VERSION "created by canmatrix"

NS_ :

BS_:

BU_: RadarRearRight RadarRearLeft

BO_ 3221225472 VECTOR__INDEPENDENT_SIG_MSG: 0 Vector__XXX
 SG_ RRL_Status_SensorState : 0|2@0+ (1,0) [0|3] "" Vector__XXX
 SG_ RR_Object_Alivecounter : 0|4@1- (1,0) [0|15] "" Vector__XXX
 SG_ RSDS_RiTgt_02 : 0|1@1+ (1,0) [0|1] "" Vector__XXX
 SG_ RSDS_RiTgt_01 : 0|1@1+ (1,0) [0|1] "" Vector__XXX
 SG_ RSDS_MidTgt_02 : 0|1@1+ (1,0) [0|1] "" Vector__XXX
 SG_ RSDS_MidTgt_01 : 0|1@1+ (1,0) [0|1] "" Vector__XXX
 SG_ RSDS_RiTgt_02_dy : 0|7@1+ (0.1,-8) [-8|4.7] "m" Vector__XXX
 SG_ RSDS_RiTgt_02_dx : 0|10@1+ (0.1,-90) [-90|12.3] "m" Vector__XXX
 SG_ RSDS_RiTgt_01_dy : 0|7@1+ (0.1,-8) [-8|4.7] "m" Vector__XXX
 SG_ RSDS_RiTgt_01_dx : 0|10@1+ (0.1,-90) [-90|12.3] "m" Vector__XXX
 SG_ RSDS_MidTgt_02_dy : 0|7@1+ (0.1,-4) [-4|8.7] "m" Vector__XXX
 SG_ RSDS_MidTgt_02_dx : 0|10@1+ (0.1,-90) [-90|12.3] "m" Vector__XXX
 SG_ RSDS_MidTgt_01_dy : 0|7@1+ (0.1,-4) [-4|8.7] "m" Vector__XXX
 SG_ RSDS_MidTgt_01_dx : 0|10@1+ (0.1,-90) [-90|12.3] "m" Vector__XXX
 SG_ New_Signal_2741 : 0|8@1+ (1,0) [0|0] "" Vector__XXX
 SG_ New_Signal_2740 : 0|8@1+ (1,0) [0|0] "" Vector__XXX
 SG_ New_Signal_2739 : 0|8@1+ (1,0) [0|0] "" Vector__XXX
 SG_ New_Signal_2738 : 0|8@1+ (1,0) [0|0] "" Vector__XXX
 SG_ New_Signal_2737 : 0|8@1+ (1,0) [0|0] "" Vector__XXX
 SG_ New_Signal_2736 : 0|8@1+ (1,0) [0|0] "" Vector__XXX
 SG_ New_Signal_2735 : 0|8@1+ (1,0) [0|0] "" Vector__XXX
 SG_ New_Signal_2734 : 0|8@1+ (1,0) [0|0] "" Vector__XXX
 SG_ New_Signal_2733 : 0|8@1+ (1,0) [0|0] "" Vector__XXX

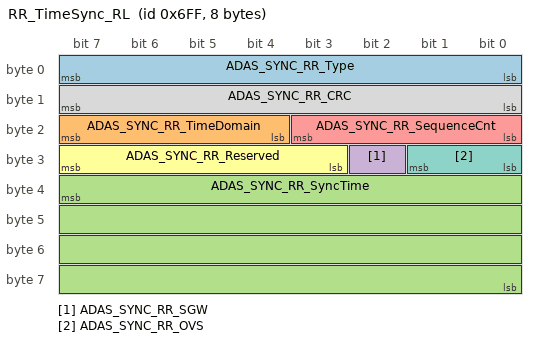
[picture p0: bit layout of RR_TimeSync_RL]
BO_ 1791 RR_TimeSync_RL: 8 RadarRearRight
 SG_ ADAS_SYNC_RR_Type : 7|8@0+ (1,0) [0|255] ""  RadarRearLeft
 SG_ ADAS_SYNC_RR_TimeDomain : 23|4@0+ (1,0) [0|15] ""  RadarRearLeft
 SG_ ADAS_SYNC_RR_SyncTime : 39|32@0+ (1,0) [0|4294967295] ""  RadarRearLeft
 SG_ ADAS_SYNC_RR_SGW : 26|1@0+ (1,0) [0|1] ""  RadarRearLeft
 SG_ ADAS_SYNC_RR_SequenceCnt : 19|4@0+ (1,0) [0|14] ""  RadarRearLeft
 SG_ ADAS_SYNC_RR_Reserved : 31|5@0+ (1,0) [0|31] ""  RadarRearLeft
 SG_ ADAS_SYNC_RR_OVS : 25|2@0+ (1,0) [0|3] ""  RadarRearLeft
 SG_ ADAS_SYNC_RR_CRC : 15|8@0+ (1,0) [0|255] ""  RadarRearLeft

BO_ 769 RRL_Object: 64 RadarRearLeft
 SG_ RSDS_RCW_MidTgt_01_Vy : 384|9@1+ (0.5,-127.5) [-127|128] "kph"  RadarRearRight
 SG_ RSDS_RCW_MidTgt_01_Vx : 368|9@1+ (0.5,-127.5) [-127|128] "kph"  RadarRearRight
 SG_ RSDS_RCW_MidTgt_01_Type : 125|3@1+ (1,0) [0|7] ""  RadarRearRight
 SG_ RSDS_RCTB_MidTgt_02_Vy : 352|9@1+ (0.5,-127.5) [-127|128] "kph"  RadarRearRight
 SG_ RSDS_RCTB_MidTgt_02_Vx : 336|9@1+ (0.5,-127.5) [-127|128] "kph"  RadarRearRight
 SG_ RSDS_RCTB_MidTgt_02_Type : 122|3@1+ (1,0) [0|7] ""  RadarRearRight
 SG_ RSDS_RCTA_LeTgt_02_Vy : 320|9@1+ (0.5,-127.5) [-127|128] "kph"  RadarRearRight
 SG_ RSDS_RCTA_LeTgt_02_Vx : 304|9@1+ (0.5,-127.5) [-127|128] "kph"  RadarRearRight
 SG_ RSDS_RCTA_LeTgt_02_Type : 109|3@1+ (1,0) [0|7] ""  RadarRearRight
 SG_ RSDS_LCA_LeTgt_01_Vy : 288|9@1+ (0.5,-127.5) [-127|128] "kph"  RadarRearRight
 SG_ RSDS_LCA_LeTgt_01_Vx : 272|9@1+ (0.5,-127.5) [-127|128] "kph"  RadarRearRight
 SG_ RSDS_LCA_LeTgt_01_Type : 37|3@1+ (1,0) [0|7] ""  RadarRearRight
 SG_ RSDS_MidTgt_01_dy_L : 235|7@1+ (0.1,-4) [-4|4] "m"  RadarRearRight
 SG_ RSDS_MidTgt_01_dx_L : 246|10@1+ (0.1,-90) [-90|5] "m"  RadarRearRight
 SG_ RSDS_MidTgt_01_L : 36|1@1+ (1,0) [0|1] "NoUnit"  RadarRearRight
 SG_ RCTA_B__L__TTC : 229|6@1+ (0.1,0) [0|6.3] "s"  RadarRearRight
 SG_ RCTB_L_State : 225|3@1+ (1,0) [0|7] "NoUnit"  RadarRearRight
 SG_ RCTA_L_State : 220|3@1+ (1,0) [0|7] "NoUnit"  RadarRearRight
 SG_ RCW_L_State : 203|3@1+ (1,0) [0|7] "NoUnit"  RadarRearRight
 SG_ DOW_L_State : 196|3@1+ (1,0) [0|7] "NoUnit"  RadarRearRight
 SG_ LCA_L_State : 188|3@1+ (1,0) [0|7] "NoUnit"  RadarRearRight
 SG_ BSD_L_State : 184|3@1+ (1,0) [0|7] "NoUnit"  RadarRearRight
 SG_ RSDS_ObjRelVelYStd_Le : 261|5@1+ (0.375,0) [0|11.625] ""  RadarRearRight
 SG_ RSDS_ObjRAccelYStd_Le : 75|5@1+ (0.375,0) [0|11.625] ""  RadarRearRight
 SG_ RSDS_ObjRAccelXStd_Le : 66|5@1+ (0.375,0) [0|11.625] ""  RadarRearRight
 SG_ RSDS_ObjRelAccelY_Le : 208|10@1+ (0.03125,-16) [-16|15.96875] ""  RadarRearRight
 SG_ RSDS_ObjRelAccelX_Le : 168|10@1+ (0.03125,-16) [-16|15.96875] ""  RadarRearRight
 SG_ RSDS_ObjRelVelXStd_Le : 152|5@1+ (0.375,0) [0|11.625] ""  RadarRearRight
 SG_ RSDS_ObjDistYStd_Le : 128|5@1+ (0.375,0) [0|11.625] ""  RadarRearRight
 SG_ RSDS_ObjDistXStd_Le : 104|5@1+ (0.375,0) [0|11.625] ""  RadarRearRight
 SG_ RSDS_LeTgt_02 : 35|1@1+ (1,0) [0|1] ""  RadarRearRight
 SG_ RSDS_LeTgt_01 : 34|1@1+ (1,0) [0|1] ""  RadarRearRight
 SG_ RSDS_LeTgt_02_dy : 80|7@1+ (0.1,0) [0|12.7] "m"  RadarRearRight
 SG_ RSDS_LeTgt_02_dx : 56|10@1+ (0.1,-90) [-90|12.3] "m"  RadarRearRight
 SG_ RSDS_LeTgt_01_dy : 40|7@1+ (0.1,0) [0|12.7] "m"  RadarRearRight
 SG_ RSDS_LeTgt_01_dx : 24|10@1+ (0.1,-90) [-90|12.3] "m"  RadarRearRight
 SG_ RRL_Status_Alivecounter : 16|8@1+ (1,0) [0|254] ""  RadarRearRight
 SG_ RRL_Status_CRC : 0|16@1+ (1,0) [0|65535] ""  RadarRearRight
 SG_ ZoneIndLe : 200|2@1+ (1,0) [0|3] ""  RadarRearRight
 SG_ ObjWidthLe : 242|3@1+ (0.5,0) [0|3.5] "m"  RadarRearRight
 SG_ ObjTTCLe : 161|7@1+ (0.1,0) [0|12.7] "s"  RadarRearRight
 SG_ ObjStsLe : 193|2@1+ (1,0) [0|3] ""  RadarRearRight
 SG_ ObjStatyLe : 207|1@1+ (1,0) [0|1] ""  RadarRearRight
 SG_ ObjLgtSpdCurvLe : 136|10@1+ (0.1,-10) [-10|92.3] "m/s"  RadarRearRight
 SG_ ObjLgtPosnCurvLe : 112|10@1+ (0.1,-92.3) [-92.3|10] "m"  RadarRearRight
 SG_ ObjLenLe : 178|4@1+ (1,0) [0|15] "m"  RadarRearRight
 SG_ ObjLatSpdCurvLe : 96|7@1+ (0.1,-6.4) [-6.4|6.3] "m/s"  RadarRearRight
 SG_ ObjLatPosnCurvLe : 88|8@1+ (0.1,-12.8) [-12.8|12.7] "m"  RadarRearRight
 SG_ ObjIDLe : 48|6@1+ (1,0) [0|63] ""  RadarRearRight
 SG_ LeTarSts : 73|2@1+ (1,0) [0|3] ""  RadarRearRight

BO_ 768 RRL_Hdr: 32 Vector__XXX
 SG_ RRL_Hdr_CRC : 0|16@1+ (1,0) [0|65535] "" Vector__XXX
 SG_ RRL_Hdr_YawAngleUpper : 105|15@1+ (0.00017,-2.78528) [-1.6|1.6] "rad" Vector__XXX
 SG_ RRL_Hdr_YawMountAngle : 120|16@1+ (0.00017,-5.57056) [-3.2|3.2] "rad" Vector__XXX
 SG_ RRL_Hdr_YawAngleLower : 136|15@1+ (0.00017,-2.78528) [-1.6|1.6] "rad" Vector__XXX
 SG_ RRL_Hdr_ElevOutOfSpec : 151|1@1+ (1,0) [0|1] "" Vector__XXX
 SG_ RRL_Hdr_PitchMountAngle : 152|12@1+ (0.00017,-0.34816) [-0.2|0.2] "rad" Vector__XXX
 SG_ RRL_Hdr_PitchAngleLower : 164|12@1+ (0.00017,-0.34816) [-0.2|0.2] "rad" Vector__XXX
 SG_ RRL_Hdr_AliveCtr : 16|8@1+ (1,0) [0|254] "" Vector__XXX
 SG_ RRL_Hdr_PitchAngleUpper : 176|12@1+ (0.00017,-0.34816) [-0.2|0.2] "rad" Vector__XXX
 SG_ RRL_Hdr_RollMountAngle : 188|12@1+ (0.00017,-0.34816) [-0.2|0.2] "rad" Vector__XXX
 SG_ RRL_Hdr_DetectionRange : 200|9@1+ (1,0) [0|511] "m" Vector__XXX
 SG_ RRL_Hdr_SensorState : 209|4@1+ (1,0) [0|15] "" Vector__XXX
 SG_ RRL_Hdr_FV : 231|8@0+ (1,0) [0|255] "" Vector__XXX
 SG_ RRL_Hdr_MAC : 239|24@0+ (1,0) [0|16777215] "" Vector__XXX
 SG_ RRL_Hdr_BlockCtr : 24|4@1+ (1,0) [0|15] "" Vector__XXX
 SG_ RRL_Hdr_ProtocolVersion : 32|16@1+ (1,0) [0|65535] "" Vector__XXX
 SG_ RRL_Hdr_ObjectCount : 48|6@1+ (1,0) [0|63] "" Vector__XXX
 SG_ RRL_Hdr_TimeSyncFailure : 54|1@1+ (1,0) [0|1] "" Vector__XXX
 SG_ RRL_Hdr_ObjectDownSel : 55|1@1+ (1,0) [0|1] "" Vector__XXX
 SG_ RRL_Hdr_MountingPosY : 56|8@1+ (0.01,-1.28) [-1.28|1.27] "m" Vector__XXX
 SG_ RRL_Hdr_AbsRefTime : 64|26@1+ (0.001,0) [0|65536] "s" Vector__XXX
 SG_ RRL_Hdr_MountingPosZ : 90|5@1+ (0.05,0) [0|1.55] "m" Vector__XXX
 SG_ RRL_Hdr_AziOutOfSpec : 95|1@1+ (1,0) [0|1] "" Vector__XXX
 SG_ RRL_Hdr_MountingPosX : 96|9@1+ (0.02,-5.12) [-5.12|5.1] "m" Vector__XXX

BO_ 784 RRL_Obj00A: 64 Vector__XXX
 SG_ RRL_Obj00A_CRC : 0|16@1+ (1,0) [0|65535] "" Vector__XXX
 SG_ RRL_Obj00A_Ay : 103|9@1+ (0.0625,-16) [-16|15.9375] "m/s^2" Vector__XXX
 SG_ RRL_Obj00A_HeadingYawAngle : 112|9@1+ (0.0175,-4.48) [-3.15|3.15] "rad" Vector__XXX
 SG_ RRL_Obj00A_Length : 121|7@1+ (0.125,0) [0|15.875] "m" Vector__XXX
 SG_ RRL_Obj00A_Width : 128|7@1+ (0.125,0) [0|15.875] "m" Vector__XXX
 SG_ RRL_Obj00A_Height : 135|7@1+ (0.125,0) [0|15.875] "m" Vector__XXX
 SG_ RRL_Obj00A_DxVnce : 142|12@1+ (0.01,0) [0|30] "m^2" Vector__XXX
 SG_ RRL_Obj00A_DyVnce : 154|12@1+ (0.01,0) [0|30] "m^2" Vector__XXX
 SG_ RRL_Obj00A_DzVnce : 166|10@1+ (0.01,0) [0|10] "m^2" Vector__XXX
 SG_ RRL_Obj00A_AliveCtr : 16|8@1+ (1,0) [0|254] "" Vector__XXX
 SG_ RRL_Obj00A_VxVnce : 176|12@1+ (0.01,0) [0|30] "m^2/s^2" Vector__XXX
 SG_ RRL_Obj00A_VyVnce : 188|12@1+ (0.01,0) [0|30] "m^2/s^2" Vector__XXX
 SG_ RRL_Obj00A_AxVnce : 200|12@1+ (0.01,0) [0|30] "m^2/s^4" Vector__XXX
 SG_ RRL_Obj00A_AyVnce : 212|12@1+ (0.01,0) [0|30] "m^2/s^4" Vector__XXX
 SG_ RRL_Obj00A_RefPosIndex : 224|4@1+ (1,0) [0|15] "" Vector__XXX
 SG_ RRL_Obj00A_DxDyCoVnce : 228|12@1+ (0.01,0) [0|30] "m^2" Vector__XXX
 SG_ RRL_Obj00A_DxVxCoVnce : 240|12@1+ (0.01,0) [0|30] "m^2/s" Vector__XXX
 SG_ RRL_Obj00A_BlockCtr : 24|4@1+ (1,0) [0|15] "" Vector__XXX
 SG_ RRL_Obj00A_DyVxCoVnce : 252|12@1+ (0.01,0) [0|30] "m^2/s" Vector__XXX
 SG_ RRL_Obj00A_DxVyCoVnce : 264|12@1+ (0.01,0) [0|30] "m^2/s" Vector__XXX
 SG_ RRL_Obj00A_DyVyCoVnce : 276|12@1+ (0.01,0) [0|30] "m^2/s" Vector__XXX
 SG_ RRL_Obj00A_VxVyCoVnce : 288|12@1+ (0.01,0) [0|30] "m^2/s^2" Vector__XXX
 SG_ RRL_Obj00A_DxAxCoVnce : 300|12@1+ (0.01,0) [0|30] "m^2/s^2" Vector__XXX
 SG_ RRL_Obj00A_DyAxCoVnce : 312|12@1+ (0.01,0) [0|30] "m^2/s^2" Vector__XXX
 SG_ RRL_Obj00A_VxAxCoVnce : 324|12@1+ (0.01,0) [0|30] "m^2/s^3" Vector__XXX
 SG_ RRL_Obj00A_ObjectID : 32|7@1+ (1,0) [0|127] "" Vector__XXX
 SG_ RRL_Obj00A_VyAxCoVnce : 336|12@1+ (0.01,0) [0|30] "m^2/s^3" Vector__XXX
 SG_ RRL_Obj00A_DxAyCoVnce : 348|12@1+ (0.01,0) [0|30] "m^2/s^2" Vector__XXX
 SG_ RRL_Obj00A_DyAyCoVnce : 360|12@1+ (0.01,0) [0|30] "m^2/s^2" Vector__XXX
 SG_ RRL_Obj00A_VxAyCoVnce : 372|12@1+ (0.01,0) [0|30] "m^2/s^3" Vector__XXX
 SG_ RRL_Obj00A_VyAyCoVnce : 384|12@1+ (0.01,0) [0|30] "m^2/s^3" Vector__XXX
 SG_ RRL_Obj00A_AxAyCoVnce : 396|12@1+ (0.01,0) [0|30] "m^2/s^4" Vector__XXX
 SG_ RRL_Obj00A_Measured : 39|1@1+ (1,0) [0|1] "" Vector__XXX
 SG_ RRL_Obj00A_HeadingYawVnce : 408|12@1+ (0.0003,0) [0|1] "rad^2" Vector__XXX
 SG_ RRL_Obj00A_Dx : 40|13@1+ (0.0625,-256) [-256|255.9375] "m" Vector__XXX
 SG_ RRL_Obj00A_LengthVnce : 420|12@1+ (0.01,0) [0|30] "m^2" Vector__XXX
 SG_ RRL_Obj00A_WidthVnce : 432|12@1+ (0.01,0) [0|30] "m^2" Vector__XXX
 SG_ RRL_Obj00A_HeightVnce : 444|12@1+ (0.01,0) [0|30] "m^2" Vector__XXX
 SG_ RRL_Obj00A_ExistProb : 456|6@1+ (2,0) [0|100] "%" Vector__XXX
 SG_ RRL_Obj00A_ProbObstacle : 462|6@1+ (2,0) [0|100] "%" Vector__XXX
 SG_ RRL_Obj00A_ProbNonObstacle : 468|6@1+ (2,0) [0|100] "%" Vector__XXX
 SG_ RRL_Obj00A_ProbMobileObst : 474|6@1+ (2,0) [0|100] "%" Vector__XXX
 SG_ RRL_Obj00A_FV : 487|8@0+ (1,0) [0|255] "" Vector__XXX
 SG_ RRL_Obj00A_MAC : 495|24@0+ (1,0) [0|16777215] "" Vector__XXX
 SG_ RRL_Obj00A_Dz : 53|6@1+ (0.25,-5) [-5|10.75] "m" Vector__XXX
 SG_ RRL_Obj00A_Dy : 59|11@1+ (0.125,-128) [-128|127.875] "m" Vector__XXX
 SG_ RRL_Obj00A_Valid : 70|1@1+ (1,0) [0|1] "" Vector__XXX
 SG_ RRL_Obj00A_Vx : 71|12@1+ (0.0625,-128) [-128|127.9375] "m/s" Vector__XXX
 SG_ RRL_Obj00A_Vy : 83|10@1+ (0.125,-64) [-64|63.875] "m/s" Vector__XXX
 SG_ RRL_Obj00A_Ax : 93|10@1+ (0.03125,-16) [-16|15.96875] "m/s^2" Vector__XXX

BO_ 785 RRL_Obj00B: 16 Vector__XXX
 SG_ RRL_Obj00B_CRC : 0|16@1+ (1,0) [0|65535] "" Vector__XXX
 SG_ RRL_Obj00B_MAC : 111|24@0+ (1,0) [0|16777215] "" Vector__XXX
 SG_ RRL_Obj00B_AliveCtr : 16|8@1+ (1,0) [0|254] "" Vector__XXX
 SG_ RRL_Obj00B_BlockCtr : 24|4@1+ (1,0) [0|15] "" Vector__XXX
 SG_ RRL_Obj00B_ProbMob4PlusWhl : 28|6@1+ (2,0) [0|100] "%" Vector__XXX
 SG_ RRL_Obj00B_ProbMob2Whl : 34|6@1+ (2,0) [0|100] "%" Vector__XXX
 SG_ RRL_Obj00B_ProbMobPed : 40|6@1+ (2,0) [0|100] "%" Vector__XXX
 SG_ RRL_Obj00B_Prob4PlusWhlCAR : 46|6@1+ (2,0) [0|100] "%" Vector__XXX
 SG_ RRL_Obj00B_Prob4PlusWhlbHGV : 52|6@1+ (2,0) [0|100] "%" Vector__XXX
 SG_ RRL_Obj00B_ProbGNDReflex : 58|6@1+ (2,0) [0|100] "%" Vector__XXX
 SG_ RRL_Obj00B_ProbStatBarrier : 64|6@1+ (2,0) [0|100] "%" Vector__XXX
 SG_ RRL_Obj00B_ProbStatObst : 70|6@1+ (2,0) [0|100] "%" Vector__XXX
 SG_ RRL_Obj00B_MovingProbability : 76|6@1+ (2,0) [0|100] "%" Vector__XXX
 SG_ RRL_Obj00B_MovingObserved : 82|6@1+ (2,0) [0|100] "%" Vector__XXX
 SG_ RRL_Obj00B_FV : 103|8@0+ (1,0) [0|255] "" Vector__XXX

BO_ 786 RRL_Obj01A: 64 Vector__XXX
 SG_ RRL_Obj01A_CRC : 0|16@1+ (1,0) [0|65535] "" Vector__XXX
 SG_ RRL_Obj01A_Ay : 103|9@1+ (0.0625,-16) [-16|15.9375] "m/s^2" Vector__XXX
 SG_ RRL_Obj01A_HeadingYawAngle : 112|9@1+ (0.0175,-4.48) [-3.15|3.15] "rad" Vector__XXX
 SG_ RRL_Obj01A_Length : 121|7@1+ (0.125,0) [0|15.875] "m" Vector__XXX
 SG_ RRL_Obj01A_Width : 128|7@1+ (0.125,0) [0|15.875] "m" Vector__XXX
 SG_ RRL_Obj01A_Height : 135|7@1+ (0.125,0) [0|15.875] "m" Vector__XXX
 SG_ RRL_Obj01A_DxVnce : 142|12@1+ (0.01,0) [0|30] "m^2" Vector__XXX
 SG_ RRL_Obj01A_DyVnce : 154|12@1+ (0.01,0) [0|30] "m^2" Vector__XXX
 SG_ RRL_Obj01A_DzVnce : 166|10@1+ (0.01,0) [0|10] "m^2" Vector__XXX
 SG_ RRL_Obj01A_AliveCtr : 16|8@1+ (1,0) [0|254] "" Vector__XXX
 SG_ RRL_Obj01A_VxVnce : 176|12@1+ (0.01,0) [0|30] "m^2/s^2" Vector__XXX
 SG_ RRL_Obj01A_VyVnce : 188|12@1+ (0.01,0) [0|30] "m^2/s^2" Vector__XXX
 SG_ RRL_Obj01A_AxVnce : 200|12@1+ (0.01,0) [0|30] "m^2/s^4" Vector__XXX
 SG_ RRL_Obj01A_AyVnce : 212|12@1+ (0.01,0) [0|30] "m^2/s^4" Vector__XXX
 SG_ RRL_Obj01A_RefPosIndex : 224|4@1+ (1,0) [0|15] "" Vector__XXX
 SG_ RRL_Obj01A_DxDyCoVnce : 228|12@1+ (0.01,0) [0|30] "m^2" Vector__XXX
 SG_ RRL_Obj01A_DxVxCoVnce : 240|12@1+ (0.01,0) [0|30] "m^2/s" Vector__XXX
 SG_ RRL_Obj01A_BlockCtr : 24|4@1+ (1,0) [0|15] "" Vector__XXX
 SG_ RRL_Obj01A_DyVxCoVnce : 252|12@1+ (0.01,0) [0|30] "m^2/s" Vector__XXX
 SG_ RRL_Obj01A_DxVyCoVnce : 264|12@1+ (0.01,0) [0|30] "m^2/s" Vector__XXX
 SG_ RRL_Obj01A_DyVyCoVnce : 276|12@1+ (0.01,0) [0|30] "m^2/s" Vector__XXX
 SG_ RRL_Obj01A_VxVyCoVnce : 288|12@1+ (0.01,0) [0|30] "m^2/s^2" Vector__XXX
 SG_ RRL_Obj01A_DxAxCoVnce : 300|12@1+ (0.01,0) [0|30] "m^2/s^2" Vector__XXX
 SG_ RRL_Obj01A_DyAxCoVnce : 312|12@1+ (0.01,0) [0|30] "m^2/s^2" Vector__XXX
 SG_ RRL_Obj01A_VxAxCoVnce : 324|12@1+ (0.01,0) [0|30] "m^2/s^3" Vector__XXX
 SG_ RRL_Obj01A_ObjectID : 32|7@1+ (1,0) [0|127] "" Vector__XXX
 SG_ RRL_Obj01A_VyAxCoVnce : 336|12@1+ (0.01,0) [0|30] "m^2/s^3" Vector__XXX
 SG_ RRL_Obj01A_DxAyCoVnce : 348|12@1+ (0.01,0) [0|30] "m^2/s^2" Vector__XXX
 SG_ RRL_Obj01A_DyAyCoVnce : 360|12@1+ (0.01,0) [0|30] "m^2/s^2" Vector__XXX
 SG_ RRL_Obj01A_VxAyCoVnce : 372|12@1+ (0.01,0) [0|30] "m^2/s^3" Vector__XXX
 SG_ RRL_Obj01A_VyAyCoVnce : 384|12@1+ (0.01,0) [0|30] "m^2/s^3" Vector__XXX
 SG_ RRL_Obj01A_AxAyCoVnce : 396|12@1+ (0.01,0) [0|30] "m^2/s^4" Vector__XXX
 SG_ RRL_Obj01A_Measured : 39|1@1+ (1,0) [0|1] "" Vector__XXX
 SG_ RRL_Obj01A_HeadingYawVnce : 408|12@1+ (0.0003,0) [0|1] "rad^2" Vector__XXX
 SG_ RRL_Obj01A_Dx : 40|13@1+ (0.0625,-256) [-256|255.9375] "m" Vector__XXX
 SG_ RRL_Obj01A_LengthVnce : 420|12@1+ (0.01,0) [0|30] "m^2" Vector__XXX
 SG_ RRL_Obj01A_WidthVnce : 432|12@1+ (0.01,0) [0|30] "m^2" Vector__XXX
 SG_ RRL_Obj01A_HeightVnce : 444|12@1+ (0.01,0) [0|30] "m^2" Vector__XXX
 SG_ RRL_Obj01A_ExistProb : 456|6@1+ (2,0) [0|100] "%" Vector__XXX
 SG_ RRL_Obj01A_ProbObstacle : 462|6@1+ (2,0) [0|100] "%" Vector__XXX
 SG_ RRL_Obj01A_ProbNonObstacle : 468|6@1+ (2,0) [0|100] "%" Vector__XXX
 SG_ RRL_Obj01A_ProbMobileObst : 474|6@1+ (2,0) [0|100] "%" Vector__XXX
 SG_ RRL_Obj01A_FV : 487|8@0+ (1,0) [0|255] "" Vector__XXX
 SG_ RRL_Obj01A_MAC : 495|24@0+ (1,0) [0|16777215] "" Vector__XXX
 SG_ RRL_Obj01A_Dz : 53|6@1+ (0.25,-5) [-5|10.75] "m" Vector__XXX
 SG_ RRL_Obj01A_Dy : 59|11@1+ (0.125,-128) [-128|127.875] "m" Vector__XXX
 SG_ RRL_Obj01A_Valid : 70|1@1+ (1,0) [0|1] "" Vector__XXX
 SG_ RRL_Obj01A_Vx : 71|12@1+ (0.0625,-128) [-128|127.9375] "m/s" Vector__XXX
 SG_ RRL_Obj01A_Vy : 83|10@1+ (0.125,-64) [-64|63.875] "m/s" Vector__XXX
 SG_ RRL_Obj01A_Ax : 93|10@1+ (0.03125,-16) [-16|15.96875] "m/s^2" Vector__XXX

BO_ 787 RRL_Obj01B: 16 Vector__XXX
 SG_ RRL_Obj01B_CRC : 0|16@1+ (1,0) [0|65535] "" Vector__XXX
 SG_ RRL_Obj01B_MAC : 111|24@0+ (1,0) [0|16777215] "" Vector__XXX
 SG_ RRL_Obj01B_AliveCtr : 16|8@1+ (1,0) [0|254] "" Vector__XXX
 SG_ RRL_Obj01B_BlockCtr : 24|4@1+ (1,0) [0|15] "" Vector__XXX
 SG_ RRL_Obj01B_ProbMob4PlusWhl : 28|6@1+ (2,0) [0|100] "%" Vector__XXX
 SG_ RRL_Obj01B_ProbMob2Whl : 34|6@1+ (2,0) [0|100] "%" Vector__XXX
 SG_ RRL_Obj01B_ProbMobPed : 40|6@1+ (2,0) [0|100] "%" Vector__XXX
 SG_ RRL_Obj01B_Prob4PlusWhlCAR : 46|6@1+ (2,0) [0|100] "%" Vector__XXX
 SG_ RRL_Obj01B_Prob4PlusWhlbHGV : 52|6@1+ (2,0) [0|100] "%" Vector__XXX
 SG_ RRL_Obj01B_ProbGNDReflex : 58|6@1+ (2,0) [0|100] "%" Vector__XXX
 SG_ RRL_Obj01B_ProbStatBarrier : 64|6@1+ (2,0) [0|100] "%" Vector__XXX
 SG_ RRL_Obj01B_ProbStatObst : 70|6@1+ (2,0) [0|100] "%" Vector__XXX
 SG_ RRL_Obj01B_MovingProbability : 76|6@1+ (2,0) [0|100] "%" Vector__XXX
 SG_ RRL_Obj01B_MovingObserved : 82|6@1+ (2,0) [0|100] "%" Vector__XXX
 SG_ RRL_Obj01B_FV : 103|8@0+ (1,0) [0|255] "" Vector__XXX

BO_ 788 RRL_Obj02A: 64 Vector__XXX
 SG_ RRL_Obj02A_CRC : 0|16@1+ (1,0) [0|65535] "" Vector__XXX
 SG_ RRL_Obj02A_Ay : 103|9@1+ (0.0625,-16) [-16|15.9375] "m/s^2" Vector__XXX
 SG_ RRL_Obj02A_HeadingYawAngle : 112|9@1+ (0.0175,-4.48) [-3.15|3.15] "rad" Vector__XXX
 SG_ RRL_Obj02A_Length : 121|7@1+ (0.125,0) [0|15.875] "m" Vector__XXX
 SG_ RRL_Obj02A_Width : 128|7@1+ (0.125,0) [0|15.875] "m" Vector__XXX
 SG_ RRL_Obj02A_Height : 135|7@1+ (0.125,0) [0|15.875] "m" Vector__XXX
 SG_ RRL_Obj02A_DxVnce : 142|12@1+ (0.01,0) [0|30] "m^2" Vector__XXX
 SG_ RRL_Obj02A_DyVnce : 154|12@1+ (0.01,0) [0|30] "m^2" Vector__XXX
 SG_ RRL_Obj02A_DzVnce : 166|10@1+ (0.01,0) [0|10] "m^2" Vector__XXX
 SG_ RRL_Obj02A_AliveCtr : 16|8@1+ (1,0) [0|254] "" Vector__XXX
 SG_ RRL_Obj02A_VxVnce : 176|12@1+ (0.01,0) [0|30] "m^2/s^2" Vector__XXX
 SG_ RRL_Obj02A_VyVnce : 188|12@1+ (0.01,0) [0|30] "m^2/s^2" Vector__XXX
 SG_ RRL_Obj02A_AxVnce : 200|12@1+ (0.01,0) [0|30] "m^2/s^4" Vector__XXX
 SG_ RRL_Obj02A_AyVnce : 212|12@1+ (0.01,0) [0|30] "m^2/s^4" Vector__XXX
 SG_ RRL_Obj02A_RefPosIndex : 224|4@1+ (1,0) [0|15] "" Vector__XXX
 SG_ RRL_Obj02A_DxDyCoVnce : 228|12@1+ (0.01,0) [0|30] "m^2" Vector__XXX
 SG_ RRL_Obj02A_DxVxCoVnce : 240|12@1+ (0.01,0) [0|30] "m^2/s" Vector__XXX
 SG_ RRL_Obj02A_BlockCtr : 24|4@1+ (1,0) [0|15] "" Vector__XXX
 SG_ RRL_Obj02A_DyVxCoVnce : 252|12@1+ (0.01,0) [0|30] "m^2/s" Vector__XXX
 SG_ RRL_Obj02A_DxVyCoVnce : 264|12@1+ (0.01,0) [0|30] "m^2/s" Vector__XXX
 SG_ RRL_Obj02A_DyVyCoVnce : 276|12@1+ (0.01,0) [0|30] "m^2/s" Vector__XXX
 SG_ RRL_Obj02A_VxVyCoVnce : 288|12@1+ (0.01,0) [0|30] "m^2/s^2" Vector__XXX
 SG_ RRL_Obj02A_DxAxCoVnce : 300|12@1+ (0.01,0) [0|30] "m^2/s^2" Vector__XXX
 SG_ RRL_Obj02A_DyAxCoVnce : 312|12@1+ (0.01,0) [0|30] "m^2/s^2" Vector__XXX
 SG_ RRL_Obj02A_VxAxCoVnce : 324|12@1+ (0.01,0) [0|30] "m^2/s^3" Vector__XXX
 SG_ RRL_Obj02A_ObjectID : 32|7@1+ (1,0) [0|127] "" Vector__XXX
 SG_ RRL_Obj02A_VyAxCoVnce : 336|12@1+ (0.01,0) [0|30] "m^2/s^3" Vector__XXX
 SG_ RRL_Obj02A_DxAyCoVnce : 348|12@1+ (0.01,0) [0|30] "m^2/s^2" Vector__XXX
 SG_ RRL_Obj02A_DyAyCoVnce : 360|12@1+ (0.01,0) [0|30] "m^2/s^2" Vector__XXX
 SG_ RRL_Obj02A_VxAyCoVnce : 372|12@1+ (0.01,0) [0|30] "m^2/s^3" Vector__XXX
 SG_ RRL_Obj02A_VyAyCoVnce : 384|12@1+ (0.01,0) [0|30] "m^2/s^3" Vector__XXX
 SG_ RRL_Obj02A_AxAyCoVnce : 396|12@1+ (0.01,0) [0|30] "m^2/s^4" Vector__XXX
 SG_ RRL_Obj02A_Measured : 39|1@1+ (1,0) [0|1] "" Vector__XXX
 SG_ RRL_Obj02A_HeadingYawVnce : 408|12@1+ (0.0003,0) [0|1] "rad^2" Vector__XXX
 SG_ RRL_Obj02A_Dx : 40|13@1+ (0.0625,-256) [-256|255.9375] "m" Vector__XXX
 SG_ RRL_Obj02A_LengthVnce : 420|12@1+ (0.01,0) [0|30] "m^2" Vector__XXX
 SG_ RRL_Obj02A_WidthVnce : 432|12@1+ (0.01,0) [0|30] "m^2" Vector__XXX
 SG_ RRL_Obj02A_HeightVnce : 444|12@1+ (0.01,0) [0|30] "m^2" Vector__XXX
 SG_ RRL_Obj02A_ExistProb : 456|6@1+ (2,0) [0|100] "%" Vector__XXX
 SG_ RRL_Obj02A_ProbObstacle : 462|6@1+ (2,0) [0|100] "%" Vector__XXX
 SG_ RRL_Obj02A_ProbNonObstacle : 468|6@1+ (2,0) [0|100] "%" Vector__XXX
 SG_ RRL_Obj02A_ProbMobileObst : 474|6@1+ (2,0) [0|100] "%" Vector__XXX
 SG_ RRL_Obj02A_FV : 487|8@0+ (1,0) [0|255] "" Vector__XXX
 SG_ RRL_Obj02A_MAC : 495|24@0+ (1,0) [0|16777215] "" Vector__XXX
 SG_ RRL_Obj02A_Dz : 53|6@1+ (0.25,-5) [-5|10.75] "m" Vector__XXX
 SG_ RRL_Obj02A_Dy : 59|11@1+ (0.125,-128) [-128|127.875] "m" Vector__XXX
 SG_ RRL_Obj02A_Valid : 70|1@1+ (1,0) [0|1] "" Vector__XXX
 SG_ RRL_Obj02A_Vx : 71|12@1+ (0.0625,-128) [-128|127.9375] "m/s" Vector__XXX
 SG_ RRL_Obj02A_Vy : 83|10@1+ (0.125,-64) [-64|63.875] "m/s" Vector__XXX
 SG_ RRL_Obj02A_Ax : 93|10@1+ (0.03125,-16) [-16|15.96875] "m/s^2" Vector__XXX

BO_ 789 RRL_Obj02B: 16 Vector__XXX
 SG_ RRL_Obj02B_CRC : 0|16@1+ (1,0) [0|65535] "" Vector__XXX
 SG_ RRL_Obj02B_MAC : 111|24@0+ (1,0) [0|16777215] "" Vector__XXX
 SG_ RRL_Obj02B_AliveCtr : 16|8@1+ (1,0) [0|254] "" Vector__XXX
 SG_ RRL_Obj02B_BlockCtr : 24|4@1+ (1,0) [0|15] "" Vector__XXX
 SG_ RRL_Obj02B_ProbMob4PlusWhl : 28|6@1+ (2,0) [0|100] "%" Vector__XXX
 SG_ RRL_Obj02B_ProbMob2Whl : 34|6@1+ (2,0) [0|100] "%" Vector__XXX
 SG_ RRL_Obj02B_ProbMobPed : 40|6@1+ (2,0) [0|100] "%" Vector__XXX
 SG_ RRL_Obj02B_Prob4PlusWhlCAR : 46|6@1+ (2,0) [0|100] "%" Vector__XXX
 SG_ RRL_Obj02B_Prob4PlusWhlbHGV : 52|6@1+ (2,0) [0|100] "%" Vector__XXX
 SG_ RRL_Obj02B_ProbGNDReflex : 58|6@1+ (2,0) [0|100] "%" Vector__XXX
 SG_ RRL_Obj02B_ProbStatBarrier : 64|6@1+ (2,0) [0|100] "%" Vector__XXX
 SG_ RRL_Obj02B_ProbStatObst : 70|6@1+ (2,0) [0|100] "%" Vector__XXX
 SG_ RRL_Obj02B_MovingProbability : 76|6@1+ (2,0) [0|100] "%" Vector__XXX
 SG_ RRL_Obj02B_MovingObserved : 82|6@1+ (2,0) [0|100] "%" Vector__XXX
 SG_ RRL_Obj02B_FV : 103|8@0+ (1,0) [0|255] "" Vector__XXX

BO_ 790 RRL_Obj03A: 64 Vector__XXX
 SG_ RRL_Obj03A_CRC : 0|16@1+ (1,0) [0|65535] "" Vector__XXX
 SG_ RRL_Obj03A_Ay : 103|9@1+ (0.0625,-16) [-16|15.9375] "m/s^2" Vector__XXX
 SG_ RRL_Obj03A_HeadingYawAngle : 112|9@1+ (0.0175,-4.48) [-3.15|3.15] "rad" Vector__XXX
 SG_ RRL_Obj03A_Length : 121|7@1+ (0.125,0) [0|15.875] "m" Vector__XXX
 SG_ RRL_Obj03A_Width : 128|7@1+ (0.125,0) [0|15.875] "m" Vector__XXX
 SG_ RRL_Obj03A_Height : 135|7@1+ (0.125,0) [0|15.875] "m" Vector__XXX
 SG_ RRL_Obj03A_DxVnce : 142|12@1+ (0.01,0) [0|30] "m^2" Vector__XXX
 SG_ RRL_Obj03A_DyVnce : 154|12@1+ (0.01,0) [0|30] "m^2" Vector__XXX
 SG_ RRL_Obj03A_DzVnce : 166|10@1+ (0.01,0) [0|10] "m^2" Vector__XXX
 SG_ RRL_Obj03A_AliveCtr : 16|8@1+ (1,0) [0|254] "" Vector__XXX
 SG_ RRL_Obj03A_VxVnce : 176|12@1+ (0.01,0) [0|30] "m^2/s^2" Vector__XXX
 SG_ RRL_Obj03A_VyVnce : 188|12@1+ (0.01,0) [0|30] "m^2/s^2" Vector__XXX
 SG_ RRL_Obj03A_AxVnce : 200|12@1+ (0.01,0) [0|30] "m^2/s^4" Vector__XXX
 SG_ RRL_Obj03A_AyVnce : 212|12@1+ (0.01,0) [0|30] "m^2/s^4" Vector__XXX
 SG_ RRL_Obj03A_RefPosIndex : 224|4@1+ (1,0) [0|15] "" Vector__XXX
 SG_ RRL_Obj03A_DxDyCoVnce : 228|12@1+ (0.01,0) [0|30] "m^2" Vector__XXX
 SG_ RRL_Obj03A_DxVxCoVnce : 240|12@1+ (0.01,0) [0|30] "m^2/s" Vector__XXX
 SG_ RRL_Obj03A_BlockCtr : 24|4@1+ (1,0) [0|15] "" Vector__XXX
 SG_ RRL_Obj03A_DyVxCoVnce : 252|12@1+ (0.01,0) [0|30] "m^2/s" Vector__XXX
 SG_ RRL_Obj03A_DxVyCoVnce : 264|12@1+ (0.01,0) [0|30] "m^2/s" Vector__XXX
 SG_ RRL_Obj03A_DyVyCoVnce : 276|12@1+ (0.01,0) [0|30] "m^2/s" Vector__XXX
 SG_ RRL_Obj03A_VxVyCoVnce : 288|12@1+ (0.01,0) [0|30] "m^2/s^2" Vector__XXX
 SG_ RRL_Obj03A_DxAxCoVnce : 300|12@1+ (0.01,0) [0|30] "m^2/s^2" Vector__XXX
 SG_ RRL_Obj03A_DyAxCoVnce : 312|12@1+ (0.01,0) [0|30] "m^2/s^2" Vector__XXX
 SG_ RRL_Obj03A_VxAxCoVnce : 324|12@1+ (0.01,0) [0|30] "m^2/s^3" Vector__XXX
 SG_ RRL_Obj03A_ObjectID : 32|7@1+ (1,0) [0|127] "" Vector__XXX
 SG_ RRL_Obj03A_VyAxCoVnce : 336|12@1+ (0.01,0) [0|30] "m^2/s^3" Vector__XXX
 SG_ RRL_Obj03A_DxAyCoVnce : 348|12@1+ (0.01,0) [0|30] "m^2/s^2" Vector__XXX
 SG_ RRL_Obj03A_DyAyCoVnce : 360|12@1+ (0.01,0) [0|30] "m^2/s^2" Vector__XXX
 SG_ RRL_Obj03A_VxAyCoVnce : 372|12@1+ (0.01,0) [0|30] "m^2/s^3" Vector__XXX
 SG_ RRL_Obj03A_VyAyCoVnce : 384|12@1+ (0.01,0) [0|30] "m^2/s^3" Vector__XXX
 SG_ RRL_Obj03A_AxAyCoVnce : 396|12@1+ (0.01,0) [0|30] "m^2/s^4" Vector__XXX
 SG_ RRL_Obj03A_Measured : 39|1@1+ (1,0) [0|1] "" Vector__XXX
 SG_ RRL_Obj03A_HeadingYawVnce : 408|12@1+ (0.0003,0) [0|1] "rad^2" Vector__XXX
 SG_ RRL_Obj03A_Dx : 40|13@1+ (0.0625,-256) [-256|255.9375] "m" Vector__XXX
 SG_ RRL_Obj03A_LengthVnce : 420|12@1+ (0.01,0) [0|30] "m^2" Vector__XXX
 SG_ RRL_Obj03A_WidthVnce : 432|12@1+ (0.01,0) [0|30] "m^2" Vector__XXX
 SG_ RRL_Obj03A_HeightVnce : 444|12@1+ (0.01,0) [0|30] "m^2" Vector__XXX
 SG_ RRL_Obj03A_ExistProb : 456|6@1+ (2,0) [0|100] "%" Vector__XXX
 SG_ RRL_Obj03A_ProbObstacle : 462|6@1+ (2,0) [0|100] "%" Vector__XXX
 SG_ RRL_Obj03A_ProbNonObstacle : 468|6@1+ (2,0) [0|100] "%" Vector__XXX
 SG_ RRL_Obj03A_ProbMobileObst : 474|6@1+ (2,0) [0|100] "%" Vector__XXX
 SG_ RRL_Obj03A_FV : 487|8@0+ (1,0) [0|255] "" Vector__XXX
 SG_ RRL_Obj03A_MAC : 495|24@0+ (1,0) [0|16777215] "" Vector__XXX
 SG_ RRL_Obj03A_Dz : 53|6@1+ (0.25,-5) [-5|10.75] "m" Vector__XXX
 SG_ RRL_Obj03A_Dy : 59|11@1+ (0.125,-128) [-128|127.875] "m" Vector__XXX
 SG_ RRL_Obj03A_Valid : 70|1@1+ (1,0) [0|1] "" Vector__XXX
 SG_ RRL_Obj03A_Vx : 71|12@1+ (0.0625,-128) [-128|127.9375] "m/s" Vector__XXX
 SG_ RRL_Obj03A_Vy : 83|10@1+ (0.125,-64) [-64|63.875] "m/s" Vector__XXX
 SG_ RRL_Obj03A_Ax : 93|10@1+ (0.03125,-16) [-16|15.96875] "m/s^2" Vector__XXX

BO_ 791 RRL_Obj03B: 16 Vector__XXX
 SG_ RRL_Obj03B_CRC : 0|16@1+ (1,0) [0|65535] "" Vector__XXX
 SG_ RRL_Obj03B_MAC : 111|24@0+ (1,0) [0|16777215] "" Vector__XXX
 SG_ RRL_Obj03B_AliveCtr : 16|8@1+ (1,0) [0|254] "" Vector__XXX
 SG_ RRL_Obj03B_BlockCtr : 24|4@1+ (1,0) [0|15] "" Vector__XXX
 SG_ RRL_Obj03B_ProbMob4PlusWhl : 28|6@1+ (2,0) [0|100] "%" Vector__XXX
 SG_ RRL_Obj03B_ProbMob2Whl : 34|6@1+ (2,0) [0|100] "%" Vector__XXX
 SG_ RRL_Obj03B_ProbMobPed : 40|6@1+ (2,0) [0|100] "%" Vector__XXX
 SG_ RRL_Obj03B_Prob4PlusWhlCAR : 46|6@1+ (2,0) [0|100] "%" Vector__XXX
 SG_ RRL_Obj03B_Prob4PlusWhlbHGV : 52|6@1+ (2,0) [0|100] "%" Vector__XXX
 SG_ RRL_Obj03B_ProbGNDReflex : 58|6@1+ (2,0) [0|100] "%" Vector__XXX
 SG_ RRL_Obj03B_ProbStatBarrier : 64|6@1+ (2,0) [0|100] "%" Vector__XXX
 SG_ RRL_Obj03B_ProbStatObst : 70|6@1+ (2,0) [0|100] "%" Vector__XXX
 SG_ RRL_Obj03B_MovingProbability : 76|6@1+ (2,0) [0|100] "%" Vector__XXX
 SG_ RRL_Obj03B_MovingObserved : 82|6@1+ (2,0) [0|100] "%" Vector__XXX
 SG_ RRL_Obj03B_FV : 103|8@0+ (1,0) [0|255] "" Vector__XXX

BO_ 792 RRL_Obj04A: 64 Vector__XXX
 SG_ RRL_Obj04A_CRC : 0|16@1+ (1,0) [0|65535] "" Vector__XXX
 SG_ RRL_Obj04A_Ay : 103|9@1+ (0.0625,-16) [-16|15.9375] "m/s^2" Vector__XXX
 SG_ RRL_Obj04A_HeadingYawAngle : 112|9@1+ (0.0175,-4.48) [-3.15|3.15] "rad" Vector__XXX
 SG_ RRL_Obj04A_Length : 121|7@1+ (0.125,0) [0|15.875] "m" Vector__XXX
 SG_ RRL_Obj04A_Width : 128|7@1+ (0.125,0) [0|15.875] "m" Vector__XXX
 SG_ RRL_Obj04A_Height : 135|7@1+ (0.125,0) [0|15.875] "m" Vector__XXX
 SG_ RRL_Obj04A_DxVnce : 142|12@1+ (0.01,0) [0|30] "m^2" Vector__XXX
 SG_ RRL_Obj04A_DyVnce : 154|12@1+ (0.01,0) [0|30] "m^2" Vector__XXX
 SG_ RRL_Obj04A_DzVnce : 166|10@1+ (0.01,0) [0|10] "m^2" Vector__XXX
 SG_ RRL_Obj04A_AliveCtr : 16|8@1+ (1,0) [0|254] "" Vector__XXX
 SG_ RRL_Obj04A_VxVnce : 176|12@1+ (0.01,0) [0|30] "m^2/s^2" Vector__XXX
 SG_ RRL_Obj04A_VyVnce : 188|12@1+ (0.01,0) [0|30] "m^2/s^2" Vector__XXX
 SG_ RRL_Obj04A_AxVnce : 200|12@1+ (0.01,0) [0|30] "m^2/s^4" Vector__XXX
 SG_ RRL_Obj04A_AyVnce : 212|12@1+ (0.01,0) [0|30] "m^2/s^4" Vector__XXX
 SG_ RRL_Obj04A_RefPosIndex : 224|4@1+ (1,0) [0|15] "" Vector__XXX
 SG_ RRL_Obj04A_DxDyCoVnce : 228|12@1+ (0.01,0) [0|30] "m^2" Vector__XXX
 SG_ RRL_Obj04A_DxVxCoVnce : 240|12@1+ (0.01,0) [0|30] "m^2/s" Vector__XXX
 SG_ RRL_Obj04A_BlockCtr : 24|4@1+ (1,0) [0|15] "" Vector__XXX
 SG_ RRL_Obj04A_DyVxCoVnce : 252|12@1+ (0.01,0) [0|30] "m^2/s" Vector__XXX
 SG_ RRL_Obj04A_DxVyCoVnce : 264|12@1+ (0.01,0) [0|30] "m^2/s" Vector__XXX
 SG_ RRL_Obj04A_DyVyCoVnce : 276|12@1+ (0.01,0) [0|30] "m^2/s" Vector__XXX
 SG_ RRL_Obj04A_VxVyCoVnce : 288|12@1+ (0.01,0) [0|30] "m^2/s^2" Vector__XXX
 SG_ RRL_Obj04A_DxAxCoVnce : 300|12@1+ (0.01,0) [0|30] "m^2/s^2" Vector__XXX
 SG_ RRL_Obj04A_DyAxCoVnce : 312|12@1+ (0.01,0) [0|30] "m^2/s^2" Vector__XXX
 SG_ RRL_Obj04A_VxAxCoVnce : 324|12@1+ (0.01,0) [0|30] "m^2/s^3" Vector__XXX
 SG_ RRL_Obj04A_ObjectID : 32|7@1+ (1,0) [0|127] "" Vector__XXX
 SG_ RRL_Obj04A_VyAxCoVnce : 336|12@1+ (0.01,0) [0|30] "m^2/s^3" Vector__XXX
 SG_ RRL_Obj04A_DxAyCoVnce : 348|12@1+ (0.01,0) [0|30] "m^2/s^2" Vector__XXX
 SG_ RRL_Obj04A_DyAyCoVnce : 360|12@1+ (0.01,0) [0|30] "m^2/s^2" Vector__XXX
 SG_ RRL_Obj04A_VxAyCoVnce : 372|12@1+ (0.01,0) [0|30] "m^2/s^3" Vector__XXX
 SG_ RRL_Obj04A_VyAyCoVnce : 384|12@1+ (0.01,0) [0|30] "m^2/s^3" Vector__XXX
 SG_ RRL_Obj04A_AxAyCoVnce : 396|12@1+ (0.01,0) [0|30] "m^2/s^4" Vector__XXX
 SG_ RRL_Obj04A_Measured : 39|1@1+ (1,0) [0|1] "" Vector__XXX
 SG_ RRL_Obj04A_HeadingYawVnce : 408|12@1+ (0.0003,0) [0|1] "rad^2" Vector__XXX
 SG_ RRL_Obj04A_Dx : 40|13@1+ (0.0625,-256) [-256|255.9375] "m" Vector__XXX
 SG_ RRL_Obj04A_LengthVnce : 420|12@1+ (0.01,0) [0|30] "m^2" Vector__XXX
 SG_ RRL_Obj04A_WidthVnce : 432|12@1+ (0.01,0) [0|30] "m^2" Vector__XXX
 SG_ RRL_Obj04A_HeightVnce : 444|12@1+ (0.01,0) [0|30] "m^2" Vector__XXX
 SG_ RRL_Obj04A_ExistProb : 456|6@1+ (2,0) [0|100] "%" Vector__XXX
 SG_ RRL_Obj04A_ProbObstacle : 462|6@1+ (2,0) [0|100] "%" Vector__XXX
 SG_ RRL_Obj04A_ProbNonObstacle : 468|6@1+ (2,0) [0|100] "%" Vector__XXX
 SG_ RRL_Obj04A_ProbMobileObst : 474|6@1+ (2,0) [0|100] "%" Vector__XXX
 SG_ RRL_Obj04A_FV : 487|8@0+ (1,0) [0|255] "" Vector__XXX
 SG_ RRL_Obj04A_MAC : 495|24@0+ (1,0) [0|16777215] "" Vector__XXX
 SG_ RRL_Obj04A_Dz : 53|6@1+ (0.25,-5) [-5|10.75] "m" Vector__XXX
 SG_ RRL_Obj04A_Dy : 59|11@1+ (0.125,-128) [-128|127.875] "m" Vector__XXX
 SG_ RRL_Obj04A_Valid : 70|1@1+ (1,0) [0|1] "" Vector__XXX
 SG_ RRL_Obj04A_Vx : 71|12@1+ (0.0625,-128) [-128|127.9375] "m/s" Vector__XXX
 SG_ RRL_Obj04A_Vy : 83|10@1+ (0.125,-64) [-64|63.875] "m/s" Vector__XXX
 SG_ RRL_Obj04A_Ax : 93|10@1+ (0.03125,-16) [-16|15.96875] "m/s^2" Vector__XXX

BO_ 793 RRL_Obj04B: 16 Vector__XXX
 SG_ RRL_Obj04B_CRC : 0|16@1+ (1,0) [0|65535] "" Vector__XXX
 SG_ RRL_Obj04B_MAC : 111|24@0+ (1,0) [0|16777215] "" Vector__XXX
 SG_ RRL_Obj04B_AliveCtr : 16|8@1+ (1,0) [0|254] "" Vector__XXX
 SG_ RRL_Obj04B_BlockCtr : 24|4@1+ (1,0) [0|15] "" Vector__XXX
 SG_ RRL_Obj04B_ProbMob4PlusWhl : 28|6@1+ (2,0) [0|100] "%" Vector__XXX
 SG_ RRL_Obj04B_ProbMob2Whl : 34|6@1+ (2,0) [0|100] "%" Vector__XXX
 SG_ RRL_Obj04B_ProbMobPed : 40|6@1+ (2,0) [0|100] "%" Vector__XXX
 SG_ RRL_Obj04B_Prob4PlusWhlCAR : 46|6@1+ (2,0) [0|100] "%" Vector__XXX
 SG_ RRL_Obj04B_Prob4PlusWhlbHGV : 52|6@1+ (2,0) [0|100] "%" Vector__XXX
 SG_ RRL_Obj04B_ProbGNDReflex : 58|6@1+ (2,0) [0|100] "%" Vector__XXX
 SG_ RRL_Obj04B_ProbStatBarrier : 64|6@1+ (2,0) [0|100] "%" Vector__XXX
 SG_ RRL_Obj04B_ProbStatObst : 70|6@1+ (2,0) [0|100] "%" Vector__XXX
 SG_ RRL_Obj04B_MovingProbability : 76|6@1+ (2,0) [0|100] "%" Vector__XXX
 SG_ RRL_Obj04B_MovingObserved : 82|6@1+ (2,0) [0|100] "%" Vector__XXX
 SG_ RRL_Obj04B_FV : 103|8@0+ (1,0) [0|255] "" Vector__XXX

BO_ 794 RRL_Obj05A: 64 Vector__XXX
 SG_ RRL_Obj05A_CRC : 0|16@1+ (1,0) [0|65535] "" Vector__XXX
 SG_ RRL_Obj05A_Ay : 103|9@1+ (0.0625,-16) [-16|15.9375] "m/s^2" Vector__XXX
 SG_ RRL_Obj05A_HeadingYawAngle : 112|9@1+ (0.0175,-4.48) [-3.15|3.15] "rad" Vector__XXX
 SG_ RRL_Obj05A_Length : 121|7@1+ (0.125,0) [0|15.875] "m" Vector__XXX
 SG_ RRL_Obj05A_Width : 128|7@1+ (0.125,0) [0|15.875] "m" Vector__XXX
 SG_ RRL_Obj05A_Height : 135|7@1+ (0.125,0) [0|15.875] "m" Vector__XXX
 SG_ RRL_Obj05A_DxVnce : 142|12@1+ (0.01,0) [0|30] "m^2" Vector__XXX
 SG_ RRL_Obj05A_DyVnce : 154|12@1+ (0.01,0) [0|30] "m^2" Vector__XXX
 SG_ RRL_Obj05A_DzVnce : 166|10@1+ (0.01,0) [0|10] "m^2" Vector__XXX
 SG_ RRL_Obj05A_AliveCtr : 16|8@1+ (1,0) [0|254] "" Vector__XXX
 SG_ RRL_Obj05A_VxVnce : 176|12@1+ (0.01,0) [0|30] "m^2/s^2" Vector__XXX
 SG_ RRL_Obj05A_VyVnce : 188|12@1+ (0.01,0) [0|30] "m^2/s^2" Vector__XXX
 SG_ RRL_Obj05A_AxVnce : 200|12@1+ (0.01,0) [0|30] "m^2/s^4" Vector__XXX
 SG_ RRL_Obj05A_AyVnce : 212|12@1+ (0.01,0) [0|30] "m^2/s^4" Vector__XXX
 SG_ RRL_Obj05A_RefPosIndex : 224|4@1+ (1,0) [0|15] "" Vector__XXX
 SG_ RRL_Obj05A_DxDyCoVnce : 228|12@1+ (0.01,0) [0|30] "m^2" Vector__XXX
 SG_ RRL_Obj05A_DxVxCoVnce : 240|12@1+ (0.01,0) [0|30] "m^2/s" Vector__XXX
 SG_ RRL_Obj05A_BlockCtr : 24|4@1+ (1,0) [0|15] "" Vector__XXX
 SG_ RRL_Obj05A_DyVxCoVnce : 252|12@1+ (0.01,0) [0|30] "m^2/s" Vector__XXX
 SG_ RRL_Obj05A_DxVyCoVnce : 264|12@1+ (0.01,0) [0|30] "m^2/s" Vector__XXX
 SG_ RRL_Obj05A_DyVyCoVnce : 276|12@1+ (0.01,0) [0|30] "m^2/s" Vector__XXX
 SG_ RRL_Obj05A_VxVyCoVnce : 288|12@1+ (0.01,0) [0|30] "m^2/s^2" Vector__XXX
 SG_ RRL_Obj05A_DxAxCoVnce : 300|12@1+ (0.01,0) [0|30] "m^2/s^2" Vector__XXX
 SG_ RRL_Obj05A_DyAxCoVnce : 312|12@1+ (0.01,0) [0|30] "m^2/s^2" Vector__XXX
 SG_ RRL_Obj05A_VxAxCoVnce : 324|12@1+ (0.01,0) [0|30] "m^2/s^3" Vector__XXX
 SG_ RRL_Obj05A_ObjectID : 32|7@1+ (1,0) [0|127] "" Vector__XXX
 SG_ RRL_Obj05A_VyAxCoVnce : 336|12@1+ (0.01,0) [0|30] "m^2/s^3" Vector__XXX
 SG_ RRL_Obj05A_DxAyCoVnce : 348|12@1+ (0.01,0) [0|30] "m^2/s^2" Vector__XXX
 SG_ RRL_Obj05A_DyAyCoVnce : 360|12@1+ (0.01,0) [0|30] "m^2/s^2" Vector__XXX
 SG_ RRL_Obj05A_VxAyCoVnce : 372|12@1+ (0.01,0) [0|30] "m^2/s^3" Vector__XXX
 SG_ RRL_Obj05A_VyAyCoVnce : 384|12@1+ (0.01,0) [0|30] "m^2/s^3" Vector__XXX
 SG_ RRL_Obj05A_AxAyCoVnce : 396|12@1+ (0.01,0) [0|30] "m^2/s^4" Vector__XXX
 SG_ RRL_Obj05A_Measured : 39|1@1+ (1,0) [0|1] "" Vector__XXX
 SG_ RRL_Obj05A_HeadingYawVnce : 408|12@1+ (0.0003,0) [0|1] "rad^2" Vector__XXX
 SG_ RRL_Obj05A_Dx : 40|13@1+ (0.0625,-256) [-256|255.9375] "m" Vector__XXX
 SG_ RRL_Obj05A_LengthVnce : 420|12@1+ (0.01,0) [0|30] "m^2" Vector__XXX
 SG_ RRL_Obj05A_WidthVnce : 432|12@1+ (0.01,0) [0|30] "m^2" Vector__XXX
 SG_ RRL_Obj05A_HeightVnce : 444|12@1+ (0.01,0) [0|30] "m^2" Vector__XXX
 SG_ RRL_Obj05A_ExistProb : 456|6@1+ (2,0) [0|100] "%" Vector__XXX
 SG_ RRL_Obj05A_ProbObstacle : 462|6@1+ (2,0) [0|100] "%" Vector__XXX
 SG_ RRL_Obj05A_ProbNonObstacle : 468|6@1+ (2,0) [0|100] "%" Vector__XXX
 SG_ RRL_Obj05A_ProbMobileObst : 474|6@1+ (2,0) [0|100] "%" Vector__XXX
 SG_ RRL_Obj05A_FV : 487|8@0+ (1,0) [0|255] "" Vector__XXX
 SG_ RRL_Obj05A_MAC : 495|24@0+ (1,0) [0|16777215] "" Vector__XXX
 SG_ RRL_Obj05A_Dz : 53|6@1+ (0.25,-5) [-5|10.75] "m" Vector__XXX
 SG_ RRL_Obj05A_Dy : 59|11@1+ (0.125,-128) [-128|127.875] "m" Vector__XXX
 SG_ RRL_Obj05A_Valid : 70|1@1+ (1,0) [0|1] "" Vector__XXX
 SG_ RRL_Obj05A_Vx : 71|12@1+ (0.0625,-128) [-128|127.9375] "m/s" Vector__XXX
 SG_ RRL_Obj05A_Vy : 83|10@1+ (0.125,-64) [-64|63.875] "m/s" Vector__XXX
 SG_ RRL_Obj05A_Ax : 93|10@1+ (0.03125,-16) [-16|15.96875] "m/s^2" Vector__XXX

BO_ 795 RRL_Obj05B: 16 Vector__XXX
 SG_ RRL_Obj05B_CRC : 0|16@1+ (1,0) [0|65535] "" Vector__XXX
 SG_ RRL_Obj05B_MAC : 111|24@0+ (1,0) [0|16777215] "" Vector__XXX
 SG_ RRL_Obj05B_AliveCtr : 16|8@1+ (1,0) [0|254] "" Vector__XXX
 SG_ RRL_Obj05B_BlockCtr : 24|4@1+ (1,0) [0|15] "" Vector__XXX
 SG_ RRL_Obj05B_ProbMob4PlusWhl : 28|6@1+ (2,0) [0|100] "%" Vector__XXX
 SG_ RRL_Obj05B_ProbMob2Whl : 34|6@1+ (2,0) [0|100] "%" Vector__XXX
 SG_ RRL_Obj05B_ProbMobPed : 40|6@1+ (2,0) [0|100] "%" Vector__XXX
 SG_ RRL_Obj05B_Prob4PlusWhlCAR : 46|6@1+ (2,0) [0|100] "%" Vector__XXX
 SG_ RRL_Obj05B_Prob4PlusWhlbHGV : 52|6@1+ (2,0) [0|100] "%" Vector__XXX
 SG_ RRL_Obj05B_ProbGNDReflex : 58|6@1+ (2,0) [0|100] "%" Vector__XXX
 SG_ RRL_Obj05B_ProbStatBarrier : 64|6@1+ (2,0) [0|100] "%" Vector__XXX
 SG_ RRL_Obj05B_ProbStatObst : 70|6@1+ (2,0) [0|100] "%" Vector__XXX
 SG_ RRL_Obj05B_MovingProbability : 76|6@1+ (2,0) [0|100] "%" Vector__XXX
 SG_ RRL_Obj05B_MovingObserved : 82|6@1+ (2,0) [0|100] "%" Vector__XXX
 SG_ RRL_Obj05B_FV : 103|8@0+ (1,0) [0|255] "" Vector__XXX

BO_ 796 RRL_Obj06A: 64 Vector__XXX
 SG_ RRL_Obj06A_CRC : 0|16@1+ (1,0) [0|65535] "" Vector__XXX
 SG_ RRL_Obj06A_Ay : 103|9@1+ (0.0625,-16) [-16|15.9375] "m/s^2" Vector__XXX
 SG_ RRL_Obj06A_HeadingYawAngle : 112|9@1+ (0.0175,-4.48) [-3.15|3.15] "rad" Vector__XXX
 SG_ RRL_Obj06A_Length : 121|7@1+ (0.125,0) [0|15.875] "m" Vector__XXX
 SG_ RRL_Obj06A_Width : 128|7@1+ (0.125,0) [0|15.875] "m" Vector__XXX
 SG_ RRL_Obj06A_Height : 135|7@1+ (0.125,0) [0|15.875] "m" Vector__XXX
 SG_ RRL_Obj06A_DxVnce : 142|12@1+ (0.01,0) [0|30] "m^2" Vector__XXX
 SG_ RRL_Obj06A_DyVnce : 154|12@1+ (0.01,0) [0|30] "m^2" Vector__XXX
 SG_ RRL_Obj06A_DzVnce : 166|10@1+ (0.01,0) [0|10] "m^2" Vector__XXX
 SG_ RRL_Obj06A_AliveCtr : 16|8@1+ (1,0) [0|254] "" Vector__XXX
 SG_ RRL_Obj06A_VxVnce : 176|12@1+ (0.01,0) [0|30] "m^2/s^2" Vector__XXX
 SG_ RRL_Obj06A_VyVnce : 188|12@1+ (0.01,0) [0|30] "m^2/s^2" Vector__XXX
 SG_ RRL_Obj06A_AxVnce : 200|12@1+ (0.01,0) [0|30] "m^2/s^4" Vector__XXX
 SG_ RRL_Obj06A_AyVnce : 212|12@1+ (0.01,0) [0|30] "m^2/s^4" Vector__XXX
 SG_ RRL_Obj06A_RefPosIndex : 224|4@1+ (1,0) [0|15] "" Vector__XXX
 SG_ RRL_Obj06A_DxDyCoVnce : 228|12@1+ (0.01,0) [0|30] "m^2" Vector__XXX
 SG_ RRL_Obj06A_DxVxCoVnce : 240|12@1+ (0.01,0) [0|30] "m^2/s" Vector__XXX
 SG_ RRL_Obj06A_BlockCtr : 24|4@1+ (1,0) [0|15] "" Vector__XXX
 SG_ RRL_Obj06A_DyVxCoVnce : 252|12@1+ (0.01,0) [0|30] "m^2/s" Vector__XXX
 SG_ RRL_Obj06A_DxVyCoVnce : 264|12@1+ (0.01,0) [0|30] "m^2/s" Vector__XXX
 SG_ RRL_Obj06A_DyVyCoVnce : 276|12@1+ (0.01,0) [0|30] "m^2/s" Vector__XXX
 SG_ RRL_Obj06A_VxVyCoVnce : 288|12@1+ (0.01,0) [0|30] "m^2/s^2" Vector__XXX
 SG_ RRL_Obj06A_DxAxCoVnce : 300|12@1+ (0.01,0) [0|30] "m^2/s^2" Vector__XXX
 SG_ RRL_Obj06A_DyAxCoVnce : 312|12@1+ (0.01,0) [0|30] "m^2/s^2" Vector__XXX
 SG_ RRL_Obj06A_VxAxCoVnce : 324|12@1+ (0.01,0) [0|30] "m^2/s^3" Vector__XXX
 SG_ RRL_Obj06A_ObjectID : 32|7@1+ (1,0) [0|127] "" Vector__XXX
 SG_ RRL_Obj06A_VyAxCoVnce : 336|12@1+ (0.01,0) [0|30] "m^2/s^3" Vector__XXX
 SG_ RRL_Obj06A_DxAyCoVnce : 348|12@1+ (0.01,0) [0|30] "m^2/s^2" Vector__XXX
 SG_ RRL_Obj06A_DyAyCoVnce : 360|12@1+ (0.01,0) [0|30] "m^2/s^2" Vector__XXX
 SG_ RRL_Obj06A_VxAyCoVnce : 372|12@1+ (0.01,0) [0|30] "m^2/s^3" Vector__XXX
 SG_ RRL_Obj06A_VyAyCoVnce : 384|12@1+ (0.01,0) [0|30] "m^2/s^3" Vector__XXX
 SG_ RRL_Obj06A_AxAyCoVnce : 396|12@1+ (0.01,0) [0|30] "m^2/s^4" Vector__XXX
 SG_ RRL_Obj06A_Measured : 39|1@1+ (1,0) [0|1] "" Vector__XXX
 SG_ RRL_Obj06A_HeadingYawVnce : 408|12@1+ (0.0003,0) [0|1] "rad^2" Vector__XXX
 SG_ RRL_Obj06A_Dx : 40|13@1+ (0.0625,-256) [-256|255.9375] "m" Vector__XXX
 SG_ RRL_Obj06A_LengthVnce : 420|12@1+ (0.01,0) [0|30] "m^2" Vector__XXX
 SG_ RRL_Obj06A_WidthVnce : 432|12@1+ (0.01,0) [0|30] "m^2" Vector__XXX
 SG_ RRL_Obj06A_HeightVnce : 444|12@1+ (0.01,0) [0|30] "m^2" Vector__XXX
 SG_ RRL_Obj06A_ExistProb : 456|6@1+ (2,0) [0|100] "%" Vector__XXX
 SG_ RRL_Obj06A_ProbObstacle : 462|6@1+ (2,0) [0|100] "%" Vector__XXX
 SG_ RRL_Obj06A_ProbNonObstacle : 468|6@1+ (2,0) [0|100] "%" Vector__XXX
 SG_ RRL_Obj06A_ProbMobileObst : 474|6@1+ (2,0) [0|100] "%" Vector__XXX
 SG_ RRL_Obj06A_FV : 487|8@0+ (1,0) [0|255] "" Vector__XXX
 SG_ RRL_Obj06A_MAC : 495|24@0+ (1,0) [0|16777215] "" Vector__XXX
 SG_ RRL_Obj06A_Dz : 53|6@1+ (0.25,-5) [-5|10.75] "m" Vector__XXX
 SG_ RRL_Obj06A_Dy : 59|11@1+ (0.125,-128) [-128|127.875] "m" Vector__XXX
 SG_ RRL_Obj06A_Valid : 70|1@1+ (1,0) [0|1] "" Vector__XXX
 SG_ RRL_Obj06A_Vx : 71|12@1+ (0.0625,-128) [-128|127.9375] "m/s" Vector__XXX
 SG_ RRL_Obj06A_Vy : 83|10@1+ (0.125,-64) [-64|63.875] "m/s" Vector__XXX
 SG_ RRL_Obj06A_Ax : 93|10@1+ (0.03125,-16) [-16|15.96875] "m/s^2" Vector__XXX

BO_ 797 RRL_Obj06B: 16 Vector__XXX
 SG_ RRL_Obj06B_CRC : 0|16@1+ (1,0) [0|65535] "" Vector__XXX
 SG_ RRL_Obj06B_MAC : 111|24@0+ (1,0) [0|16777215] "" Vector__XXX
 SG_ RRL_Obj06B_AliveCtr : 16|8@1+ (1,0) [0|254] "" Vector__XXX
 SG_ RRL_Obj06B_BlockCtr : 24|4@1+ (1,0) [0|15] "" Vector__XXX
 SG_ RRL_Obj06B_ProbMob4PlusWhl : 28|6@1+ (2,0) [0|100] "%" Vector__XXX
 SG_ RRL_Obj06B_ProbMob2Whl : 34|6@1+ (2,0) [0|100] "%" Vector__XXX
 SG_ RRL_Obj06B_ProbMobPed : 40|6@1+ (2,0) [0|100] "%" Vector__XXX
 SG_ RRL_Obj06B_Prob4PlusWhlCAR : 46|6@1+ (2,0) [0|100] "%" Vector__XXX
 SG_ RRL_Obj06B_Prob4PlusWhlbHGV : 52|6@1+ (2,0) [0|100] "%" Vector__XXX
 SG_ RRL_Obj06B_ProbGNDReflex : 58|6@1+ (2,0) [0|100] "%" Vector__XXX
 SG_ RRL_Obj06B_ProbStatBarrier : 64|6@1+ (2,0) [0|100] "%" Vector__XXX
 SG_ RRL_Obj06B_ProbStatObst : 70|6@1+ (2,0) [0|100] "%" Vector__XXX
 SG_ RRL_Obj06B_MovingProbability : 76|6@1+ (2,0) [0|100] "%" Vector__XXX
 SG_ RRL_Obj06B_MovingObserved : 82|6@1+ (2,0) [0|100] "%" Vector__XXX
 SG_ RRL_Obj06B_FV : 103|8@0+ (1,0) [0|255] "" Vector__XXX

BO_ 798 RRL_Obj07A: 64 Vector__XXX
 SG_ RRL_Obj07A_CRC : 0|16@1+ (1,0) [0|65535] "" Vector__XXX
 SG_ RRL_Obj07A_Ay : 103|9@1+ (0.0625,-16) [-16|15.9375] "m/s^2" Vector__XXX
 SG_ RRL_Obj07A_HeadingYawAngle : 112|9@1+ (0.0175,-4.48) [-3.15|3.15] "rad" Vector__XXX
 SG_ RRL_Obj07A_Length : 121|7@1+ (0.125,0) [0|15.875] "m" Vector__XXX
 SG_ RRL_Obj07A_Width : 128|7@1+ (0.125,0) [0|15.875] "m" Vector__XXX
 SG_ RRL_Obj07A_Height : 135|7@1+ (0.125,0) [0|15.875] "m" Vector__XXX
 SG_ RRL_Obj07A_DxVnce : 142|12@1+ (0.01,0) [0|30] "m^2" Vector__XXX
 SG_ RRL_Obj07A_DyVnce : 154|12@1+ (0.01,0) [0|30] "m^2" Vector__XXX
 SG_ RRL_Obj07A_DzVnce : 166|10@1+ (0.01,0) [0|10] "m^2" Vector__XXX
 SG_ RRL_Obj07A_AliveCtr : 16|8@1+ (1,0) [0|254] "" Vector__XXX
 SG_ RRL_Obj07A_VxVnce : 176|12@1+ (0.01,0) [0|30] "m^2/s^2" Vector__XXX
 SG_ RRL_Obj07A_VyVnce : 188|12@1+ (0.01,0) [0|30] "m^2/s^2" Vector__XXX
 SG_ RRL_Obj07A_AxVnce : 200|12@1+ (0.01,0) [0|30] "m^2/s^4" Vector__XXX
 SG_ RRL_Obj07A_AyVnce : 212|12@1+ (0.01,0) [0|30] "m^2/s^4" Vector__XXX
 SG_ RRL_Obj07A_RefPosIndex : 224|4@1+ (1,0) [0|15] "" Vector__XXX
 SG_ RRL_Obj07A_DxDyCoVnce : 228|12@1+ (0.01,0) [0|30] "m^2" Vector__XXX
 SG_ RRL_Obj07A_DxVxCoVnce : 240|12@1+ (0.01,0) [0|30] "m^2/s" Vector__XXX
 SG_ RRL_Obj07A_BlockCtr : 24|4@1+ (1,0) [0|15] "" Vector__XXX
 SG_ RRL_Obj07A_DyVxCoVnce : 252|12@1+ (0.01,0) [0|30] "m^2/s" Vector__XXX
 SG_ RRL_Obj07A_DxVyCoVnce : 264|12@1+ (0.01,0) [0|30] "m^2/s" Vector__XXX
 SG_ RRL_Obj07A_DyVyCoVnce : 276|12@1+ (0.01,0) [0|30] "m^2/s" Vector__XXX
 SG_ RRL_Obj07A_VxVyCoVnce : 288|12@1+ (0.01,0) [0|30] "m^2/s^2" Vector__XXX
 SG_ RRL_Obj07A_DxAxCoVnce : 300|12@1+ (0.01,0) [0|30] "m^2/s^2" Vector__XXX
 SG_ RRL_Obj07A_DyAxCoVnce : 312|12@1+ (0.01,0) [0|30] "m^2/s^2" Vector__XXX
 SG_ RRL_Obj07A_VxAxCoVnce : 324|12@1+ (0.01,0) [0|30] "m^2/s^3" Vector__XXX
 SG_ RRL_Obj07A_ObjectID : 32|7@1+ (1,0) [0|127] "" Vector__XXX
 SG_ RRL_Obj07A_VyAxCoVnce : 336|12@1+ (0.01,0) [0|30] "m^2/s^3" Vector__XXX
 SG_ RRL_Obj07A_DxAyCoVnce : 348|12@1+ (0.01,0) [0|30] "m^2/s^2" Vector__XXX
 SG_ RRL_Obj07A_DyAyCoVnce : 360|12@1+ (0.01,0) [0|30] "m^2/s^2" Vector__XXX
 SG_ RRL_Obj07A_VxAyCoVnce : 372|12@1+ (0.01,0) [0|30] "m^2/s^3" Vector__XXX
 SG_ RRL_Obj07A_VyAyCoVnce : 384|12@1+ (0.01,0) [0|30] "m^2/s^3" Vector__XXX
 SG_ RRL_Obj07A_AxAyCoVnce : 396|12@1+ (0.01,0) [0|30] "m^2/s^4" Vector__XXX
 SG_ RRL_Obj07A_Measured : 39|1@1+ (1,0) [0|1] "" Vector__XXX
 SG_ RRL_Obj07A_HeadingYawVnce : 408|12@1+ (0.0003,0) [0|1] "rad^2" Vector__XXX
 SG_ RRL_Obj07A_Dx : 40|13@1+ (0.0625,-256) [-256|255.9375] "m" Vector__XXX
 SG_ RRL_Obj07A_LengthVnce : 420|12@1+ (0.01,0) [0|30] "m^2" Vector__XXX
 SG_ RRL_Obj07A_WidthVnce : 432|12@1+ (0.01,0) [0|30] "m^2" Vector__XXX
 SG_ RRL_Obj07A_HeightVnce : 444|12@1+ (0.01,0) [0|30] "m^2" Vector__XXX
 SG_ RRL_Obj07A_ExistProb : 456|6@1+ (2,0) [0|100] "%" Vector__XXX
 SG_ RRL_Obj07A_ProbObstacle : 462|6@1+ (2,0) [0|100] "%" Vector__XXX
 SG_ RRL_Obj07A_ProbNonObstacle : 468|6@1+ (2,0) [0|100] "%" Vector__XXX
 SG_ RRL_Obj07A_ProbMobileObst : 474|6@1+ (2,0) [0|100] "%" Vector__XXX
 SG_ RRL_Obj07A_FV : 487|8@0+ (1,0) [0|255] "" Vector__XXX
 SG_ RRL_Obj07A_MAC : 495|24@0+ (1,0) [0|16777215] "" Vector__XXX
 SG_ RRL_Obj07A_Dz : 53|6@1+ (0.25,-5) [-5|10.75] "m" Vector__XXX
 SG_ RRL_Obj07A_Dy : 59|11@1+ (0.125,-128) [-128|127.875] "m" Vector__XXX
 SG_ RRL_Obj07A_Valid : 70|1@1+ (1,0) [0|1] "" Vector__XXX
 SG_ RRL_Obj07A_Vx : 71|12@1+ (0.0625,-128) [-128|127.9375] "m/s" Vector__XXX
 SG_ RRL_Obj07A_Vy : 83|10@1+ (0.125,-64) [-64|63.875] "m/s" Vector__XXX
 SG_ RRL_Obj07A_Ax : 93|10@1+ (0.03125,-16) [-16|15.96875] "m/s^2" Vector__XXX

BO_ 799 RRL_Obj07B: 16 Vector__XXX
 SG_ RRL_Obj07B_CRC : 0|16@1+ (1,0) [0|65535] "" Vector__XXX
 SG_ RRL_Obj07B_MAC : 111|24@0+ (1,0) [0|16777215] "" Vector__XXX
 SG_ RRL_Obj07B_AliveCtr : 16|8@1+ (1,0) [0|254] "" Vector__XXX
 SG_ RRL_Obj07B_BlockCtr : 24|4@1+ (1,0) [0|15] "" Vector__XXX
 SG_ RRL_Obj07B_ProbMob4PlusWhl : 28|6@1+ (2,0) [0|100] "%" Vector__XXX
 SG_ RRL_Obj07B_ProbMob2Whl : 34|6@1+ (2,0) [0|100] "%" Vector__XXX
 SG_ RRL_Obj07B_ProbMobPed : 40|6@1+ (2,0) [0|100] "%" Vector__XXX
 SG_ RRL_Obj07B_Prob4PlusWhlCAR : 46|6@1+ (2,0) [0|100] "%" Vector__XXX
 SG_ RRL_Obj07B_Prob4PlusWhlbHGV : 52|6@1+ (2,0) [0|100] "%" Vector__XXX
 SG_ RRL_Obj07B_ProbGNDReflex : 58|6@1+ (2,0) [0|100] "%" Vector__XXX
 SG_ RRL_Obj07B_ProbStatBarrier : 64|6@1+ (2,0) [0|100] "%" Vector__XXX
 SG_ RRL_Obj07B_ProbStatObst : 70|6@1+ (2,0) [0|100] "%" Vector__XXX
 SG_ RRL_Obj07B_MovingProbability : 76|6@1+ (2,0) [0|100] "%" Vector__XXX
 SG_ RRL_Obj07B_MovingObserved : 82|6@1+ (2,0) [0|100] "%" Vector__XXX
 SG_ RRL_Obj07B_FV : 103|8@0+ (1,0) [0|255] "" Vector__XXX

BO_ 800 RRL_Obj08A: 64 Vector__XXX
 SG_ RRL_Obj08A_CRC : 0|16@1+ (1,0) [0|65535] "" Vector__XXX
 SG_ RRL_Obj08A_Ay : 103|9@1+ (0.0625,-16) [-16|15.9375] "m/s^2" Vector__XXX
 SG_ RRL_Obj08A_HeadingYawAngle : 112|9@1+ (0.0175,-4.48) [-3.15|3.15] "rad" Vector__XXX
 SG_ RRL_Obj08A_Length : 121|7@1+ (0.125,0) [0|15.875] "m" Vector__XXX
 SG_ RRL_Obj08A_Width : 128|7@1+ (0.125,0) [0|15.875] "m" Vector__XXX
 SG_ RRL_Obj08A_Height : 135|7@1+ (0.125,0) [0|15.875] "m" Vector__XXX
 SG_ RRL_Obj08A_DxVnce : 142|12@1+ (0.01,0) [0|30] "m^2" Vector__XXX
 SG_ RRL_Obj08A_DyVnce : 154|12@1+ (0.01,0) [0|30] "m^2" Vector__XXX
 SG_ RRL_Obj08A_DzVnce : 166|10@1+ (0.01,0) [0|10] "m^2" Vector__XXX
 SG_ RRL_Obj08A_AliveCtr : 16|8@1+ (1,0) [0|254] "" Vector__XXX
 SG_ RRL_Obj08A_VxVnce : 176|12@1+ (0.01,0) [0|30] "m^2/s^2" Vector__XXX
 SG_ RRL_Obj08A_VyVnce : 188|12@1+ (0.01,0) [0|30] "m^2/s^2" Vector__XXX
 SG_ RRL_Obj08A_AxVnce : 200|12@1+ (0.01,0) [0|30] "m^2/s^4" Vector__XXX
 SG_ RRL_Obj08A_AyVnce : 212|12@1+ (0.01,0) [0|30] "m^2/s^4" Vector__XXX
 SG_ RRL_Obj08A_RefPosIndex : 224|4@1+ (1,0) [0|15] "" Vector__XXX
 SG_ RRL_Obj08A_DxDyCoVnce : 228|12@1+ (0.01,0) [0|30] "m^2" Vector__XXX
 SG_ RRL_Obj08A_DxVxCoVnce : 240|12@1+ (0.01,0) [0|30] "m^2/s" Vector__XXX
 SG_ RRL_Obj08A_BlockCtr : 24|4@1+ (1,0) [0|15] "" Vector__XXX
 SG_ RRL_Obj08A_DyVxCoVnce : 252|12@1+ (0.01,0) [0|30] "m^2/s" Vector__XXX
 SG_ RRL_Obj08A_DxVyCoVnce : 264|12@1+ (0.01,0) [0|30] "m^2/s" Vector__XXX
 SG_ RRL_Obj08A_DyVyCoVnce : 276|12@1+ (0.01,0) [0|30] "m^2/s" Vector__XXX
 SG_ RRL_Obj08A_VxVyCoVnce : 288|12@1+ (0.01,0) [0|30] "m^2/s^2" Vector__XXX
 SG_ RRL_Obj08A_DxAxCoVnce : 300|12@1+ (0.01,0) [0|30] "m^2/s^2" Vector__XXX
 SG_ RRL_Obj08A_DyAxCoVnce : 312|12@1+ (0.01,0) [0|30] "m^2/s^2" Vector__XXX
 SG_ RRL_Obj08A_VxAxCoVnce : 324|12@1+ (0.01,0) [0|30] "m^2/s^3" Vector__XXX
 SG_ RRL_Obj08A_ObjectID : 32|7@1+ (1,0) [0|127] "" Vector__XXX
 SG_ RRL_Obj08A_VyAxCoVnce : 336|12@1+ (0.01,0) [0|30] "m^2/s^3" Vector__XXX
 SG_ RRL_Obj08A_DxAyCoVnce : 348|12@1+ (0.01,0) [0|30] "m^2/s^2" Vector__XXX
 SG_ RRL_Obj08A_DyAyCoVnce : 360|12@1+ (0.01,0) [0|30] "m^2/s^2" Vector__XXX
 SG_ RRL_Obj08A_VxAyCoVnce : 372|12@1+ (0.01,0) [0|30] "m^2/s^3" Vector__XXX
 SG_ RRL_Obj08A_VyAyCoVnce : 384|12@1+ (0.01,0) [0|30] "m^2/s^3" Vector__XXX
 SG_ RRL_Obj08A_AxAyCoVnce : 396|12@1+ (0.01,0) [0|30] "m^2/s^4" Vector__XXX
 SG_ RRL_Obj08A_Measured : 39|1@1+ (1,0) [0|1] "" Vector__XXX
 SG_ RRL_Obj08A_HeadingYawVnce : 408|12@1+ (0.0003,0) [0|1] "rad^2" Vector__XXX
 SG_ RRL_Obj08A_Dx : 40|13@1+ (0.0625,-256) [-256|255.9375] "m" Vector__XXX
 SG_ RRL_Obj08A_LengthVnce : 420|12@1+ (0.01,0) [0|30] "m^2" Vector__XXX
 SG_ RRL_Obj08A_WidthVnce : 432|12@1+ (0.01,0) [0|30] "m^2" Vector__XXX
 SG_ RRL_Obj08A_HeightVnce : 444|12@1+ (0.01,0) [0|30] "m^2" Vector__XXX
 SG_ RRL_Obj08A_ExistProb : 456|6@1+ (2,0) [0|100] "%" Vector__XXX
 SG_ RRL_Obj08A_ProbObstacle : 462|6@1+ (2,0) [0|100] "%" Vector__XXX
 SG_ RRL_Obj08A_ProbNonObstacle : 468|6@1+ (2,0) [0|100] "%" Vector__XXX
 SG_ RRL_Obj08A_ProbMobileObst : 474|6@1+ (2,0) [0|100] "%" Vector__XXX
 SG_ RRL_Obj08A_FV : 487|8@0+ (1,0) [0|255] "" Vector__XXX
 SG_ RRL_Obj08A_MAC : 495|24@0+ (1,0) [0|16777215] "" Vector__XXX
 SG_ RRL_Obj08A_Dz : 53|6@1+ (0.25,-5) [-5|10.75] "m" Vector__XXX
 SG_ RRL_Obj08A_Dy : 59|11@1+ (0.125,-128) [-128|127.875] "m" Vector__XXX
 SG_ RRL_Obj08A_Valid : 70|1@1+ (1,0) [0|1] "" Vector__XXX
 SG_ RRL_Obj08A_Vx : 71|12@1+ (0.0625,-128) [-128|127.9375] "m/s" Vector__XXX
 SG_ RRL_Obj08A_Vy : 83|10@1+ (0.125,-64) [-64|63.875] "m/s" Vector__XXX
 SG_ RRL_Obj08A_Ax : 93|10@1+ (0.03125,-16) [-16|15.96875] "m/s^2" Vector__XXX

BO_ 801 RRL_Obj08B: 16 Vector__XXX
 SG_ RRL_Obj08B_CRC : 0|16@1+ (1,0) [0|65535] "" Vector__XXX
 SG_ RRL_Obj08B_MAC : 111|24@0+ (1,0) [0|16777215] "" Vector__XXX
 SG_ RRL_Obj08B_AliveCtr : 16|8@1+ (1,0) [0|254] "" Vector__XXX
 SG_ RRL_Obj08B_BlockCtr : 24|4@1+ (1,0) [0|15] "" Vector__XXX
 SG_ RRL_Obj08B_ProbMob4PlusWhl : 28|6@1+ (2,0) [0|100] "%" Vector__XXX
 SG_ RRL_Obj08B_ProbMob2Whl : 34|6@1+ (2,0) [0|100] "%" Vector__XXX
 SG_ RRL_Obj08B_ProbMobPed : 40|6@1+ (2,0) [0|100] "%" Vector__XXX
 SG_ RRL_Obj08B_Prob4PlusWhlCAR : 46|6@1+ (2,0) [0|100] "%" Vector__XXX
 SG_ RRL_Obj08B_Prob4PlusWhlbHGV : 52|6@1+ (2,0) [0|100] "%" Vector__XXX
 SG_ RRL_Obj08B_ProbGNDReflex : 58|6@1+ (2,0) [0|100] "%" Vector__XXX
 SG_ RRL_Obj08B_ProbStatBarrier : 64|6@1+ (2,0) [0|100] "%" Vector__XXX
 SG_ RRL_Obj08B_ProbStatObst : 70|6@1+ (2,0) [0|100] "%" Vector__XXX
 SG_ RRL_Obj08B_MovingProbability : 76|6@1+ (2,0) [0|100] "%" Vector__XXX
 SG_ RRL_Obj08B_MovingObserved : 82|6@1+ (2,0) [0|100] "%" Vector__XXX
 SG_ RRL_Obj08B_FV : 103|8@0+ (1,0) [0|255] "" Vector__XXX

BO_ 802 RRL_Obj09A: 64 Vector__XXX
 SG_ RRL_Obj09A_CRC : 0|16@1+ (1,0) [0|65535] "" Vector__XXX
 SG_ RRL_Obj09A_Ay : 103|9@1+ (0.0625,-16) [-16|15.9375] "m/s^2" Vector__XXX
 SG_ RRL_Obj09A_HeadingYawAngle : 112|9@1+ (0.0175,-4.48) [-3.15|3.15] "rad" Vector__XXX
 SG_ RRL_Obj09A_Length : 121|7@1+ (0.125,0) [0|15.875] "m" Vector__XXX
 SG_ RRL_Obj09A_Width : 128|7@1+ (0.125,0) [0|15.875] "m" Vector__XXX
 SG_ RRL_Obj09A_Height : 135|7@1+ (0.125,0) [0|15.875] "m" Vector__XXX
 SG_ RRL_Obj09A_DxVnce : 142|12@1+ (0.01,0) [0|30] "m^2" Vector__XXX
 SG_ RRL_Obj09A_DyVnce : 154|12@1+ (0.01,0) [0|30] "m^2" Vector__XXX
 SG_ RRL_Obj09A_DzVnce : 166|10@1+ (0.01,0) [0|10] "m^2" Vector__XXX
 SG_ RRL_Obj09A_AliveCtr : 16|8@1+ (1,0) [0|254] "" Vector__XXX
 SG_ RRL_Obj09A_VxVnce : 176|12@1+ (0.01,0) [0|30] "m^2/s^2" Vector__XXX
 SG_ RRL_Obj09A_VyVnce : 188|12@1+ (0.01,0) [0|30] "m^2/s^2" Vector__XXX
 SG_ RRL_Obj09A_AxVnce : 200|12@1+ (0.01,0) [0|30] "m^2/s^4" Vector__XXX
 SG_ RRL_Obj09A_AyVnce : 212|12@1+ (0.01,0) [0|30] "m^2/s^4" Vector__XXX
 SG_ RRL_Obj09A_RefPosIndex : 224|4@1+ (1,0) [0|15] "" Vector__XXX
 SG_ RRL_Obj09A_DxDyCoVnce : 228|12@1+ (0.01,0) [0|30] "m^2" Vector__XXX
 SG_ RRL_Obj09A_DxVxCoVnce : 240|12@1+ (0.01,0) [0|30] "m^2/s" Vector__XXX
 SG_ RRL_Obj09A_BlockCtr : 24|4@1+ (1,0) [0|15] "" Vector__XXX
 SG_ RRL_Obj09A_DyVxCoVnce : 252|12@1+ (0.01,0) [0|30] "m^2/s" Vector__XXX
 SG_ RRL_Obj09A_DxVyCoVnce : 264|12@1+ (0.01,0) [0|30] "m^2/s" Vector__XXX
 SG_ RRL_Obj09A_DyVyCoVnce : 276|12@1+ (0.01,0) [0|30] "m^2/s" Vector__XXX
 SG_ RRL_Obj09A_VxVyCoVnce : 288|12@1+ (0.01,0) [0|30] "m^2/s^2" Vector__XXX
 SG_ RRL_Obj09A_DxAxCoVnce : 300|12@1+ (0.01,0) [0|30] "m^2/s^2" Vector__XXX
 SG_ RRL_Obj09A_DyAxCoVnce : 312|12@1+ (0.01,0) [0|30] "m^2/s^2" Vector__XXX
 SG_ RRL_Obj09A_VxAxCoVnce : 324|12@1+ (0.01,0) [0|30] "m^2/s^3" Vector__XXX
 SG_ RRL_Obj09A_ObjectID : 32|7@1+ (1,0) [0|127] "" Vector__XXX
 SG_ RRL_Obj09A_VyAxCoVnce : 336|12@1+ (0.01,0) [0|30] "m^2/s^3" Vector__XXX
 SG_ RRL_Obj09A_DxAyCoVnce : 348|12@1+ (0.01,0) [0|30] "m^2/s^2" Vector__XXX
 SG_ RRL_Obj09A_DyAyCoVnce : 360|12@1+ (0.01,0) [0|30] "m^2/s^2" Vector__XXX
 SG_ RRL_Obj09A_VxAyCoVnce : 372|12@1+ (0.01,0) [0|30] "m^2/s^3" Vector__XXX
 SG_ RRL_Obj09A_VyAyCoVnce : 384|12@1+ (0.01,0) [0|30] "m^2/s^3" Vector__XXX
 SG_ RRL_Obj09A_AxAyCoVnce : 396|12@1+ (0.01,0) [0|30] "m^2/s^4" Vector__XXX
 SG_ RRL_Obj09A_Measured : 39|1@1+ (1,0) [0|1] "" Vector__XXX
 SG_ RRL_Obj09A_HeadingYawVnce : 408|12@1+ (0.0003,0) [0|1] "rad^2" Vector__XXX
 SG_ RRL_Obj09A_Dx : 40|13@1+ (0.0625,-256) [-256|255.9375] "m" Vector__XXX
 SG_ RRL_Obj09A_LengthVnce : 420|12@1+ (0.01,0) [0|30] "m^2" Vector__XXX
 SG_ RRL_Obj09A_WidthVnce : 432|12@1+ (0.01,0) [0|30] "m^2" Vector__XXX
 SG_ RRL_Obj09A_HeightVnce : 444|12@1+ (0.01,0) [0|30] "m^2" Vector__XXX
 SG_ RRL_Obj09A_ExistProb : 456|6@1+ (2,0) [0|100] "%" Vector__XXX
 SG_ RRL_Obj09A_ProbObstacle : 462|6@1+ (2,0) [0|100] "%" Vector__XXX
 SG_ RRL_Obj09A_ProbNonObstacle : 468|6@1+ (2,0) [0|100] "%" Vector__XXX
 SG_ RRL_Obj09A_ProbMobileObst : 474|6@1+ (2,0) [0|100] "%" Vector__XXX
 SG_ RRL_Obj09A_FV : 487|8@0+ (1,0) [0|255] "" Vector__XXX
 SG_ RRL_Obj09A_MAC : 495|24@0+ (1,0) [0|16777215] "" Vector__XXX
 SG_ RRL_Obj09A_Dz : 53|6@1+ (0.25,-5) [-5|10.75] "m" Vector__XXX
 SG_ RRL_Obj09A_Dy : 59|11@1+ (0.125,-128) [-128|127.875] "m" Vector__XXX
 SG_ RRL_Obj09A_Valid : 70|1@1+ (1,0) [0|1] "" Vector__XXX
 SG_ RRL_Obj09A_Vx : 71|12@1+ (0.0625,-128) [-128|127.9375] "m/s" Vector__XXX
 SG_ RRL_Obj09A_Vy : 83|10@1+ (0.125,-64) [-64|63.875] "m/s" Vector__XXX
 SG_ RRL_Obj09A_Ax : 93|10@1+ (0.03125,-16) [-16|15.96875] "m/s^2" Vector__XXX

BO_ 803 RRL_Obj09B: 16 Vector__XXX
 SG_ RRL_Obj09B_CRC : 0|16@1+ (1,0) [0|65535] "" Vector__XXX
 SG_ RRL_Obj09B_MAC : 111|24@0+ (1,0) [0|16777215] "" Vector__XXX
 SG_ RRL_Obj09B_AliveCtr : 16|8@1+ (1,0) [0|254] "" Vector__XXX
 SG_ RRL_Obj09B_BlockCtr : 24|4@1+ (1,0) [0|15] "" Vector__XXX
 SG_ RRL_Obj09B_ProbMob4PlusWhl : 28|6@1+ (2,0) [0|100] "%" Vector__XXX
 SG_ RRL_Obj09B_ProbMob2Whl : 34|6@1+ (2,0) [0|100] "%" Vector__XXX
 SG_ RRL_Obj09B_ProbMobPed : 40|6@1+ (2,0) [0|100] "%" Vector__XXX
 SG_ RRL_Obj09B_Prob4PlusWhlCAR : 46|6@1+ (2,0) [0|100] "%" Vector__XXX
 SG_ RRL_Obj09B_Prob4PlusWhlbHGV : 52|6@1+ (2,0) [0|100] "%" Vector__XXX
 SG_ RRL_Obj09B_ProbGNDReflex : 58|6@1+ (2,0) [0|100] "%" Vector__XXX
 SG_ RRL_Obj09B_ProbStatBarrier : 64|6@1+ (2,0) [0|100] "%" Vector__XXX
 SG_ RRL_Obj09B_ProbStatObst : 70|6@1+ (2,0) [0|100] "%" Vector__XXX
 SG_ RRL_Obj09B_MovingProbability : 76|6@1+ (2,0) [0|100] "%" Vector__XXX
 SG_ RRL_Obj09B_MovingObserved : 82|6@1+ (2,0) [0|100] "%" Vector__XXX
 SG_ RRL_Obj09B_FV : 103|8@0+ (1,0) [0|255] "" Vector__XXX

BO_ 804 RRL_Obj10A: 64 Vector__XXX
 SG_ RRL_Obj10A_CRC : 0|16@1+ (1,0) [0|65535] "" Vector__XXX
 SG_ RRL_Obj10A_Ay : 103|9@1+ (0.0625,-16) [-16|15.9375] "m/s^2" Vector__XXX
 SG_ RRL_Obj10A_HeadingYawAngle : 112|9@1+ (0.0175,-4.48) [-3.15|3.15] "rad" Vector__XXX
 SG_ RRL_Obj10A_Length : 121|7@1+ (0.125,0) [0|15.875] "m" Vector__XXX
 SG_ RRL_Obj10A_Width : 128|7@1+ (0.125,0) [0|15.875] "m" Vector__XXX
 SG_ RRL_Obj10A_Height : 135|7@1+ (0.125,0) [0|15.875] "m" Vector__XXX
 SG_ RRL_Obj10A_DxVnce : 142|12@1+ (0.01,0) [0|30] "m^2" Vector__XXX
 SG_ RRL_Obj10A_DyVnce : 154|12@1+ (0.01,0) [0|30] "m^2" Vector__XXX
 SG_ RRL_Obj10A_DzVnce : 166|10@1+ (0.01,0) [0|10] "m^2" Vector__XXX
 SG_ RRL_Obj10A_AliveCtr : 16|8@1+ (1,0) [0|254] "" Vector__XXX
 SG_ RRL_Obj10A_VxVnce : 176|12@1+ (0.01,0) [0|30] "m^2/s^2" Vector__XXX
 SG_ RRL_Obj10A_VyVnce : 188|12@1+ (0.01,0) [0|30] "m^2/s^2" Vector__XXX
 SG_ RRL_Obj10A_AxVnce : 200|12@1+ (0.01,0) [0|30] "m^2/s^4" Vector__XXX
 SG_ RRL_Obj10A_AyVnce : 212|12@1+ (0.01,0) [0|30] "m^2/s^4" Vector__XXX
 SG_ RRL_Obj10A_RefPosIndex : 224|4@1+ (1,0) [0|15] "" Vector__XXX
 SG_ RRL_Obj10A_DxDyCoVnce : 228|12@1+ (0.01,0) [0|30] "m^2" Vector__XXX
 SG_ RRL_Obj10A_DxVxCoVnce : 240|12@1+ (0.01,0) [0|30] "m^2/s" Vector__XXX
 SG_ RRL_Obj10A_BlockCtr : 24|4@1+ (1,0) [0|15] "" Vector__XXX
 SG_ RRL_Obj10A_DyVxCoVnce : 252|12@1+ (0.01,0) [0|30] "m^2/s" Vector__XXX
 SG_ RRL_Obj10A_DxVyCoVnce : 264|12@1+ (0.01,0) [0|30] "m^2/s" Vector__XXX
 SG_ RRL_Obj10A_DyVyCoVnce : 276|12@1+ (0.01,0) [0|30] "m^2/s" Vector__XXX
 SG_ RRL_Obj10A_VxVyCoVnce : 288|12@1+ (0.01,0) [0|30] "m^2/s^2" Vector__XXX
 SG_ RRL_Obj10A_DxAxCoVnce : 300|12@1+ (0.01,0) [0|30] "m^2/s^2" Vector__XXX
 SG_ RRL_Obj10A_DyAxCoVnce : 312|12@1+ (0.01,0) [0|30] "m^2/s^2" Vector__XXX
 SG_ RRL_Obj10A_VxAxCoVnce : 324|12@1+ (0.01,0) [0|30] "m^2/s^3" Vector__XXX
 SG_ RRL_Obj10A_ObjectID : 32|7@1+ (1,0) [0|127] "" Vector__XXX
 SG_ RRL_Obj10A_VyAxCoVnce : 336|12@1+ (0.01,0) [0|30] "m^2/s^3" Vector__XXX
 SG_ RRL_Obj10A_DxAyCoVnce : 348|12@1+ (0.01,0) [0|30] "m^2/s^2" Vector__XXX
 SG_ RRL_Obj10A_DyAyCoVnce : 360|12@1+ (0.01,0) [0|30] "m^2/s^2" Vector__XXX
 SG_ RRL_Obj10A_VxAyCoVnce : 372|12@1+ (0.01,0) [0|30] "m^2/s^3" Vector__XXX
 SG_ RRL_Obj10A_VyAyCoVnce : 384|12@1+ (0.01,0) [0|30] "m^2/s^3" Vector__XXX
 SG_ RRL_Obj10A_AxAyCoVnce : 396|12@1+ (0.01,0) [0|30] "m^2/s^4" Vector__XXX
 SG_ RRL_Obj10A_Measured : 39|1@1+ (1,0) [0|1] "" Vector__XXX
 SG_ RRL_Obj10A_HeadingYawVnce : 408|12@1+ (0.0003,0) [0|1] "rad^2" Vector__XXX
 SG_ RRL_Obj10A_Dx : 40|13@1+ (0.0625,-256) [-256|255.9375] "m" Vector__XXX
 SG_ RRL_Obj10A_LengthVnce : 420|12@1+ (0.01,0) [0|30] "m^2" Vector__XXX
 SG_ RRL_Obj10A_WidthVnce : 432|12@1+ (0.01,0) [0|30] "m^2" Vector__XXX
 SG_ RRL_Obj10A_HeightVnce : 444|12@1+ (0.01,0) [0|30] "m^2" Vector__XXX
 SG_ RRL_Obj10A_ExistProb : 456|6@1+ (2,0) [0|100] "%" Vector__XXX
 SG_ RRL_Obj10A_ProbObstacle : 462|6@1+ (2,0) [0|100] "%" Vector__XXX
 SG_ RRL_Obj10A_ProbNonObstacle : 468|6@1+ (2,0) [0|100] "%" Vector__XXX
 SG_ RRL_Obj10A_ProbMobileObst : 474|6@1+ (2,0) [0|100] "%" Vector__XXX
 SG_ RRL_Obj10A_FV : 487|8@0+ (1,0) [0|255] "" Vector__XXX
 SG_ RRL_Obj10A_MAC : 495|24@0+ (1,0) [0|16777215] "" Vector__XXX
 SG_ RRL_Obj10A_Dz : 53|6@1+ (0.25,-5) [-5|10.75] "m" Vector__XXX
 SG_ RRL_Obj10A_Dy : 59|11@1+ (0.125,-128) [-128|127.875] "m" Vector__XXX
 SG_ RRL_Obj10A_Valid : 70|1@1+ (1,0) [0|1] "" Vector__XXX
 SG_ RRL_Obj10A_Vx : 71|12@1+ (0.0625,-128) [-128|127.9375] "m/s" Vector__XXX
 SG_ RRL_Obj10A_Vy : 83|10@1+ (0.125,-64) [-64|63.875] "m/s" Vector__XXX
 SG_ RRL_Obj10A_Ax : 93|10@1+ (0.03125,-16) [-16|15.96875] "m/s^2" Vector__XXX

BO_ 805 RRL_Obj10B: 16 Vector__XXX
 SG_ RRL_Obj10B_CRC : 0|16@1+ (1,0) [0|65535] "" Vector__XXX
 SG_ RRL_Obj10B_MAC : 111|24@0+ (1,0) [0|16777215] "" Vector__XXX
 SG_ RRL_Obj10B_AliveCtr : 16|8@1+ (1,0) [0|254] "" Vector__XXX
 SG_ RRL_Obj10B_BlockCtr : 24|4@1+ (1,0) [0|15] "" Vector__XXX
 SG_ RRL_Obj10B_ProbMob4PlusWhl : 28|6@1+ (2,0) [0|100] "%" Vector__XXX
 SG_ RRL_Obj10B_ProbMob2Whl : 34|6@1+ (2,0) [0|100] "%" Vector__XXX
 SG_ RRL_Obj10B_ProbMobPed : 40|6@1+ (2,0) [0|100] "%" Vector__XXX
 SG_ RRL_Obj10B_Prob4PlusWhlCAR : 46|6@1+ (2,0) [0|100] "%" Vector__XXX
 SG_ RRL_Obj10B_Prob4PlusWhlbHGV : 52|6@1+ (2,0) [0|100] "%" Vector__XXX
 SG_ RRL_Obj10B_ProbGNDReflex : 58|6@1+ (2,0) [0|100] "%" Vector__XXX
 SG_ RRL_Obj10B_ProbStatBarrier : 64|6@1+ (2,0) [0|100] "%" Vector__XXX
 SG_ RRL_Obj10B_ProbStatObst : 70|6@1+ (2,0) [0|100] "%" Vector__XXX
 SG_ RRL_Obj10B_MovingProbability : 76|6@1+ (2,0) [0|100] "%" Vector__XXX
 SG_ RRL_Obj10B_MovingObserved : 82|6@1+ (2,0) [0|100] "%" Vector__XXX
 SG_ RRL_Obj10B_FV : 103|8@0+ (1,0) [0|255] "" Vector__XXX

BO_ 806 RRL_Obj11A: 64 Vector__XXX
 SG_ RRL_Obj11A_CRC : 0|16@1+ (1,0) [0|65535] "" Vector__XXX
 SG_ RRL_Obj11A_Ay : 103|9@1+ (0.0625,-16) [-16|15.9375] "m/s^2" Vector__XXX
 SG_ RRL_Obj11A_HeadingYawAngle : 112|9@1+ (0.0175,-4.48) [-3.15|3.15] "rad" Vector__XXX
 SG_ RRL_Obj11A_Length : 121|7@1+ (0.125,0) [0|15.875] "m" Vector__XXX
 SG_ RRL_Obj11A_Width : 128|7@1+ (0.125,0) [0|15.875] "m" Vector__XXX
 SG_ RRL_Obj11A_Height : 135|7@1+ (0.125,0) [0|15.875] "m" Vector__XXX
 SG_ RRL_Obj11A_DxVnce : 142|12@1+ (0.01,0) [0|30] "m^2" Vector__XXX
 SG_ RRL_Obj11A_DyVnce : 154|12@1+ (0.01,0) [0|30] "m^2" Vector__XXX
 SG_ RRL_Obj11A_DzVnce : 166|10@1+ (0.01,0) [0|10] "m^2" Vector__XXX
 SG_ RRL_Obj11A_AliveCtr : 16|8@1+ (1,0) [0|254] "" Vector__XXX
 SG_ RRL_Obj11A_VxVnce : 176|12@1+ (0.01,0) [0|30] "m^2/s^2" Vector__XXX
 SG_ RRL_Obj11A_VyVnce : 188|12@1+ (0.01,0) [0|30] "m^2/s^2" Vector__XXX
 SG_ RRL_Obj11A_AxVnce : 200|12@1+ (0.01,0) [0|30] "m^2/s^4" Vector__XXX
 SG_ RRL_Obj11A_AyVnce : 212|12@1+ (0.01,0) [0|30] "m^2/s^4" Vector__XXX
 SG_ RRL_Obj11A_RefPosIndex : 224|4@1+ (1,0) [0|15] "" Vector__XXX
 SG_ RRL_Obj11A_DxDyCoVnce : 228|12@1+ (0.01,0) [0|30] "m^2" Vector__XXX
 SG_ RRL_Obj11A_DxVxCoVnce : 240|12@1+ (0.01,0) [0|30] "m^2/s" Vector__XXX
 SG_ RRL_Obj11A_BlockCtr : 24|4@1+ (1,0) [0|15] "" Vector__XXX
 SG_ RRL_Obj11A_DyVxCoVnce : 252|12@1+ (0.01,0) [0|30] "m^2/s" Vector__XXX
 SG_ RRL_Obj11A_DxVyCoVnce : 264|12@1+ (0.01,0) [0|30] "m^2/s" Vector__XXX
 SG_ RRL_Obj11A_DyVyCoVnce : 276|12@1+ (0.01,0) [0|30] "m^2/s" Vector__XXX
 SG_ RRL_Obj11A_VxVyCoVnce : 288|12@1+ (0.01,0) [0|30] "m^2/s^2" Vector__XXX
 SG_ RRL_Obj11A_DxAxCoVnce : 300|12@1+ (0.01,0) [0|30] "m^2/s^2" Vector__XXX
 SG_ RRL_Obj11A_DyAxCoVnce : 312|12@1+ (0.01,0) [0|30] "m^2/s^2" Vector__XXX
 SG_ RRL_Obj11A_VxAxCoVnce : 324|12@1+ (0.01,0) [0|30] "m^2/s^3" Vector__XXX
 SG_ RRL_Obj11A_ObjectID : 32|7@1+ (1,0) [0|127] "" Vector__XXX
 SG_ RRL_Obj11A_VyAxCoVnce : 336|12@1+ (0.01,0) [0|30] "m^2/s^3" Vector__XXX
 SG_ RRL_Obj11A_DxAyCoVnce : 348|12@1+ (0.01,0) [0|30] "m^2/s^2" Vector__XXX
 SG_ RRL_Obj11A_DyAyCoVnce : 360|12@1+ (0.01,0) [0|30] "m^2/s^2" Vector__XXX
 SG_ RRL_Obj11A_VxAyCoVnce : 372|12@1+ (0.01,0) [0|30] "m^2/s^3" Vector__XXX
 SG_ RRL_Obj11A_VyAyCoVnce : 384|12@1+ (0.01,0) [0|30] "m^2/s^3" Vector__XXX
 SG_ RRL_Obj11A_AxAyCoVnce : 396|12@1+ (0.01,0) [0|30] "m^2/s^4" Vector__XXX
 SG_ RRL_Obj11A_Measured : 39|1@1+ (1,0) [0|1] "" Vector__XXX
 SG_ RRL_Obj11A_HeadingYawVnce : 408|12@1+ (0.0003,0) [0|1] "rad^2" Vector__XXX
 SG_ RRL_Obj11A_Dx : 40|13@1+ (0.0625,-256) [-256|255.9375] "m" Vector__XXX
 SG_ RRL_Obj11A_LengthVnce : 420|12@1+ (0.01,0) [0|30] "m^2" Vector__XXX
 SG_ RRL_Obj11A_WidthVnce : 432|12@1+ (0.01,0) [0|30] "m^2" Vector__XXX
 SG_ RRL_Obj11A_HeightVnce : 444|12@1+ (0.01,0) [0|30] "m^2" Vector__XXX
 SG_ RRL_Obj11A_ExistProb : 456|6@1+ (2,0) [0|100] "%" Vector__XXX
 SG_ RRL_Obj11A_ProbObstacle : 462|6@1+ (2,0) [0|100] "%" Vector__XXX
 SG_ RRL_Obj11A_ProbNonObstacle : 468|6@1+ (2,0) [0|100] "%" Vector__XXX
 SG_ RRL_Obj11A_ProbMobileObst : 474|6@1+ (2,0) [0|100] "%" Vector__XXX
 SG_ RRL_Obj11A_FV : 487|8@0+ (1,0) [0|255] "" Vector__XXX
 SG_ RRL_Obj11A_MAC : 495|24@0+ (1,0) [0|16777215] "" Vector__XXX
 SG_ RRL_Obj11A_Dz : 53|6@1+ (0.25,-5) [-5|10.75] "m" Vector__XXX
 SG_ RRL_Obj11A_Dy : 59|11@1+ (0.125,-128) [-128|127.875] "m" Vector__XXX
 SG_ RRL_Obj11A_Valid : 70|1@1+ (1,0) [0|1] "" Vector__XXX
 SG_ RRL_Obj11A_Vx : 71|12@1+ (0.0625,-128) [-128|127.9375] "m/s" Vector__XXX
 SG_ RRL_Obj11A_Vy : 83|10@1+ (0.125,-64) [-64|63.875] "m/s" Vector__XXX
 SG_ RRL_Obj11A_Ax : 93|10@1+ (0.03125,-16) [-16|15.96875] "m/s^2" Vector__XXX

BO_ 807 RRL_Obj11B: 16 Vector__XXX
 SG_ RRL_Obj11B_CRC : 0|16@1+ (1,0) [0|65535] "" Vector__XXX
 SG_ RRL_Obj11B_MAC : 111|24@0+ (1,0) [0|16777215] "" Vector__XXX
 SG_ RRL_Obj11B_AliveCtr : 16|8@1+ (1,0) [0|254] "" Vector__XXX
 SG_ RRL_Obj11B_BlockCtr : 24|4@1+ (1,0) [0|15] "" Vector__XXX
 SG_ RRL_Obj11B_ProbMob4PlusWhl : 28|6@1+ (2,0) [0|100] "%" Vector__XXX
 SG_ RRL_Obj11B_ProbMob2Whl : 34|6@1+ (2,0) [0|100] "%" Vector__XXX
 SG_ RRL_Obj11B_ProbMobPed : 40|6@1+ (2,0) [0|100] "%" Vector__XXX
 SG_ RRL_Obj11B_Prob4PlusWhlCAR : 46|6@1+ (2,0) [0|100] "%" Vector__XXX
 SG_ RRL_Obj11B_Prob4PlusWhlbHGV : 52|6@1+ (2,0) [0|100] "%" Vector__XXX
 SG_ RRL_Obj11B_ProbGNDReflex : 58|6@1+ (2,0) [0|100] "%" Vector__XXX
 SG_ RRL_Obj11B_ProbStatBarrier : 64|6@1+ (2,0) [0|100] "%" Vector__XXX
 SG_ RRL_Obj11B_ProbStatObst : 70|6@1+ (2,0) [0|100] "%" Vector__XXX
 SG_ RRL_Obj11B_MovingProbability : 76|6@1+ (2,0) [0|100] "%" Vector__XXX
 SG_ RRL_Obj11B_MovingObserved : 82|6@1+ (2,0) [0|100] "%" Vector__XXX
 SG_ RRL_Obj11B_FV : 103|8@0+ (1,0) [0|255] "" Vector__XXX

BO_ 808 RRL_Obj12A: 64 Vector__XXX
 SG_ RRL_Obj12A_CRC : 0|16@1+ (1,0) [0|65535] "" Vector__XXX
 SG_ RRL_Obj12A_Ay : 103|9@1+ (0.0625,-16) [-16|15.9375] "m/s^2" Vector__XXX
 SG_ RRL_Obj12A_HeadingYawAngle : 112|9@1+ (0.0175,-4.48) [-3.15|3.15] "rad" Vector__XXX
 SG_ RRL_Obj12A_Length : 121|7@1+ (0.125,0) [0|15.875] "m" Vector__XXX
 SG_ RRL_Obj12A_Width : 128|7@1+ (0.125,0) [0|15.875] "m" Vector__XXX
 SG_ RRL_Obj12A_Height : 135|7@1+ (0.125,0) [0|15.875] "m" Vector__XXX
 SG_ RRL_Obj12A_DxVnce : 142|12@1+ (0.01,0) [0|30] "m^2" Vector__XXX
 SG_ RRL_Obj12A_DyVnce : 154|12@1+ (0.01,0) [0|30] "m^2" Vector__XXX
 SG_ RRL_Obj12A_DzVnce : 166|10@1+ (0.01,0) [0|10] "m^2" Vector__XXX
 SG_ RRL_Obj12A_AliveCtr : 16|8@1+ (1,0) [0|254] "" Vector__XXX
 SG_ RRL_Obj12A_VxVnce : 176|12@1+ (0.01,0) [0|30] "m^2/s^2" Vector__XXX
 SG_ RRL_Obj12A_VyVnce : 188|12@1+ (0.01,0) [0|30] "m^2/s^2" Vector__XXX
 SG_ RRL_Obj12A_AxVnce : 200|12@1+ (0.01,0) [0|30] "m^2/s^4" Vector__XXX
 SG_ RRL_Obj12A_AyVnce : 212|12@1+ (0.01,0) [0|30] "m^2/s^4" Vector__XXX
 SG_ RRL_Obj12A_RefPosIndex : 224|4@1+ (1,0) [0|15] "" Vector__XXX
 SG_ RRL_Obj12A_DxDyCoVnce : 228|12@1+ (0.01,0) [0|30] "m^2" Vector__XXX
 SG_ RRL_Obj12A_DxVxCoVnce : 240|12@1+ (0.01,0) [0|30] "m^2/s" Vector__XXX
 SG_ RRL_Obj12A_BlockCtr : 24|4@1+ (1,0) [0|15] "" Vector__XXX
 SG_ RRL_Obj12A_DyVxCoVnce : 252|12@1+ (0.01,0) [0|30] "m^2/s" Vector__XXX
 SG_ RRL_Obj12A_DxVyCoVnce : 264|12@1+ (0.01,0) [0|30] "m^2/s" Vector__XXX
 SG_ RRL_Obj12A_DyVyCoVnce : 276|12@1+ (0.01,0) [0|30] "m^2/s" Vector__XXX
 SG_ RRL_Obj12A_VxVyCoVnce : 288|12@1+ (0.01,0) [0|30] "m^2/s^2" Vector__XXX
 SG_ RRL_Obj12A_DxAxCoVnce : 300|12@1+ (0.01,0) [0|30] "m^2/s^2" Vector__XXX
 SG_ RRL_Obj12A_DyAxCoVnce : 312|12@1+ (0.01,0) [0|30] "m^2/s^2" Vector__XXX
 SG_ RRL_Obj12A_VxAxCoVnce : 324|12@1+ (0.01,0) [0|30] "m^2/s^3" Vector__XXX
 SG_ RRL_Obj12A_ObjectID : 32|7@1+ (1,0) [0|127] "" Vector__XXX
 SG_ RRL_Obj12A_VyAxCoVnce : 336|12@1+ (0.01,0) [0|30] "m^2/s^3" Vector__XXX
 SG_ RRL_Obj12A_DxAyCoVnce : 348|12@1+ (0.01,0) [0|30] "m^2/s^2" Vector__XXX
 SG_ RRL_Obj12A_DyAyCoVnce : 360|12@1+ (0.01,0) [0|30] "m^2/s^2" Vector__XXX
 SG_ RRL_Obj12A_VxAyCoVnce : 372|12@1+ (0.01,0) [0|30] "m^2/s^3" Vector__XXX
 SG_ RRL_Obj12A_VyAyCoVnce : 384|12@1+ (0.01,0) [0|30] "m^2/s^3" Vector__XXX
 SG_ RRL_Obj12A_AxAyCoVnce : 396|12@1+ (0.01,0) [0|30] "m^2/s^4" Vector__XXX
 SG_ RRL_Obj12A_Measured : 39|1@1+ (1,0) [0|1] "" Vector__XXX
 SG_ RRL_Obj12A_HeadingYawVnce : 408|12@1+ (0.0003,0) [0|1] "rad^2" Vector__XXX
 SG_ RRL_Obj12A_Dx : 40|13@1+ (0.0625,-256) [-256|255.9375] "m" Vector__XXX
 SG_ RRL_Obj12A_LengthVnce : 420|12@1+ (0.01,0) [0|30] "m^2" Vector__XXX
 SG_ RRL_Obj12A_WidthVnce : 432|12@1+ (0.01,0) [0|30] "m^2" Vector__XXX
 SG_ RRL_Obj12A_HeightVnce : 444|12@1+ (0.01,0) [0|30] "m^2" Vector__XXX
 SG_ RRL_Obj12A_ExistProb : 456|6@1+ (2,0) [0|100] "%" Vector__XXX
 SG_ RRL_Obj12A_ProbObstacle : 462|6@1+ (2,0) [0|100] "%" Vector__XXX
 SG_ RRL_Obj12A_ProbNonObstacle : 468|6@1+ (2,0) [0|100] "%" Vector__XXX
 SG_ RRL_Obj12A_ProbMobileObst : 474|6@1+ (2,0) [0|100] "%" Vector__XXX
 SG_ RRL_Obj12A_FV : 487|8@0+ (1,0) [0|255] "" Vector__XXX
 SG_ RRL_Obj12A_MAC : 495|24@0+ (1,0) [0|16777215] "" Vector__XXX
 SG_ RRL_Obj12A_Dz : 53|6@1+ (0.25,-5) [-5|10.75] "m" Vector__XXX
 SG_ RRL_Obj12A_Dy : 59|11@1+ (0.125,-128) [-128|127.875] "m" Vector__XXX
 SG_ RRL_Obj12A_Valid : 70|1@1+ (1,0) [0|1] "" Vector__XXX
 SG_ RRL_Obj12A_Vx : 71|12@1+ (0.0625,-128) [-128|127.9375] "m/s" Vector__XXX
 SG_ RRL_Obj12A_Vy : 83|10@1+ (0.125,-64) [-64|63.875] "m/s" Vector__XXX
 SG_ RRL_Obj12A_Ax : 93|10@1+ (0.03125,-16) [-16|15.96875] "m/s^2" Vector__XXX

BO_ 809 RRL_Obj12B: 16 Vector__XXX
 SG_ RRL_Obj12B_CRC : 0|16@1+ (1,0) [0|65535] "" Vector__XXX
 SG_ RRL_Obj12B_MAC : 111|24@0+ (1,0) [0|16777215] "" Vector__XXX
 SG_ RRL_Obj12B_AliveCtr : 16|8@1+ (1,0) [0|254] "" Vector__XXX
 SG_ RRL_Obj12B_BlockCtr : 24|4@1+ (1,0) [0|15] "" Vector__XXX
 SG_ RRL_Obj12B_ProbMob4PlusWhl : 28|6@1+ (2,0) [0|100] "%" Vector__XXX
 SG_ RRL_Obj12B_ProbMob2Whl : 34|6@1+ (2,0) [0|100] "%" Vector__XXX
 SG_ RRL_Obj12B_ProbMobPed : 40|6@1+ (2,0) [0|100] "%" Vector__XXX
 SG_ RRL_Obj12B_Prob4PlusWhlCAR : 46|6@1+ (2,0) [0|100] "%" Vector__XXX
 SG_ RRL_Obj12B_Prob4PlusWhlbHGV : 52|6@1+ (2,0) [0|100] "%" Vector__XXX
 SG_ RRL_Obj12B_ProbGNDReflex : 58|6@1+ (2,0) [0|100] "%" Vector__XXX
 SG_ RRL_Obj12B_ProbStatBarrier : 64|6@1+ (2,0) [0|100] "%" Vector__XXX
 SG_ RRL_Obj12B_ProbStatObst : 70|6@1+ (2,0) [0|100] "%" Vector__XXX
 SG_ RRL_Obj12B_MovingProbability : 76|6@1+ (2,0) [0|100] "%" Vector__XXX
 SG_ RRL_Obj12B_MovingObserved : 82|6@1+ (2,0) [0|100] "%" Vector__XXX
 SG_ RRL_Obj12B_FV : 103|8@0+ (1,0) [0|255] "" Vector__XXX

CM_ BO_ 3221225472 "This is a message for not used signals, created by Vector CANdb++ DBC OLE DB Provider.";
CM_ SG_ 3221225472 RSDS_RiTgt_02_dy "0x00-0x50:Valid Value
0x51-0x7F:Reserved";
CM_ SG_ 3221225472 RSDS_RiTgt_02_dx "0x00-0x3B6:Valid Value
0x3B7-0x3FF:Reserved";
CM_ SG_ 3221225472 RSDS_RiTgt_01_dy "0x00-0x50:Valid Value
0x51-0x7F:Reserved";
CM_ SG_ 3221225472 RSDS_RiTgt_01_dx "0x00-0x3B6:Valid Value
0x3B7-0x3FF:Reserved";
CM_ SG_ 3221225472 RSDS_MidTgt_02_dy "0x00-0x50:Valid Value
0x51-0x7F:Reserved";
CM_ SG_ 3221225472 RSDS_MidTgt_02_dx "0x00-0x3B6:Valid Value
0x3B7-0x3FF:Reserved";
CM_ SG_ 3221225472 RSDS_MidTgt_01_dy "0x00-0x50:Valid Value
0x51-0x7F:Reserved";
CM_ SG_ 3221225472 RSDS_MidTgt_01_dx "0x00-0x3B6:Valid Value
0x3B7-0x3FF:Reserved";
CM_ SG_ 1791 ADAS_SYNC_RR_Type "Type=0x20 : TSync    Type=0x28 : TSync FUP";
CM_ SG_ 769 RCTA_B__L__TTC "TTC of RCTB_RCTA function in left corner radar";
CM_ SG_ 769 RSDS_LeTgt_02_dy "0x00-0x50:Valid Value
0x51-0x7F:Reserved";
CM_ SG_ 769 RSDS_LeTgt_02_dx "0x00-0x3B6:Valid Value
0x3B7-0x3FF:Reserved";
CM_ SG_ 769 RSDS_LeTgt_01_dy "0x00-0x50:Valid Value
0x51-0x7F:Reserved";
CM_ SG_ 769 RSDS_LeTgt_01_dx "0x00-0x3B6:Valid Value
0x3B7-0x3FF:Reserved";
CM_ SG_ 769 ObjLgtSpdCurvLe "Left Objection Longitude Speed";
CM_ SG_ 769 ObjLgtPosnCurvLe "Left Objection Longitude Position";
CM_ SG_ 769 ObjIDLe "Left Objection ID";
CM_ SG_ 769 LeTarSts "Indicate left target valid of not";
CM_ SG_ 768 RRL_Hdr_CRC "CRC - Autosar E2E Profile 5";
CM_ SG_ 768 RRL_Hdr_YawAngleUpper "Upper angle of the field of view Alimuth";
CM_ SG_ 768 RRL_Hdr_YawMountAngle "angle between sensor mounting direction and vehicle longitudinal axis, Azimuth";
CM_ SG_ 768 RRL_Hdr_YawAngleLower "Lower angle of the fied of view Azimuth";
CM_ SG_ 768 RRL_Hdr_ElevOutOfSpec "The sensor was detected to be out-of-spec due to misalignment in elevation";
CM_ SG_ 768 RRL_Hdr_PitchMountAngle "angle between sensor mounting direction and vehicle longitudinal axis, Elevation";
CM_ SG_ 768 RRL_Hdr_PitchAngleLower "Lower angle of the fied of view Elevation";
CM_ SG_ 768 RRL_Hdr_AliveCtr "Alive counter - Autosar E2E Profile 5";
CM_ SG_ 768 RRL_Hdr_PitchAngleUpper "Upper angle of the field of view Elevation";
CM_ SG_ 768 RRL_Hdr_RollMountAngle "Tilt of the mounting sensor";
CM_ SG_ 768 RRL_Hdr_DetectionRange "Estimated detection range of the sensor";
CM_ SG_ 768 RRL_Hdr_SensorState "The sensor shall provide its operation state.
In case of multiple errors the most severe state shall be sent.";
CM_ SG_ 768 RRL_Hdr_FV "SecOC Freshness Value (Profile 1)";
CM_ SG_ 768 RRL_Hdr_MAC "SecOC MAC (Profile 1)";
CM_ SG_ 768 RRL_Hdr_BlockCtr "Block-Counter";
CM_ SG_ 768 RRL_Hdr_ProtocolVersion "Protocol version to be send: 0x0102 = V1.2 (Checked-In Version)";
CM_ SG_ 768 RRL_Hdr_ObjectCount "number of detected VALID Objects that have been sent to the bus";
CM_ SG_ 768 RRL_Hdr_TimeSyncFailure "In case of time sync mechanism failure, the Front Radar Ecu time stamp shall be send and the time sync fail flag shall be set to 1.";
CM_ SG_ 768 RRL_Hdr_ObjectDownSel "the detected number of objects exceeded the number of max. objects that can be transmitted";
CM_ SG_ 768 RRL_Hdr_MountingPosY "mount offset of sensor in lateral direction relative to mid axis of vehicle";
CM_ SG_ 768 RRL_Hdr_AbsRefTime "time stamp";
CM_ SG_ 768 RRL_Hdr_MountingPosZ "mount offset of sensor in elevation direction relative to GROUND";
CM_ SG_ 768 RRL_Hdr_AziOutOfSpec "The sensor was detected to be out-of-spec due to misalignment in azimuth";
CM_ SG_ 768 RRL_Hdr_MountingPosX "mount offset of sensor in longitudinal direction relative to rear axis of vehicle";
CM_ SG_ 784 RRL_Obj00A_CRC "CRC - Autosar E2E Profile 5";
CM_ SG_ 784 RRL_Obj00A_Ay "Object acceleration in Y direction";
CM_ SG_ 784 RRL_Obj00A_HeadingYawAngle "Object heading yaw angle";
CM_ SG_ 784 RRL_Obj00A_Length "Object Length";
CM_ SG_ 784 RRL_Obj00A_Width "Object Width";
CM_ SG_ 784 RRL_Obj00A_Height "Object Height";
CM_ SG_ 784 RRL_Obj00A_DxVnce "Variance of object position in X direction";
CM_ SG_ 784 RRL_Obj00A_DyVnce "Variance of object position in Y direction";
CM_ SG_ 784 RRL_Obj00A_DzVnce "Variance of object position in Z direction";
CM_ SG_ 784 RRL_Obj00A_AliveCtr "Alive counter - Autosar E2E Profile 5";
CM_ SG_ 784 RRL_Obj00A_VxVnce "Variance of object velocity in X direction";
CM_ SG_ 784 RRL_Obj00A_VyVnce "Variance of object velocity in Y direction";
CM_ SG_ 784 RRL_Obj00A_AxVnce "Variance of object acceleration in X direction";
CM_ SG_ 784 RRL_Obj00A_AyVnce "Variance of object acceleration in Y direction";
CM_ SG_ 784 RRL_Obj00A_RefPosIndex "Reference Position of the detected objects";
CM_ SG_ 784 RRL_Obj00A_DxDyCoVnce "Correlation coefficient of Dx and Dy";
CM_ SG_ 784 RRL_Obj00A_DxVxCoVnce "Correlation coefficient of Dx and Vx";
CM_ SG_ 784 RRL_Obj00A_BlockCtr "Block-Counter";
CM_ SG_ 784 RRL_Obj00A_DyVxCoVnce "Correlation coefficient of Dy and Ax";
CM_ SG_ 784 RRL_Obj00A_DxVyCoVnce "Correlation coefficient of Dx and Vy";
CM_ SG_ 784 RRL_Obj00A_DyVyCoVnce "Correlation coefficient of Dy and Vy";
CM_ SG_ 784 RRL_Obj00A_VxVyCoVnce "Correlation coefficient of Vx and Vy";
CM_ SG_ 784 RRL_Obj00A_DxAxCoVnce "Correlation coefficient of Dx and Ax";
CM_ SG_ 784 RRL_Obj00A_DyAxCoVnce "Correlation coefficient of Dy and Ax";
CM_ SG_ 784 RRL_Obj00A_VxAxCoVnce "Correlation coefficient of Vx and Ax";
CM_ SG_ 784 RRL_Obj00A_ObjectID "Unique Object ID";
CM_ SG_ 784 RRL_Obj00A_VyAxCoVnce "Correlation coefficient of Vy and Ax";
CM_ SG_ 784 RRL_Obj00A_DxAyCoVnce "Correlation coefficient of Dx and Ay";
CM_ SG_ 784 RRL_Obj00A_DyAyCoVnce "Correlation coefficient of Dy and Ay";
CM_ SG_ 784 RRL_Obj00A_VxAyCoVnce "Correlation coefficient of Vx and Ay";
CM_ SG_ 784 RRL_Obj00A_VyAyCoVnce "Correlation coefficient of Vy and Ay";
CM_ SG_ 784 RRL_Obj00A_AxAyCoVnce "Correlation coefficient of Ax and Ay";
CM_ SG_ 784 RRL_Obj00A_Measured "Object is measured or not";
CM_ SG_ 784 RRL_Obj00A_HeadingYawVnce "Variance of Object heading yaw angle";
CM_ SG_ 784 RRL_Obj00A_Dx "Object position in X direction";
CM_ SG_ 784 RRL_Obj00A_LengthVnce "Variance of Object Length";
CM_ SG_ 784 RRL_Obj00A_WidthVnce "Variance of Object Width";
CM_ SG_ 784 RRL_Obj00A_HeightVnce "Variance of Object Height";
CM_ SG_ 784 RRL_Obj00A_ExistProb "Existence probability of object";
CM_ SG_ 784 RRL_Obj00A_ProbObstacle "Probability of the object being an Obstacle";
CM_ SG_ 784 RRL_Obj00A_ProbNonObstacle "Probability of the object being a Non-Obstacle";
CM_ SG_ 784 RRL_Obj00A_ProbMobileObst "Probability of the object being a mobile obstacle";
CM_ SG_ 784 RRL_Obj00A_FV "SecOC Freshness Value (Profile 1)";
CM_ SG_ 784 RRL_Obj00A_MAC "SecOC MAC (Profile 1)";
CM_ SG_ 784 RRL_Obj00A_Dz "Object position in Z direction";
CM_ SG_ 784 RRL_Obj00A_Dy "Object position in Y direction";
CM_ SG_ 784 RRL_Obj00A_Valid "Object is valid or not";
CM_ SG_ 784 RRL_Obj00A_Vx "Object velocity in X direction";
CM_ SG_ 784 RRL_Obj00A_Vy "Object velocity in Y direction";
CM_ SG_ 784 RRL_Obj00A_Ax "Object acceleration in X direction";
CM_ SG_ 785 RRL_Obj00B_CRC "CRC - Autosar E2E Profile 5";
CM_ SG_ 785 RRL_Obj00B_MAC "SecOC MAC (Profile 1)";
CM_ SG_ 785 RRL_Obj00B_AliveCtr "Alive counter - Autosar E2E Profile 5";
CM_ SG_ 785 RRL_Obj00B_BlockCtr "Block-Counter";
CM_ SG_ 785 RRL_Obj00B_ProbMob4PlusWhl "Probability of a mobile object which has 4 or more wheels";
CM_ SG_ 785 RRL_Obj00B_ProbMob2Whl "Probability of a mobile object being 2-wheels vehicle";
CM_ SG_ 785 RRL_Obj00B_ProbMobPed "Probability of a mobile object being a pedestrian";
CM_ SG_ 785 RRL_Obj00B_Prob4PlusWhlCAR "Probability of a mobile object which has 4 or more wheels--passenger car";
CM_ SG_ 785 RRL_Obj00B_Prob4PlusWhlbHGV "Probability of a mobile object which has 4 or more wheels--commercial vehicle(Turck)";
CM_ SG_ 785 RRL_Obj00B_ProbGNDReflex "Probability of the object being a ground reflex";
CM_ SG_ 785 RRL_Obj00B_ProbStatBarrier "Probability of the object being a stationary road barrier";
CM_ SG_ 785 RRL_Obj00B_ProbStatObst "Probability of the object being a stationary obstacle";
CM_ SG_ 785 RRL_Obj00B_MovingProbability "Object has been observed moving over the ground";
CM_ SG_ 785 RRL_Obj00B_MovingObserved "Object has been observed moving over the ground since it was first detected";
CM_ SG_ 785 RRL_Obj00B_FV "SecOC Freshness Value (Profile 1)";
CM_ SG_ 786 RRL_Obj01A_CRC "CRC - Autosar E2E Profile 5";
CM_ SG_ 786 RRL_Obj01A_Ay "Object acceleration in Y direction";
CM_ SG_ 786 RRL_Obj01A_HeadingYawAngle "Object heading yaw angle";
CM_ SG_ 786 RRL_Obj01A_Length "Object Length";
CM_ SG_ 786 RRL_Obj01A_Width "Object Width";
CM_ SG_ 786 RRL_Obj01A_Height "Object Height";
CM_ SG_ 786 RRL_Obj01A_DxVnce "Variance of object position in X direction";
CM_ SG_ 786 RRL_Obj01A_DyVnce "Variance of object position in Y direction";
CM_ SG_ 786 RRL_Obj01A_DzVnce "Variance of object position in Z direction";
CM_ SG_ 786 RRL_Obj01A_AliveCtr "Alive counter - Autosar E2E Profile 5";
CM_ SG_ 786 RRL_Obj01A_VxVnce "Variance of object velocity in X direction";
CM_ SG_ 786 RRL_Obj01A_VyVnce "Variance of object velocity in Y direction";
CM_ SG_ 786 RRL_Obj01A_AxVnce "Variance of object acceleration in X direction";
CM_ SG_ 786 RRL_Obj01A_AyVnce "Variance of object acceleration in Y direction";
CM_ SG_ 786 RRL_Obj01A_RefPosIndex "Reference Position of the detected objects";
CM_ SG_ 786 RRL_Obj01A_DxDyCoVnce "Correlation coefficient of Dx and Dy";
CM_ SG_ 786 RRL_Obj01A_DxVxCoVnce "Correlation coefficient of Dx and Vx";
CM_ SG_ 786 RRL_Obj01A_BlockCtr "Block-Counter";
CM_ SG_ 786 RRL_Obj01A_DyVxCoVnce "Correlation coefficient of Dy and Ax";
CM_ SG_ 786 RRL_Obj01A_DxVyCoVnce "Correlation coefficient of Dx and Vy";
CM_ SG_ 786 RRL_Obj01A_DyVyCoVnce "Correlation coefficient of Dy and Vy";
CM_ SG_ 786 RRL_Obj01A_VxVyCoVnce "Correlation coefficient of Vx and Vy";
CM_ SG_ 786 RRL_Obj01A_DxAxCoVnce "Correlation coefficient of Dx and Ax";
CM_ SG_ 786 RRL_Obj01A_DyAxCoVnce "Correlation coefficient of Dy and Ax";
CM_ SG_ 786 RRL_Obj01A_VxAxCoVnce "Correlation coefficient of Vx and Ax";
CM_ SG_ 786 RRL_Obj01A_ObjectID "Unique Object ID";
CM_ SG_ 786 RRL_Obj01A_VyAxCoVnce "Correlation coefficient of Vy and Ax";
CM_ SG_ 786 RRL_Obj01A_DxAyCoVnce "Correlation coefficient of Dx and Ay";
CM_ SG_ 786 RRL_Obj01A_DyAyCoVnce "Correlation coefficient of Dy and Ay";
CM_ SG_ 786 RRL_Obj01A_VxAyCoVnce "Correlation coefficient of Vx and Ay";
CM_ SG_ 786 RRL_Obj01A_VyAyCoVnce "Correlation coefficient of Vy and Ay";
CM_ SG_ 786 RRL_Obj01A_AxAyCoVnce "Correlation coefficient of Ax and Ay";
CM_ SG_ 786 RRL_Obj01A_Measured "Object is measured or not";
CM_ SG_ 786 RRL_Obj01A_HeadingYawVnce "Variance of Object heading yaw angle";
CM_ SG_ 786 RRL_Obj01A_Dx "Object position in X direction";
CM_ SG_ 786 RRL_Obj01A_LengthVnce "Variance of Object Length";
CM_ SG_ 786 RRL_Obj01A_WidthVnce "Variance of Object Width";
CM_ SG_ 786 RRL_Obj01A_HeightVnce "Variance of Object Height";
CM_ SG_ 786 RRL_Obj01A_ExistProb "Existence probability of object";
CM_ SG_ 786 RRL_Obj01A_ProbObstacle "Probability of the object being an Obstacle";
CM_ SG_ 786 RRL_Obj01A_ProbNonObstacle "Probability of the object being a Non-Obstacle";
CM_ SG_ 786 RRL_Obj01A_ProbMobileObst "Probability of the object being a mobile obstacle";
CM_ SG_ 786 RRL_Obj01A_FV "SecOC Freshness Value (Profile 1)";
CM_ SG_ 786 RRL_Obj01A_MAC "SecOC MAC (Profile 1)";
CM_ SG_ 786 RRL_Obj01A_Dz "Object position in Z direction";
CM_ SG_ 786 RRL_Obj01A_Dy "Object position in Y direction";
CM_ SG_ 786 RRL_Obj01A_Valid "Object is valid or not";
CM_ SG_ 786 RRL_Obj01A_Vx "Object velocity in X direction";
CM_ SG_ 786 RRL_Obj01A_Vy "Object velocity in Y direction";
CM_ SG_ 786 RRL_Obj01A_Ax "Object acceleration in X direction";
CM_ SG_ 787 RRL_Obj01B_CRC "CRC - Autosar E2E Profile 5";
CM_ SG_ 787 RRL_Obj01B_MAC "SecOC MAC (Profile 1)";
CM_ SG_ 787 RRL_Obj01B_AliveCtr "Alive counter - Autosar E2E Profile 5";
CM_ SG_ 787 RRL_Obj01B_BlockCtr "Block-Counter";
CM_ SG_ 787 RRL_Obj01B_ProbMob4PlusWhl "Probability of a mobile object which has 4 or more wheels";
CM_ SG_ 787 RRL_Obj01B_ProbMob2Whl "Probability of a mobile object being 2-wheels vehicle";
CM_ SG_ 787 RRL_Obj01B_ProbMobPed "Probability of a mobile object being a pedestrian";
CM_ SG_ 787 RRL_Obj01B_Prob4PlusWhlCAR "Probability of a mobile object which has 4 or more wheels--passenger car";
CM_ SG_ 787 RRL_Obj01B_Prob4PlusWhlbHGV "Probability of a mobile object which has 4 or more wheels--commercial vehicle(Turck)";
CM_ SG_ 787 RRL_Obj01B_ProbGNDReflex "Probability of the object being a ground reflex";
CM_ SG_ 787 RRL_Obj01B_ProbStatBarrier "Probability of the object being a stationary road barrier";
CM_ SG_ 787 RRL_Obj01B_ProbStatObst "Probability of the object being a stationary obstacle";
CM_ SG_ 787 RRL_Obj01B_MovingProbability "Object has been observed moving over the ground";
CM_ SG_ 787 RRL_Obj01B_MovingObserved "Object has been observed moving over the ground since it was first detected";
CM_ SG_ 787 RRL_Obj01B_FV "SecOC Freshness Value (Profile 1)";
CM_ SG_ 788 RRL_Obj02A_CRC "CRC - Autosar E2E Profile 5";
CM_ SG_ 788 RRL_Obj02A_Ay "Object acceleration in Y direction";
CM_ SG_ 788 RRL_Obj02A_HeadingYawAngle "Object heading yaw angle";
CM_ SG_ 788 RRL_Obj02A_Length "Object Length";
CM_ SG_ 788 RRL_Obj02A_Width "Object Width";
CM_ SG_ 788 RRL_Obj02A_Height "Object Height";
CM_ SG_ 788 RRL_Obj02A_DxVnce "Variance of object position in X direction";
CM_ SG_ 788 RRL_Obj02A_DyVnce "Variance of object position in Y direction";
CM_ SG_ 788 RRL_Obj02A_DzVnce "Variance of object position in Z direction";
CM_ SG_ 788 RRL_Obj02A_AliveCtr "Alive counter - Autosar E2E Profile 5";
CM_ SG_ 788 RRL_Obj02A_VxVnce "Variance of object velocity in X direction";
CM_ SG_ 788 RRL_Obj02A_VyVnce "Variance of object velocity in Y direction";
CM_ SG_ 788 RRL_Obj02A_AxVnce "Variance of object acceleration in X direction";
CM_ SG_ 788 RRL_Obj02A_AyVnce "Variance of object acceleration in Y direction";
CM_ SG_ 788 RRL_Obj02A_RefPosIndex "Reference Position of the detected objects";
CM_ SG_ 788 RRL_Obj02A_DxDyCoVnce "Correlation coefficient of Dx and Dy";
CM_ SG_ 788 RRL_Obj02A_DxVxCoVnce "Correlation coefficient of Dx and Vx";
CM_ SG_ 788 RRL_Obj02A_BlockCtr "Block-Counter";
CM_ SG_ 788 RRL_Obj02A_DyVxCoVnce "Correlation coefficient of Dy and Ax";
CM_ SG_ 788 RRL_Obj02A_DxVyCoVnce "Correlation coefficient of Dx and Vy";
CM_ SG_ 788 RRL_Obj02A_DyVyCoVnce "Correlation coefficient of Dy and Vy";
CM_ SG_ 788 RRL_Obj02A_VxVyCoVnce "Correlation coefficient of Vx and Vy";
CM_ SG_ 788 RRL_Obj02A_DxAxCoVnce "Correlation coefficient of Dx and Ax";
CM_ SG_ 788 RRL_Obj02A_DyAxCoVnce "Correlation coefficient of Dy and Ax";
CM_ SG_ 788 RRL_Obj02A_VxAxCoVnce "Correlation coefficient of Vx and Ax";
CM_ SG_ 788 RRL_Obj02A_ObjectID "Unique Object ID";
CM_ SG_ 788 RRL_Obj02A_VyAxCoVnce "Correlation coefficient of Vy and Ax";
CM_ SG_ 788 RRL_Obj02A_DxAyCoVnce "Correlation coefficient of Dx and Ay";
CM_ SG_ 788 RRL_Obj02A_DyAyCoVnce "Correlation coefficient of Dy and Ay";
CM_ SG_ 788 RRL_Obj02A_VxAyCoVnce "Correlation coefficient of Vx and Ay";
CM_ SG_ 788 RRL_Obj02A_VyAyCoVnce "Correlation coefficient of Vy and Ay";
CM_ SG_ 788 RRL_Obj02A_AxAyCoVnce "Correlation coefficient of Ax and Ay";
CM_ SG_ 788 RRL_Obj02A_Measured "Object is measured or not";
CM_ SG_ 788 RRL_Obj02A_HeadingYawVnce "Variance of Object heading yaw angle";
CM_ SG_ 788 RRL_Obj02A_Dx "Object position in X direction";
CM_ SG_ 788 RRL_Obj02A_LengthVnce "Variance of Object Length";
CM_ SG_ 788 RRL_Obj02A_WidthVnce "Variance of Object Width";
CM_ SG_ 788 RRL_Obj02A_HeightVnce "Variance of Object Height";
CM_ SG_ 788 RRL_Obj02A_ExistProb "Existence probability of object";
CM_ SG_ 788 RRL_Obj02A_ProbObstacle "Probability of the object being an Obstacle";
CM_ SG_ 788 RRL_Obj02A_ProbNonObstacle "Probability of the object being a Non-Obstacle";
CM_ SG_ 788 RRL_Obj02A_ProbMobileObst "Probability of the object being a mobile obstacle";
CM_ SG_ 788 RRL_Obj02A_FV "SecOC Freshness Value (Profile 1)";
CM_ SG_ 788 RRL_Obj02A_MAC "SecOC MAC (Profile 1)";
CM_ SG_ 788 RRL_Obj02A_Dz "Object position in Z direction";
CM_ SG_ 788 RRL_Obj02A_Dy "Object position in Y direction";
CM_ SG_ 788 RRL_Obj02A_Valid "Object is valid or not";
CM_ SG_ 788 RRL_Obj02A_Vx "Object velocity in X direction";
CM_ SG_ 788 RRL_Obj02A_Vy "Object velocity in Y direction";
CM_ SG_ 788 RRL_Obj02A_Ax "Object acceleration in X direction";
CM_ SG_ 789 RRL_Obj02B_CRC "CRC - Autosar E2E Profile 5";
CM_ SG_ 789 RRL_Obj02B_MAC "SecOC MAC (Profile 1)";
CM_ SG_ 789 RRL_Obj02B_AliveCtr "Alive counter - Autosar E2E Profile 5";
CM_ SG_ 789 RRL_Obj02B_BlockCtr "Block-Counter";
CM_ SG_ 789 RRL_Obj02B_ProbMob4PlusWhl "Probability of a mobile object which has 4 or more wheels";
CM_ SG_ 789 RRL_Obj02B_ProbMob2Whl "Probability of a mobile object being 2-wheels vehicle";
CM_ SG_ 789 RRL_Obj02B_ProbMobPed "Probability of a mobile object being a pedestrian";
CM_ SG_ 789 RRL_Obj02B_Prob4PlusWhlCAR "Probability of a mobile object which has 4 or more wheels--passenger car";
CM_ SG_ 789 RRL_Obj02B_Prob4PlusWhlbHGV "Probability of a mobile object which has 4 or more wheels--commercial vehicle(Turck)";
CM_ SG_ 789 RRL_Obj02B_ProbGNDReflex "Probability of the object being a ground reflex";
CM_ SG_ 789 RRL_Obj02B_ProbStatBarrier "Probability of the object being a stationary road barrier";
CM_ SG_ 789 RRL_Obj02B_ProbStatObst "Probability of the object being a stationary obstacle";
CM_ SG_ 789 RRL_Obj02B_MovingProbability "Object has been observed moving over the ground";
CM_ SG_ 789 RRL_Obj02B_MovingObserved "Object has been observed moving over the ground since it was first detected";
CM_ SG_ 789 RRL_Obj02B_FV "SecOC Freshness Value (Profile 1)";
CM_ SG_ 790 RRL_Obj03A_CRC "CRC - Autosar E2E Profile 5";
CM_ SG_ 790 RRL_Obj03A_Ay "Object acceleration in Y direction";
CM_ SG_ 790 RRL_Obj03A_HeadingYawAngle "Object heading yaw angle";
CM_ SG_ 790 RRL_Obj03A_Length "Object Length";
CM_ SG_ 790 RRL_Obj03A_Width "Object Width";
CM_ SG_ 790 RRL_Obj03A_Height "Object Height";
CM_ SG_ 790 RRL_Obj03A_DxVnce "Variance of object position in X direction";
CM_ SG_ 790 RRL_Obj03A_DyVnce "Variance of object position in Y direction";
CM_ SG_ 790 RRL_Obj03A_DzVnce "Variance of object position in Z direction";
CM_ SG_ 790 RRL_Obj03A_AliveCtr "Alive counter - Autosar E2E Profile 5";
CM_ SG_ 790 RRL_Obj03A_VxVnce "Variance of object velocity in X direction";
CM_ SG_ 790 RRL_Obj03A_VyVnce "Variance of object velocity in Y direction";
CM_ SG_ 790 RRL_Obj03A_AxVnce "Variance of object acceleration in X direction";
CM_ SG_ 790 RRL_Obj03A_AyVnce "Variance of object acceleration in Y direction";
CM_ SG_ 790 RRL_Obj03A_RefPosIndex "Reference Position of the detected objects";
CM_ SG_ 790 RRL_Obj03A_DxDyCoVnce "Correlation coefficient of Dx and Dy";
CM_ SG_ 790 RRL_Obj03A_DxVxCoVnce "Correlation coefficient of Dx and Vx";
CM_ SG_ 790 RRL_Obj03A_BlockCtr "Block-Counter";
CM_ SG_ 790 RRL_Obj03A_DyVxCoVnce "Correlation coefficient of Dy and Ax";
CM_ SG_ 790 RRL_Obj03A_DxVyCoVnce "Correlation coefficient of Dx and Vy";
CM_ SG_ 790 RRL_Obj03A_DyVyCoVnce "Correlation coefficient of Dy and Vy";
CM_ SG_ 790 RRL_Obj03A_VxVyCoVnce "Correlation coefficient of Vx and Vy";
CM_ SG_ 790 RRL_Obj03A_DxAxCoVnce "Correlation coefficient of Dx and Ax";
CM_ SG_ 790 RRL_Obj03A_DyAxCoVnce "Correlation coefficient of Dy and Ax";
CM_ SG_ 790 RRL_Obj03A_VxAxCoVnce "Correlation coefficient of Vx and Ax";
CM_ SG_ 790 RRL_Obj03A_ObjectID "Unique Object ID";
CM_ SG_ 790 RRL_Obj03A_VyAxCoVnce "Correlation coefficient of Vy and Ax";
CM_ SG_ 790 RRL_Obj03A_DxAyCoVnce "Correlation coefficient of Dx and Ay";
CM_ SG_ 790 RRL_Obj03A_DyAyCoVnce "Correlation coefficient of Dy and Ay";
CM_ SG_ 790 RRL_Obj03A_VxAyCoVnce "Correlation coefficient of Vx and Ay";
CM_ SG_ 790 RRL_Obj03A_VyAyCoVnce "Correlation coefficient of Vy and Ay";
CM_ SG_ 790 RRL_Obj03A_AxAyCoVnce "Correlation coefficient of Ax and Ay";
CM_ SG_ 790 RRL_Obj03A_Measured "Object is measured or not";
CM_ SG_ 790 RRL_Obj03A_HeadingYawVnce "Variance of Object heading yaw angle";
CM_ SG_ 790 RRL_Obj03A_Dx "Object position in X direction";
CM_ SG_ 790 RRL_Obj03A_LengthVnce "Variance of Object Length";
CM_ SG_ 790 RRL_Obj03A_WidthVnce "Variance of Object Width";
CM_ SG_ 790 RRL_Obj03A_HeightVnce "Variance of Object Height";
CM_ SG_ 790 RRL_Obj03A_ExistProb "Existence probability of object";
CM_ SG_ 790 RRL_Obj03A_ProbObstacle "Probability of the object being an Obstacle";
CM_ SG_ 790 RRL_Obj03A_ProbNonObstacle "Probability of the object being a Non-Obstacle";
CM_ SG_ 790 RRL_Obj03A_ProbMobileObst "Probability of the object being a mobile obstacle";
CM_ SG_ 790 RRL_Obj03A_FV "SecOC Freshness Value (Profile 1)";
CM_ SG_ 790 RRL_Obj03A_MAC "SecOC MAC (Profile 1)";
CM_ SG_ 790 RRL_Obj03A_Dz "Object position in Z direction";
CM_ SG_ 790 RRL_Obj03A_Dy "Object position in Y direction";
CM_ SG_ 790 RRL_Obj03A_Valid "Object is valid or not";
CM_ SG_ 790 RRL_Obj03A_Vx "Object velocity in X direction";
CM_ SG_ 790 RRL_Obj03A_Vy "Object velocity in Y direction";
CM_ SG_ 790 RRL_Obj03A_Ax "Object acceleration in X direction";
CM_ SG_ 791 RRL_Obj03B_CRC "CRC - Autosar E2E Profile 5";
CM_ SG_ 791 RRL_Obj03B_MAC "SecOC MAC (Profile 1)";
CM_ SG_ 791 RRL_Obj03B_AliveCtr "Alive counter - Autosar E2E Profile 5";
CM_ SG_ 791 RRL_Obj03B_BlockCtr "Block-Counter";
CM_ SG_ 791 RRL_Obj03B_ProbMob4PlusWhl "Probability of a mobile object which has 4 or more wheels";
CM_ SG_ 791 RRL_Obj03B_ProbMob2Whl "Probability of a mobile object being 2-wheels vehicle";
CM_ SG_ 791 RRL_Obj03B_ProbMobPed "Probability of a mobile object being a pedestrian";
CM_ SG_ 791 RRL_Obj03B_Prob4PlusWhlCAR "Probability of a mobile object which has 4 or more wheels--passenger car";
CM_ SG_ 791 RRL_Obj03B_Prob4PlusWhlbHGV "Probability of a mobile object which has 4 or more wheels--commercial vehicle(Turck)";
CM_ SG_ 791 RRL_Obj03B_ProbGNDReflex "Probability of the object being a ground reflex";
CM_ SG_ 791 RRL_Obj03B_ProbStatBarrier "Probability of the object being a stationary road barrier";
CM_ SG_ 791 RRL_Obj03B_ProbStatObst "Probability of the object being a stationary obstacle";
CM_ SG_ 791 RRL_Obj03B_MovingProbability "Object has been observed moving over the ground";
CM_ SG_ 791 RRL_Obj03B_MovingObserved "Object has been observed moving over the ground since it was first detected";
CM_ SG_ 791 RRL_Obj03B_FV "SecOC Freshness Value (Profile 1)";
CM_ SG_ 792 RRL_Obj04A_CRC "CRC - Autosar E2E Profile 5";
CM_ SG_ 792 RRL_Obj04A_Ay "Object acceleration in Y direction";
CM_ SG_ 792 RRL_Obj04A_HeadingYawAngle "Object heading yaw angle";
CM_ SG_ 792 RRL_Obj04A_Length "Object Length";
CM_ SG_ 792 RRL_Obj04A_Width "Object Width";
CM_ SG_ 792 RRL_Obj04A_Height "Object Height";
CM_ SG_ 792 RRL_Obj04A_DxVnce "Variance of object position in X direction";
CM_ SG_ 792 RRL_Obj04A_DyVnce "Variance of object position in Y direction";
CM_ SG_ 792 RRL_Obj04A_DzVnce "Variance of object position in Z direction";
CM_ SG_ 792 RRL_Obj04A_AliveCtr "Alive counter - Autosar E2E Profile 5";
CM_ SG_ 792 RRL_Obj04A_VxVnce "Variance of object velocity in X direction";
CM_ SG_ 792 RRL_Obj04A_VyVnce "Variance of object velocity in Y direction";
CM_ SG_ 792 RRL_Obj04A_AxVnce "Variance of object acceleration in X direction";
CM_ SG_ 792 RRL_Obj04A_AyVnce "Variance of object acceleration in Y direction";
CM_ SG_ 792 RRL_Obj04A_RefPosIndex "Reference Position of the detected objects";
CM_ SG_ 792 RRL_Obj04A_DxDyCoVnce "Correlation coefficient of Dx and Dy";
CM_ SG_ 792 RRL_Obj04A_DxVxCoVnce "Correlation coefficient of Dx and Vx";
CM_ SG_ 792 RRL_Obj04A_BlockCtr "Block-Counter";
CM_ SG_ 792 RRL_Obj04A_DyVxCoVnce "Correlation coefficient of Dy and Ax";
CM_ SG_ 792 RRL_Obj04A_DxVyCoVnce "Correlation coefficient of Dx and Vy";
CM_ SG_ 792 RRL_Obj04A_DyVyCoVnce "Correlation coefficient of Dy and Vy";
CM_ SG_ 792 RRL_Obj04A_VxVyCoVnce "Correlation coefficient of Vx and Vy";
CM_ SG_ 792 RRL_Obj04A_DxAxCoVnce "Correlation coefficient of Dx and Ax";
CM_ SG_ 792 RRL_Obj04A_DyAxCoVnce "Correlation coefficient of Dy and Ax";
CM_ SG_ 792 RRL_Obj04A_VxAxCoVnce "Correlation coefficient of Vx and Ax";
CM_ SG_ 792 RRL_Obj04A_ObjectID "Unique Object ID";
CM_ SG_ 792 RRL_Obj04A_VyAxCoVnce "Correlation coefficient of Vy and Ax";
CM_ SG_ 792 RRL_Obj04A_DxAyCoVnce "Correlation coefficient of Dx and Ay";
CM_ SG_ 792 RRL_Obj04A_DyAyCoVnce "Correlation coefficient of Dy and Ay";
CM_ SG_ 792 RRL_Obj04A_VxAyCoVnce "Correlation coefficient of Vx and Ay";
CM_ SG_ 792 RRL_Obj04A_VyAyCoVnce "Correlation coefficient of Vy and Ay";
CM_ SG_ 792 RRL_Obj04A_AxAyCoVnce "Correlation coefficient of Ax and Ay";
CM_ SG_ 792 RRL_Obj04A_Measured "Object is measured or not";
CM_ SG_ 792 RRL_Obj04A_HeadingYawVnce "Variance of Object heading yaw angle";
CM_ SG_ 792 RRL_Obj04A_Dx "Object position in X direction";
CM_ SG_ 792 RRL_Obj04A_LengthVnce "Variance of Object Length";
CM_ SG_ 792 RRL_Obj04A_WidthVnce "Variance of Object Width";
CM_ SG_ 792 RRL_Obj04A_HeightVnce "Variance of Object Height";
CM_ SG_ 792 RRL_Obj04A_ExistProb "Existence probability of object";
CM_ SG_ 792 RRL_Obj04A_ProbObstacle "Probability of the object being an Obstacle";
CM_ SG_ 792 RRL_Obj04A_ProbNonObstacle "Probability of the object being a Non-Obstacle";
CM_ SG_ 792 RRL_Obj04A_ProbMobileObst "Probability of the object being a mobile obstacle";
CM_ SG_ 792 RRL_Obj04A_FV "SecOC Freshness Value (Profile 1)";
CM_ SG_ 792 RRL_Obj04A_MAC "SecOC MAC (Profile 1)";
CM_ SG_ 792 RRL_Obj04A_Dz "Object position in Z direction";
CM_ SG_ 792 RRL_Obj04A_Dy "Object position in Y direction";
CM_ SG_ 792 RRL_Obj04A_Valid "Object is valid or not";
CM_ SG_ 792 RRL_Obj04A_Vx "Object velocity in X direction";
CM_ SG_ 792 RRL_Obj04A_Vy "Object velocity in Y direction";
CM_ SG_ 792 RRL_Obj04A_Ax "Object acceleration in X direction";
CM_ SG_ 793 RRL_Obj04B_CRC "CRC - Autosar E2E Profile 5";
CM_ SG_ 793 RRL_Obj04B_MAC "SecOC MAC (Profile 1)";
CM_ SG_ 793 RRL_Obj04B_AliveCtr "Alive counter - Autosar E2E Profile 5";
CM_ SG_ 793 RRL_Obj04B_BlockCtr "Block-Counter";
CM_ SG_ 793 RRL_Obj04B_ProbMob4PlusWhl "Probability of a mobile object which has 4 or more wheels";
CM_ SG_ 793 RRL_Obj04B_ProbMob2Whl "Probability of a mobile object being 2-wheels vehicle";
CM_ SG_ 793 RRL_Obj04B_ProbMobPed "Probability of a mobile object being a pedestrian";
CM_ SG_ 793 RRL_Obj04B_Prob4PlusWhlCAR "Probability of a mobile object which has 4 or more wheels--passenger car";
CM_ SG_ 793 RRL_Obj04B_Prob4PlusWhlbHGV "Probability of a mobile object which has 4 or more wheels--commercial vehicle(Turck)";
CM_ SG_ 793 RRL_Obj04B_ProbGNDReflex "Probability of the object being a ground reflex";
CM_ SG_ 793 RRL_Obj04B_ProbStatBarrier "Probability of the object being a stationary road barrier";
CM_ SG_ 793 RRL_Obj04B_ProbStatObst "Probability of the object being a stationary obstacle";
CM_ SG_ 793 RRL_Obj04B_MovingProbability "Object has been observed moving over the ground";
CM_ SG_ 793 RRL_Obj04B_MovingObserved "Object has been observed moving over the ground since it was first detected";
CM_ SG_ 793 RRL_Obj04B_FV "SecOC Freshness Value (Profile 1)";
CM_ SG_ 794 RRL_Obj05A_CRC "CRC - Autosar E2E Profile 5";
CM_ SG_ 794 RRL_Obj05A_Ay "Object acceleration in Y direction";
CM_ SG_ 794 RRL_Obj05A_HeadingYawAngle "Object heading yaw angle";
CM_ SG_ 794 RRL_Obj05A_Length "Object Length";
CM_ SG_ 794 RRL_Obj05A_Width "Object Width";
CM_ SG_ 794 RRL_Obj05A_Height "Object Height";
CM_ SG_ 794 RRL_Obj05A_DxVnce "Variance of object position in X direction";
CM_ SG_ 794 RRL_Obj05A_DyVnce "Variance of object position in Y direction";
CM_ SG_ 794 RRL_Obj05A_DzVnce "Variance of object position in Z direction";
CM_ SG_ 794 RRL_Obj05A_AliveCtr "Alive counter - Autosar E2E Profile 5";
CM_ SG_ 794 RRL_Obj05A_VxVnce "Variance of object velocity in X direction";
CM_ SG_ 794 RRL_Obj05A_VyVnce "Variance of object velocity in Y direction";
CM_ SG_ 794 RRL_Obj05A_AxVnce "Variance of object acceleration in X direction";
CM_ SG_ 794 RRL_Obj05A_AyVnce "Variance of object acceleration in Y direction";
CM_ SG_ 794 RRL_Obj05A_RefPosIndex "Reference Position of the detected objects";
CM_ SG_ 794 RRL_Obj05A_DxDyCoVnce "Correlation coefficient of Dx and Dy";
CM_ SG_ 794 RRL_Obj05A_DxVxCoVnce "Correlation coefficient of Dx and Vx";
CM_ SG_ 794 RRL_Obj05A_BlockCtr "Block-Counter";
CM_ SG_ 794 RRL_Obj05A_DyVxCoVnce "Correlation coefficient of Dy and Ax";
CM_ SG_ 794 RRL_Obj05A_DxVyCoVnce "Correlation coefficient of Dx and Vy";
CM_ SG_ 794 RRL_Obj05A_DyVyCoVnce "Correlation coefficient of Dy and Vy";
CM_ SG_ 794 RRL_Obj05A_VxVyCoVnce "Correlation coefficient of Vx and Vy";
CM_ SG_ 794 RRL_Obj05A_DxAxCoVnce "Correlation coefficient of Dx and Ax";
CM_ SG_ 794 RRL_Obj05A_DyAxCoVnce "Correlation coefficient of Dy and Ax";
CM_ SG_ 794 RRL_Obj05A_VxAxCoVnce "Correlation coefficient of Vx and Ax";
CM_ SG_ 794 RRL_Obj05A_ObjectID "Unique Object ID";
CM_ SG_ 794 RRL_Obj05A_VyAxCoVnce "Correlation coefficient of Vy and Ax";
CM_ SG_ 794 RRL_Obj05A_DxAyCoVnce "Correlation coefficient of Dx and Ay";
CM_ SG_ 794 RRL_Obj05A_DyAyCoVnce "Correlation coefficient of Dy and Ay";
CM_ SG_ 794 RRL_Obj05A_VxAyCoVnce "Correlation coefficient of Vx and Ay";
CM_ SG_ 794 RRL_Obj05A_VyAyCoVnce "Correlation coefficient of Vy and Ay";
CM_ SG_ 794 RRL_Obj05A_AxAyCoVnce "Correlation coefficient of Ax and Ay";
CM_ SG_ 794 RRL_Obj05A_Measured "Object is measured or not";
CM_ SG_ 794 RRL_Obj05A_HeadingYawVnce "Variance of Object heading yaw angle";
CM_ SG_ 794 RRL_Obj05A_Dx "Object position in X direction";
CM_ SG_ 794 RRL_Obj05A_LengthVnce "Variance of Object Length";
CM_ SG_ 794 RRL_Obj05A_WidthVnce "Variance of Object Width";
CM_ SG_ 794 RRL_Obj05A_HeightVnce "Variance of Object Height";
CM_ SG_ 794 RRL_Obj05A_ExistProb "Existence probability of object";
CM_ SG_ 794 RRL_Obj05A_ProbObstacle "Probability of the object being an Obstacle";
CM_ SG_ 794 RRL_Obj05A_ProbNonObstacle "Probability of the object being a Non-Obstacle";
CM_ SG_ 794 RRL_Obj05A_ProbMobileObst "Probability of the object being a mobile obstacle";
CM_ SG_ 794 RRL_Obj05A_FV "SecOC Freshness Value (Profile 1)";
CM_ SG_ 794 RRL_Obj05A_MAC "SecOC MAC (Profile 1)";
CM_ SG_ 794 RRL_Obj05A_Dz "Object position in Z direction";
CM_ SG_ 794 RRL_Obj05A_Dy "Object position in Y direction";
CM_ SG_ 794 RRL_Obj05A_Valid "Object is valid or not";
CM_ SG_ 794 RRL_Obj05A_Vx "Object velocity in X direction";
CM_ SG_ 794 RRL_Obj05A_Vy "Object velocity in Y direction";
CM_ SG_ 794 RRL_Obj05A_Ax "Object acceleration in X direction";
CM_ SG_ 795 RRL_Obj05B_CRC "CRC - Autosar E2E Profile 5";
CM_ SG_ 795 RRL_Obj05B_MAC "SecOC MAC (Profile 1)";
CM_ SG_ 795 RRL_Obj05B_AliveCtr "Alive counter - Autosar E2E Profile 5";
CM_ SG_ 795 RRL_Obj05B_BlockCtr "Block-Counter";
CM_ SG_ 795 RRL_Obj05B_ProbMob4PlusWhl "Probability of a mobile object which has 4 or more wheels";
CM_ SG_ 795 RRL_Obj05B_ProbMob2Whl "Probability of a mobile object being 2-wheels vehicle";
CM_ SG_ 795 RRL_Obj05B_ProbMobPed "Probability of a mobile object being a pedestrian";
CM_ SG_ 795 RRL_Obj05B_Prob4PlusWhlCAR "Probability of a mobile object which has 4 or more wheels--passenger car";
CM_ SG_ 795 RRL_Obj05B_Prob4PlusWhlbHGV "Probability of a mobile object which has 4 or more wheels--commercial vehicle(Turck)";
CM_ SG_ 795 RRL_Obj05B_ProbGNDReflex "Probability of the object being a ground reflex";
CM_ SG_ 795 RRL_Obj05B_ProbStatBarrier "Probability of the object being a stationary road barrier";
CM_ SG_ 795 RRL_Obj05B_ProbStatObst "Probability of the object being a stationary obstacle";
CM_ SG_ 795 RRL_Obj05B_MovingProbability "Object has been observed moving over the ground";
CM_ SG_ 795 RRL_Obj05B_MovingObserved "Object has been observed moving over the ground since it was first detected";
CM_ SG_ 795 RRL_Obj05B_FV "SecOC Freshness Value (Profile 1)";
CM_ SG_ 796 RRL_Obj06A_CRC "CRC - Autosar E2E Profile 5";
CM_ SG_ 796 RRL_Obj06A_Ay "Object acceleration in Y direction";
CM_ SG_ 796 RRL_Obj06A_HeadingYawAngle "Object heading yaw angle";
CM_ SG_ 796 RRL_Obj06A_Length "Object Length";
CM_ SG_ 796 RRL_Obj06A_Width "Object Width";
CM_ SG_ 796 RRL_Obj06A_Height "Object Height";
CM_ SG_ 796 RRL_Obj06A_DxVnce "Variance of object position in X direction";
CM_ SG_ 796 RRL_Obj06A_DyVnce "Variance of object position in Y direction";
CM_ SG_ 796 RRL_Obj06A_DzVnce "Variance of object position in Z direction";
CM_ SG_ 796 RRL_Obj06A_AliveCtr "Alive counter - Autosar E2E Profile 5";
CM_ SG_ 796 RRL_Obj06A_VxVnce "Variance of object velocity in X direction";
CM_ SG_ 796 RRL_Obj06A_VyVnce "Variance of object velocity in Y direction";
CM_ SG_ 796 RRL_Obj06A_AxVnce "Variance of object acceleration in X direction";
CM_ SG_ 796 RRL_Obj06A_AyVnce "Variance of object acceleration in Y direction";
CM_ SG_ 796 RRL_Obj06A_RefPosIndex "Reference Position of the detected objects";
CM_ SG_ 796 RRL_Obj06A_DxDyCoVnce "Correlation coefficient of Dx and Dy";
CM_ SG_ 796 RRL_Obj06A_DxVxCoVnce "Correlation coefficient of Dx and Vx";
CM_ SG_ 796 RRL_Obj06A_BlockCtr "Block-Counter";
CM_ SG_ 796 RRL_Obj06A_DyVxCoVnce "Correlation coefficient of Dy and Ax";
CM_ SG_ 796 RRL_Obj06A_DxVyCoVnce "Correlation coefficient of Dx and Vy";
CM_ SG_ 796 RRL_Obj06A_DyVyCoVnce "Correlation coefficient of Dy and Vy";
CM_ SG_ 796 RRL_Obj06A_VxVyCoVnce "Correlation coefficient of Vx and Vy";
CM_ SG_ 796 RRL_Obj06A_DxAxCoVnce "Correlation coefficient of Dx and Ax";
CM_ SG_ 796 RRL_Obj06A_DyAxCoVnce "Correlation coefficient of Dy and Ax";
CM_ SG_ 796 RRL_Obj06A_VxAxCoVnce "Correlation coefficient of Vx and Ax";
CM_ SG_ 796 RRL_Obj06A_ObjectID "Unique Object ID";
CM_ SG_ 796 RRL_Obj06A_VyAxCoVnce "Correlation coefficient of Vy and Ax";
CM_ SG_ 796 RRL_Obj06A_DxAyCoVnce "Correlation coefficient of Dx and Ay";
CM_ SG_ 796 RRL_Obj06A_DyAyCoVnce "Correlation coefficient of Dy and Ay";
CM_ SG_ 796 RRL_Obj06A_VxAyCoVnce "Correlation coefficient of Vx and Ay";
CM_ SG_ 796 RRL_Obj06A_VyAyCoVnce "Correlation coefficient of Vy and Ay";
CM_ SG_ 796 RRL_Obj06A_AxAyCoVnce "Correlation coefficient of Ax and Ay";
CM_ SG_ 796 RRL_Obj06A_Measured "Object is measured or not";
CM_ SG_ 796 RRL_Obj06A_HeadingYawVnce "Variance of Object heading yaw angle";
CM_ SG_ 796 RRL_Obj06A_Dx "Object position in X direction";
CM_ SG_ 796 RRL_Obj06A_LengthVnce "Variance of Object Length";
CM_ SG_ 796 RRL_Obj06A_WidthVnce "Variance of Object Width";
CM_ SG_ 796 RRL_Obj06A_HeightVnce "Variance of Object Height";
CM_ SG_ 796 RRL_Obj06A_ExistProb "Existence probability of object";
CM_ SG_ 796 RRL_Obj06A_ProbObstacle "Probability of the object being an Obstacle";
CM_ SG_ 796 RRL_Obj06A_ProbNonObstacle "Probability of the object being a Non-Obstacle";
CM_ SG_ 796 RRL_Obj06A_ProbMobileObst "Probability of the object being a mobile obstacle";
CM_ SG_ 796 RRL_Obj06A_FV "SecOC Freshness Value (Profile 1)";
CM_ SG_ 796 RRL_Obj06A_MAC "SecOC MAC (Profile 1)";
CM_ SG_ 796 RRL_Obj06A_Dz "Object position in Z direction";
CM_ SG_ 796 RRL_Obj06A_Dy "Object position in Y direction";
CM_ SG_ 796 RRL_Obj06A_Valid "Object is valid or not";
CM_ SG_ 796 RRL_Obj06A_Vx "Object velocity in X direction";
CM_ SG_ 796 RRL_Obj06A_Vy "Object velocity in Y direction";
CM_ SG_ 796 RRL_Obj06A_Ax "Object acceleration in X direction";
CM_ SG_ 797 RRL_Obj06B_CRC "CRC - Autosar E2E Profile 5";
CM_ SG_ 797 RRL_Obj06B_MAC "SecOC MAC (Profile 1)";
CM_ SG_ 797 RRL_Obj06B_AliveCtr "Alive counter - Autosar E2E Profile 5";
CM_ SG_ 797 RRL_Obj06B_BlockCtr "Block-Counter";
CM_ SG_ 797 RRL_Obj06B_ProbMob4PlusWhl "Probability of a mobile object which has 4 or more wheels";
CM_ SG_ 797 RRL_Obj06B_ProbMob2Whl "Probability of a mobile object being 2-wheels vehicle";
CM_ SG_ 797 RRL_Obj06B_ProbMobPed "Probability of a mobile object being a pedestrian";
CM_ SG_ 797 RRL_Obj06B_Prob4PlusWhlCAR "Probability of a mobile object which has 4 or more wheels--passenger car";
CM_ SG_ 797 RRL_Obj06B_Prob4PlusWhlbHGV "Probability of a mobile object which has 4 or more wheels--commercial vehicle(Turck)";
CM_ SG_ 797 RRL_Obj06B_ProbGNDReflex "Probability of the object being a ground reflex";
CM_ SG_ 797 RRL_Obj06B_ProbStatBarrier "Probability of the object being a stationary road barrier";
CM_ SG_ 797 RRL_Obj06B_ProbStatObst "Probability of the object being a stationary obstacle";
CM_ SG_ 797 RRL_Obj06B_MovingProbability "Object has been observed moving over the ground";
CM_ SG_ 797 RRL_Obj06B_MovingObserved "Object has been observed moving over the ground since it was first detected";
CM_ SG_ 797 RRL_Obj06B_FV "SecOC Freshness Value (Profile 1)";
CM_ SG_ 798 RRL_Obj07A_CRC "CRC - Autosar E2E Profile 5";
CM_ SG_ 798 RRL_Obj07A_Ay "Object acceleration in Y direction";
CM_ SG_ 798 RRL_Obj07A_HeadingYawAngle "Object heading yaw angle";
CM_ SG_ 798 RRL_Obj07A_Length "Object Length";
CM_ SG_ 798 RRL_Obj07A_Width "Object Width";
CM_ SG_ 798 RRL_Obj07A_Height "Object Height";
CM_ SG_ 798 RRL_Obj07A_DxVnce "Variance of object position in X direction";
CM_ SG_ 798 RRL_Obj07A_DyVnce "Variance of object position in Y direction";
CM_ SG_ 798 RRL_Obj07A_DzVnce "Variance of object position in Z direction";
CM_ SG_ 798 RRL_Obj07A_AliveCtr "Alive counter - Autosar E2E Profile 5";
CM_ SG_ 798 RRL_Obj07A_VxVnce "Variance of object velocity in X direction";
CM_ SG_ 798 RRL_Obj07A_VyVnce "Variance of object velocity in Y direction";
CM_ SG_ 798 RRL_Obj07A_AxVnce "Variance of object acceleration in X direction";
CM_ SG_ 798 RRL_Obj07A_AyVnce "Variance of object acceleration in Y direction";
CM_ SG_ 798 RRL_Obj07A_RefPosIndex "Reference Position of the detected objects";
CM_ SG_ 798 RRL_Obj07A_DxDyCoVnce "Correlation coefficient of Dx and Dy";
CM_ SG_ 798 RRL_Obj07A_DxVxCoVnce "Correlation coefficient of Dx and Vx";
CM_ SG_ 798 RRL_Obj07A_BlockCtr "Block-Counter";
CM_ SG_ 798 RRL_Obj07A_DyVxCoVnce "Correlation coefficient of Dy and Ax";
CM_ SG_ 798 RRL_Obj07A_DxVyCoVnce "Correlation coefficient of Dx and Vy";
CM_ SG_ 798 RRL_Obj07A_DyVyCoVnce "Correlation coefficient of Dy and Vy";
CM_ SG_ 798 RRL_Obj07A_VxVyCoVnce "Correlation coefficient of Vx and Vy";
CM_ SG_ 798 RRL_Obj07A_DxAxCoVnce "Correlation coefficient of Dx and Ax";
CM_ SG_ 798 RRL_Obj07A_DyAxCoVnce "Correlation coefficient of Dy and Ax";
CM_ SG_ 798 RRL_Obj07A_VxAxCoVnce "Correlation coefficient of Vx and Ax";
CM_ SG_ 798 RRL_Obj07A_ObjectID "Unique Object ID";
CM_ SG_ 798 RRL_Obj07A_VyAxCoVnce "Correlation coefficient of Vy and Ax";
CM_ SG_ 798 RRL_Obj07A_DxAyCoVnce "Correlation coefficient of Dx and Ay";
CM_ SG_ 798 RRL_Obj07A_DyAyCoVnce "Correlation coefficient of Dy and Ay";
CM_ SG_ 798 RRL_Obj07A_VxAyCoVnce "Correlation coefficient of Vx and Ay";
CM_ SG_ 798 RRL_Obj07A_VyAyCoVnce "Correlation coefficient of Vy and Ay";
CM_ SG_ 798 RRL_Obj07A_AxAyCoVnce "Correlation coefficient of Ax and Ay";
CM_ SG_ 798 RRL_Obj07A_Measured "Object is measured or not";
CM_ SG_ 798 RRL_Obj07A_HeadingYawVnce "Variance of Object heading yaw angle";
CM_ SG_ 798 RRL_Obj07A_Dx "Object position in X direction";
CM_ SG_ 798 RRL_Obj07A_LengthVnce "Variance of Object Length";
CM_ SG_ 798 RRL_Obj07A_WidthVnce "Variance of Object Width";
CM_ SG_ 798 RRL_Obj07A_HeightVnce "Variance of Object Height";
CM_ SG_ 798 RRL_Obj07A_ExistProb "Existence probability of object";
CM_ SG_ 798 RRL_Obj07A_ProbObstacle "Probability of the object being an Obstacle";
CM_ SG_ 798 RRL_Obj07A_ProbNonObstacle "Probability of the object being a Non-Obstacle";
CM_ SG_ 798 RRL_Obj07A_ProbMobileObst "Probability of the object being a mobile obstacle";
CM_ SG_ 798 RRL_Obj07A_FV "SecOC Freshness Value (Profile 1)";
CM_ SG_ 798 RRL_Obj07A_MAC "SecOC MAC (Profile 1)";
CM_ SG_ 798 RRL_Obj07A_Dz "Object position in Z direction";
CM_ SG_ 798 RRL_Obj07A_Dy "Object position in Y direction";
CM_ SG_ 798 RRL_Obj07A_Valid "Object is valid or not";
CM_ SG_ 798 RRL_Obj07A_Vx "Object velocity in X direction";
CM_ SG_ 798 RRL_Obj07A_Vy "Object velocity in Y direction";
CM_ SG_ 798 RRL_Obj07A_Ax "Object acceleration in X direction";
CM_ SG_ 799 RRL_Obj07B_CRC "CRC - Autosar E2E Profile 5";
CM_ SG_ 799 RRL_Obj07B_MAC "SecOC MAC (Profile 1)";
CM_ SG_ 799 RRL_Obj07B_AliveCtr "Alive counter - Autosar E2E Profile 5";
CM_ SG_ 799 RRL_Obj07B_BlockCtr "Block-Counter";
CM_ SG_ 799 RRL_Obj07B_ProbMob4PlusWhl "Probability of a mobile object which has 4 or more wheels";
CM_ SG_ 799 RRL_Obj07B_ProbMob2Whl "Probability of a mobile object being 2-wheels vehicle";
CM_ SG_ 799 RRL_Obj07B_ProbMobPed "Probability of a mobile object being a pedestrian";
CM_ SG_ 799 RRL_Obj07B_Prob4PlusWhlCAR "Probability of a mobile object which has 4 or more wheels--passenger car";
CM_ SG_ 799 RRL_Obj07B_Prob4PlusWhlbHGV "Probability of a mobile object which has 4 or more wheels--commercial vehicle(Turck)";
CM_ SG_ 799 RRL_Obj07B_ProbGNDReflex "Probability of the object being a ground reflex";
CM_ SG_ 799 RRL_Obj07B_ProbStatBarrier "Probability of the object being a stationary road barrier";
CM_ SG_ 799 RRL_Obj07B_ProbStatObst "Probability of the object being a stationary obstacle";
CM_ SG_ 799 RRL_Obj07B_MovingProbability "Object has been observed moving over the ground";
CM_ SG_ 799 RRL_Obj07B_MovingObserved "Object has been observed moving over the ground since it was first detected";
CM_ SG_ 799 RRL_Obj07B_FV "SecOC Freshness Value (Profile 1)";
CM_ SG_ 800 RRL_Obj08A_CRC "CRC - Autosar E2E Profile 5";
CM_ SG_ 800 RRL_Obj08A_Ay "Object acceleration in Y direction";
CM_ SG_ 800 RRL_Obj08A_HeadingYawAngle "Object heading yaw angle";
CM_ SG_ 800 RRL_Obj08A_Length "Object Length";
CM_ SG_ 800 RRL_Obj08A_Width "Object Width";
CM_ SG_ 800 RRL_Obj08A_Height "Object Height";
CM_ SG_ 800 RRL_Obj08A_DxVnce "Variance of object position in X direction";
CM_ SG_ 800 RRL_Obj08A_DyVnce "Variance of object position in Y direction";
CM_ SG_ 800 RRL_Obj08A_DzVnce "Variance of object position in Z direction";
CM_ SG_ 800 RRL_Obj08A_AliveCtr "Alive counter - Autosar E2E Profile 5";
CM_ SG_ 800 RRL_Obj08A_VxVnce "Variance of object velocity in X direction";
CM_ SG_ 800 RRL_Obj08A_VyVnce "Variance of object velocity in Y direction";
CM_ SG_ 800 RRL_Obj08A_AxVnce "Variance of object acceleration in X direction";
CM_ SG_ 800 RRL_Obj08A_AyVnce "Variance of object acceleration in Y direction";
CM_ SG_ 800 RRL_Obj08A_RefPosIndex "Reference Position of the detected objects";
CM_ SG_ 800 RRL_Obj08A_DxDyCoVnce "Correlation coefficient of Dx and Dy";
CM_ SG_ 800 RRL_Obj08A_DxVxCoVnce "Correlation coefficient of Dx and Vx";
CM_ SG_ 800 RRL_Obj08A_BlockCtr "Block-Counter";
CM_ SG_ 800 RRL_Obj08A_DyVxCoVnce "Correlation coefficient of Dy and Ax";
CM_ SG_ 800 RRL_Obj08A_DxVyCoVnce "Correlation coefficient of Dx and Vy";
CM_ SG_ 800 RRL_Obj08A_DyVyCoVnce "Correlation coefficient of Dy and Vy";
CM_ SG_ 800 RRL_Obj08A_VxVyCoVnce "Correlation coefficient of Vx and Vy";
CM_ SG_ 800 RRL_Obj08A_DxAxCoVnce "Correlation coefficient of Dx and Ax";
CM_ SG_ 800 RRL_Obj08A_DyAxCoVnce "Correlation coefficient of Dy and Ax";
CM_ SG_ 800 RRL_Obj08A_VxAxCoVnce "Correlation coefficient of Vx and Ax";
CM_ SG_ 800 RRL_Obj08A_ObjectID "Unique Object ID";
CM_ SG_ 800 RRL_Obj08A_VyAxCoVnce "Correlation coefficient of Vy and Ax";
CM_ SG_ 800 RRL_Obj08A_DxAyCoVnce "Correlation coefficient of Dx and Ay";
CM_ SG_ 800 RRL_Obj08A_DyAyCoVnce "Correlation coefficient of Dy and Ay";
CM_ SG_ 800 RRL_Obj08A_VxAyCoVnce "Correlation coefficient of Vx and Ay";
CM_ SG_ 800 RRL_Obj08A_VyAyCoVnce "Correlation coefficient of Vy and Ay";
CM_ SG_ 800 RRL_Obj08A_AxAyCoVnce "Correlation coefficient of Ax and Ay";
CM_ SG_ 800 RRL_Obj08A_Measured "Object is measured or not";
CM_ SG_ 800 RRL_Obj08A_HeadingYawVnce "Variance of Object heading yaw angle";
CM_ SG_ 800 RRL_Obj08A_Dx "Object position in X direction";
CM_ SG_ 800 RRL_Obj08A_LengthVnce "Variance of Object Length";
CM_ SG_ 800 RRL_Obj08A_WidthVnce "Variance of Object Width";
CM_ SG_ 800 RRL_Obj08A_HeightVnce "Variance of Object Height";
CM_ SG_ 800 RRL_Obj08A_ExistProb "Existence probability of object";
CM_ SG_ 800 RRL_Obj08A_ProbObstacle "Probability of the object being an Obstacle";
CM_ SG_ 800 RRL_Obj08A_ProbNonObstacle "Probability of the object being a Non-Obstacle";
CM_ SG_ 800 RRL_Obj08A_ProbMobileObst "Probability of the object being a mobile obstacle";
CM_ SG_ 800 RRL_Obj08A_FV "SecOC Freshness Value (Profile 1)";
CM_ SG_ 800 RRL_Obj08A_MAC "SecOC MAC (Profile 1)";
CM_ SG_ 800 RRL_Obj08A_Dz "Object position in Z direction";
CM_ SG_ 800 RRL_Obj08A_Dy "Object position in Y direction";
CM_ SG_ 800 RRL_Obj08A_Valid "Object is valid or not";
CM_ SG_ 800 RRL_Obj08A_Vx "Object velocity in X direction";
CM_ SG_ 800 RRL_Obj08A_Vy "Object velocity in Y direction";
CM_ SG_ 800 RRL_Obj08A_Ax "Object acceleration in X direction";
CM_ SG_ 801 RRL_Obj08B_CRC "CRC - Autosar E2E Profile 5";
CM_ SG_ 801 RRL_Obj08B_MAC "SecOC MAC (Profile 1)";
CM_ SG_ 801 RRL_Obj08B_AliveCtr "Alive counter - Autosar E2E Profile 5";
CM_ SG_ 801 RRL_Obj08B_BlockCtr "Block-Counter";
CM_ SG_ 801 RRL_Obj08B_ProbMob4PlusWhl "Probability of a mobile object which has 4 or more wheels";
CM_ SG_ 801 RRL_Obj08B_ProbMob2Whl "Probability of a mobile object being 2-wheels vehicle";
CM_ SG_ 801 RRL_Obj08B_ProbMobPed "Probability of a mobile object being a pedestrian";
CM_ SG_ 801 RRL_Obj08B_Prob4PlusWhlCAR "Probability of a mobile object which has 4 or more wheels--passenger car";
CM_ SG_ 801 RRL_Obj08B_Prob4PlusWhlbHGV "Probability of a mobile object which has 4 or more wheels--commercial vehicle(Turck)";
CM_ SG_ 801 RRL_Obj08B_ProbGNDReflex "Probability of the object being a ground reflex";
CM_ SG_ 801 RRL_Obj08B_ProbStatBarrier "Probability of the object being a stationary road barrier";
CM_ SG_ 801 RRL_Obj08B_ProbStatObst "Probability of the object being a stationary obstacle";
CM_ SG_ 801 RRL_Obj08B_MovingProbability "Object has been observed moving over the ground";
CM_ SG_ 801 RRL_Obj08B_MovingObserved "Object has been observed moving over the ground since it was first detected";
CM_ SG_ 801 RRL_Obj08B_FV "SecOC Freshness Value (Profile 1)";
CM_ SG_ 802 RRL_Obj09A_CRC "CRC - Autosar E2E Profile 5";
CM_ SG_ 802 RRL_Obj09A_Ay "Object acceleration in Y direction";
CM_ SG_ 802 RRL_Obj09A_HeadingYawAngle "Object heading yaw angle";
CM_ SG_ 802 RRL_Obj09A_Length "Object Length";
CM_ SG_ 802 RRL_Obj09A_Width "Object Width";
CM_ SG_ 802 RRL_Obj09A_Height "Object Height";
CM_ SG_ 802 RRL_Obj09A_DxVnce "Variance of object position in X direction";
CM_ SG_ 802 RRL_Obj09A_DyVnce "Variance of object position in Y direction";
CM_ SG_ 802 RRL_Obj09A_DzVnce "Variance of object position in Z direction";
CM_ SG_ 802 RRL_Obj09A_AliveCtr "Alive counter - Autosar E2E Profile 5";
CM_ SG_ 802 RRL_Obj09A_VxVnce "Variance of object velocity in X direction";
CM_ SG_ 802 RRL_Obj09A_VyVnce "Variance of object velocity in Y direction";
CM_ SG_ 802 RRL_Obj09A_AxVnce "Variance of object acceleration in X direction";
CM_ SG_ 802 RRL_Obj09A_AyVnce "Variance of object acceleration in Y direction";
CM_ SG_ 802 RRL_Obj09A_RefPosIndex "Reference Position of the detected objects";
CM_ SG_ 802 RRL_Obj09A_DxDyCoVnce "Correlation coefficient of Dx and Dy";
CM_ SG_ 802 RRL_Obj09A_DxVxCoVnce "Correlation coefficient of Dx and Vx";
CM_ SG_ 802 RRL_Obj09A_BlockCtr "Block-Counter";
CM_ SG_ 802 RRL_Obj09A_DyVxCoVnce "Correlation coefficient of Dy and Ax";
CM_ SG_ 802 RRL_Obj09A_DxVyCoVnce "Correlation coefficient of Dx and Vy";
CM_ SG_ 802 RRL_Obj09A_DyVyCoVnce "Correlation coefficient of Dy and Vy";
CM_ SG_ 802 RRL_Obj09A_VxVyCoVnce "Correlation coefficient of Vx and Vy";
CM_ SG_ 802 RRL_Obj09A_DxAxCoVnce "Correlation coefficient of Dx and Ax";
CM_ SG_ 802 RRL_Obj09A_DyAxCoVnce "Correlation coefficient of Dy and Ax";
CM_ SG_ 802 RRL_Obj09A_VxAxCoVnce "Correlation coefficient of Vx and Ax";
CM_ SG_ 802 RRL_Obj09A_ObjectID "Unique Object ID";
CM_ SG_ 802 RRL_Obj09A_VyAxCoVnce "Correlation coefficient of Vy and Ax";
CM_ SG_ 802 RRL_Obj09A_DxAyCoVnce "Correlation coefficient of Dx and Ay";
CM_ SG_ 802 RRL_Obj09A_DyAyCoVnce "Correlation coefficient of Dy and Ay";
CM_ SG_ 802 RRL_Obj09A_VxAyCoVnce "Correlation coefficient of Vx and Ay";
CM_ SG_ 802 RRL_Obj09A_VyAyCoVnce "Correlation coefficient of Vy and Ay";
CM_ SG_ 802 RRL_Obj09A_AxAyCoVnce "Correlation coefficient of Ax and Ay";
CM_ SG_ 802 RRL_Obj09A_Measured "Object is measured or not";
CM_ SG_ 802 RRL_Obj09A_HeadingYawVnce "Variance of Object heading yaw angle";
CM_ SG_ 802 RRL_Obj09A_Dx "Object position in X direction";
CM_ SG_ 802 RRL_Obj09A_LengthVnce "Variance of Object Length";
CM_ SG_ 802 RRL_Obj09A_WidthVnce "Variance of Object Width";
CM_ SG_ 802 RRL_Obj09A_HeightVnce "Variance of Object Height";
CM_ SG_ 802 RRL_Obj09A_ExistProb "Existence probability of object";
CM_ SG_ 802 RRL_Obj09A_ProbObstacle "Probability of the object being an Obstacle";
CM_ SG_ 802 RRL_Obj09A_ProbNonObstacle "Probability of the object being a Non-Obstacle";
CM_ SG_ 802 RRL_Obj09A_ProbMobileObst "Probability of the object being a mobile obstacle";
CM_ SG_ 802 RRL_Obj09A_FV "SecOC Freshness Value (Profile 1)";
CM_ SG_ 802 RRL_Obj09A_MAC "SecOC MAC (Profile 1)";
CM_ SG_ 802 RRL_Obj09A_Dz "Object position in Z direction";
CM_ SG_ 802 RRL_Obj09A_Dy "Object position in Y direction";
CM_ SG_ 802 RRL_Obj09A_Valid "Object is valid or not";
CM_ SG_ 802 RRL_Obj09A_Vx "Object velocity in X direction";
CM_ SG_ 802 RRL_Obj09A_Vy "Object velocity in Y direction";
CM_ SG_ 802 RRL_Obj09A_Ax "Object acceleration in X direction";
CM_ SG_ 803 RRL_Obj09B_CRC "CRC - Autosar E2E Profile 5";
CM_ SG_ 803 RRL_Obj09B_MAC "SecOC MAC (Profile 1)";
CM_ SG_ 803 RRL_Obj09B_AliveCtr "Alive counter - Autosar E2E Profile 5";
CM_ SG_ 803 RRL_Obj09B_BlockCtr "Block-Counter";
CM_ SG_ 803 RRL_Obj09B_ProbMob4PlusWhl "Probability of a mobile object which has 4 or more wheels";
CM_ SG_ 803 RRL_Obj09B_ProbMob2Whl "Probability of a mobile object being 2-wheels vehicle";
CM_ SG_ 803 RRL_Obj09B_ProbMobPed "Probability of a mobile object being a pedestrian";
CM_ SG_ 803 RRL_Obj09B_Prob4PlusWhlCAR "Probability of a mobile object which has 4 or more wheels--passenger car";
CM_ SG_ 803 RRL_Obj09B_Prob4PlusWhlbHGV "Probability of a mobile object which has 4 or more wheels--commercial vehicle(Turck)";
CM_ SG_ 803 RRL_Obj09B_ProbGNDReflex "Probability of the object being a ground reflex";
CM_ SG_ 803 RRL_Obj09B_ProbStatBarrier "Probability of the object being a stationary road barrier";
CM_ SG_ 803 RRL_Obj09B_ProbStatObst "Probability of the object being a stationary obstacle";
CM_ SG_ 803 RRL_Obj09B_MovingProbability "Object has been observed moving over the ground";
CM_ SG_ 803 RRL_Obj09B_MovingObserved "Object has been observed moving over the ground since it was first detected";
CM_ SG_ 803 RRL_Obj09B_FV "SecOC Freshness Value (Profile 1)";
CM_ SG_ 804 RRL_Obj10A_CRC "CRC - Autosar E2E Profile 5";
CM_ SG_ 804 RRL_Obj10A_Ay "Object acceleration in Y direction";
CM_ SG_ 804 RRL_Obj10A_HeadingYawAngle "Object heading yaw angle";
CM_ SG_ 804 RRL_Obj10A_Length "Object Length";
CM_ SG_ 804 RRL_Obj10A_Width "Object Width";
CM_ SG_ 804 RRL_Obj10A_Height "Object Height";
CM_ SG_ 804 RRL_Obj10A_DxVnce "Variance of object position in X direction";
CM_ SG_ 804 RRL_Obj10A_DyVnce "Variance of object position in Y direction";
CM_ SG_ 804 RRL_Obj10A_DzVnce "Variance of object position in Z direction";
CM_ SG_ 804 RRL_Obj10A_AliveCtr "Alive counter - Autosar E2E Profile 5";
CM_ SG_ 804 RRL_Obj10A_VxVnce "Variance of object velocity in X direction";
CM_ SG_ 804 RRL_Obj10A_VyVnce "Variance of object velocity in Y direction";
CM_ SG_ 804 RRL_Obj10A_AxVnce "Variance of object acceleration in X direction";
CM_ SG_ 804 RRL_Obj10A_AyVnce "Variance of object acceleration in Y direction";
CM_ SG_ 804 RRL_Obj10A_RefPosIndex "Reference Position of the detected objects";
CM_ SG_ 804 RRL_Obj10A_DxDyCoVnce "Correlation coefficient of Dx and Dy";
CM_ SG_ 804 RRL_Obj10A_DxVxCoVnce "Correlation coefficient of Dx and Vx";
CM_ SG_ 804 RRL_Obj10A_BlockCtr "Block-Counter";
CM_ SG_ 804 RRL_Obj10A_DyVxCoVnce "Correlation coefficient of Dy and Ax";
CM_ SG_ 804 RRL_Obj10A_DxVyCoVnce "Correlation coefficient of Dx and Vy";
CM_ SG_ 804 RRL_Obj10A_DyVyCoVnce "Correlation coefficient of Dy and Vy";
CM_ SG_ 804 RRL_Obj10A_VxVyCoVnce "Correlation coefficient of Vx and Vy";
CM_ SG_ 804 RRL_Obj10A_DxAxCoVnce "Correlation coefficient of Dx and Ax";
CM_ SG_ 804 RRL_Obj10A_DyAxCoVnce "Correlation coefficient of Dy and Ax";
CM_ SG_ 804 RRL_Obj10A_VxAxCoVnce "Correlation coefficient of Vx and Ax";
CM_ SG_ 804 RRL_Obj10A_ObjectID "Unique Object ID";
CM_ SG_ 804 RRL_Obj10A_VyAxCoVnce "Correlation coefficient of Vy and Ax";
CM_ SG_ 804 RRL_Obj10A_DxAyCoVnce "Correlation coefficient of Dx and Ay";
CM_ SG_ 804 RRL_Obj10A_DyAyCoVnce "Correlation coefficient of Dy and Ay";
CM_ SG_ 804 RRL_Obj10A_VxAyCoVnce "Correlation coefficient of Vx and Ay";
CM_ SG_ 804 RRL_Obj10A_VyAyCoVnce "Correlation coefficient of Vy and Ay";
CM_ SG_ 804 RRL_Obj10A_AxAyCoVnce "Correlation coefficient of Ax and Ay";
CM_ SG_ 804 RRL_Obj10A_Measured "Object is measured or not";
CM_ SG_ 804 RRL_Obj10A_HeadingYawVnce "Variance of Object heading yaw angle";
CM_ SG_ 804 RRL_Obj10A_Dx "Object position in X direction";
CM_ SG_ 804 RRL_Obj10A_LengthVnce "Variance of Object Length";
CM_ SG_ 804 RRL_Obj10A_WidthVnce "Variance of Object Width";
CM_ SG_ 804 RRL_Obj10A_HeightVnce "Variance of Object Height";
CM_ SG_ 804 RRL_Obj10A_ExistProb "Existence probability of object";
CM_ SG_ 804 RRL_Obj10A_ProbObstacle "Probability of the object being an Obstacle";
CM_ SG_ 804 RRL_Obj10A_ProbNonObstacle "Probability of the object being a Non-Obstacle";
CM_ SG_ 804 RRL_Obj10A_ProbMobileObst "Probability of the object being a mobile obstacle";
CM_ SG_ 804 RRL_Obj10A_FV "SecOC Freshness Value (Profile 1)";
CM_ SG_ 804 RRL_Obj10A_MAC "SecOC MAC (Profile 1)";
CM_ SG_ 804 RRL_Obj10A_Dz "Object position in Z direction";
CM_ SG_ 804 RRL_Obj10A_Dy "Object position in Y direction";
CM_ SG_ 804 RRL_Obj10A_Valid "Object is valid or not";
CM_ SG_ 804 RRL_Obj10A_Vx "Object velocity in X direction";
CM_ SG_ 804 RRL_Obj10A_Vy "Object velocity in Y direction";
CM_ SG_ 804 RRL_Obj10A_Ax "Object acceleration in X direction";
CM_ SG_ 805 RRL_Obj10B_CRC "CRC - Autosar E2E Profile 5";
CM_ SG_ 805 RRL_Obj10B_MAC "SecOC MAC (Profile 1)";
CM_ SG_ 805 RRL_Obj10B_AliveCtr "Alive counter - Autosar E2E Profile 5";
CM_ SG_ 805 RRL_Obj10B_BlockCtr "Block-Counter";
CM_ SG_ 805 RRL_Obj10B_ProbMob4PlusWhl "Probability of a mobile object which has 4 or more wheels";
CM_ SG_ 805 RRL_Obj10B_ProbMob2Whl "Probability of a mobile object being 2-wheels vehicle";
CM_ SG_ 805 RRL_Obj10B_ProbMobPed "Probability of a mobile object being a pedestrian";
CM_ SG_ 805 RRL_Obj10B_Prob4PlusWhlCAR "Probability of a mobile object which has 4 or more wheels--passenger car";
CM_ SG_ 805 RRL_Obj10B_Prob4PlusWhlbHGV "Probability of a mobile object which has 4 or more wheels--commercial vehicle(Turck)";
CM_ SG_ 805 RRL_Obj10B_ProbGNDReflex "Probability of the object being a ground reflex";
CM_ SG_ 805 RRL_Obj10B_ProbStatBarrier "Probability of the object being a stationary road barrier";
CM_ SG_ 805 RRL_Obj10B_ProbStatObst "Probability of the object being a stationary obstacle";
CM_ SG_ 805 RRL_Obj10B_MovingProbability "Object has been observed moving over the ground";
CM_ SG_ 805 RRL_Obj10B_MovingObserved "Object has been observed moving over the ground since it was first detected";
CM_ SG_ 805 RRL_Obj10B_FV "SecOC Freshness Value (Profile 1)";
CM_ SG_ 806 RRL_Obj11A_CRC "CRC - Autosar E2E Profile 5";
CM_ SG_ 806 RRL_Obj11A_Ay "Object acceleration in Y direction";
CM_ SG_ 806 RRL_Obj11A_HeadingYawAngle "Object heading yaw angle";
CM_ SG_ 806 RRL_Obj11A_Length "Object Length";
CM_ SG_ 806 RRL_Obj11A_Width "Object Width";
CM_ SG_ 806 RRL_Obj11A_Height "Object Height";
CM_ SG_ 806 RRL_Obj11A_DxVnce "Variance of object position in X direction";
CM_ SG_ 806 RRL_Obj11A_DyVnce "Variance of object position in Y direction";
CM_ SG_ 806 RRL_Obj11A_DzVnce "Variance of object position in Z direction";
CM_ SG_ 806 RRL_Obj11A_AliveCtr "Alive counter - Autosar E2E Profile 5";
CM_ SG_ 806 RRL_Obj11A_VxVnce "Variance of object velocity in X direction";
CM_ SG_ 806 RRL_Obj11A_VyVnce "Variance of object velocity in Y direction";
CM_ SG_ 806 RRL_Obj11A_AxVnce "Variance of object acceleration in X direction";
CM_ SG_ 806 RRL_Obj11A_AyVnce "Variance of object acceleration in Y direction";
CM_ SG_ 806 RRL_Obj11A_RefPosIndex "Reference Position of the detected objects";
CM_ SG_ 806 RRL_Obj11A_DxDyCoVnce "Correlation coefficient of Dx and Dy";
CM_ SG_ 806 RRL_Obj11A_DxVxCoVnce "Correlation coefficient of Dx and Vx";
CM_ SG_ 806 RRL_Obj11A_BlockCtr "Block-Counter";
CM_ SG_ 806 RRL_Obj11A_DyVxCoVnce "Correlation coefficient of Dy and Ax";
CM_ SG_ 806 RRL_Obj11A_DxVyCoVnce "Correlation coefficient of Dx and Vy";
CM_ SG_ 806 RRL_Obj11A_DyVyCoVnce "Correlation coefficient of Dy and Vy";
CM_ SG_ 806 RRL_Obj11A_VxVyCoVnce "Correlation coefficient of Vx and Vy";
CM_ SG_ 806 RRL_Obj11A_DxAxCoVnce "Correlation coefficient of Dx and Ax";
CM_ SG_ 806 RRL_Obj11A_DyAxCoVnce "Correlation coefficient of Dy and Ax";
CM_ SG_ 806 RRL_Obj11A_VxAxCoVnce "Correlation coefficient of Vx and Ax";
CM_ SG_ 806 RRL_Obj11A_ObjectID "Unique Object ID";
CM_ SG_ 806 RRL_Obj11A_VyAxCoVnce "Correlation coefficient of Vy and Ax";
CM_ SG_ 806 RRL_Obj11A_DxAyCoVnce "Correlation coefficient of Dx and Ay";
CM_ SG_ 806 RRL_Obj11A_DyAyCoVnce "Correlation coefficient of Dy and Ay";
CM_ SG_ 806 RRL_Obj11A_VxAyCoVnce "Correlation coefficient of Vx and Ay";
CM_ SG_ 806 RRL_Obj11A_VyAyCoVnce "Correlation coefficient of Vy and Ay";
CM_ SG_ 806 RRL_Obj11A_AxAyCoVnce "Correlation coefficient of Ax and Ay";
CM_ SG_ 806 RRL_Obj11A_Measured "Object is measured or not";
CM_ SG_ 806 RRL_Obj11A_HeadingYawVnce "Variance of Object heading yaw angle";
CM_ SG_ 806 RRL_Obj11A_Dx "Object position in X direction";
CM_ SG_ 806 RRL_Obj11A_LengthVnce "Variance of Object Length";
CM_ SG_ 806 RRL_Obj11A_WidthVnce "Variance of Object Width";
CM_ SG_ 806 RRL_Obj11A_HeightVnce "Variance of Object Height";
CM_ SG_ 806 RRL_Obj11A_ExistProb "Existence probability of object";
CM_ SG_ 806 RRL_Obj11A_ProbObstacle "Probability of the object being an Obstacle";
CM_ SG_ 806 RRL_Obj11A_ProbNonObstacle "Probability of the object being a Non-Obstacle";
CM_ SG_ 806 RRL_Obj11A_ProbMobileObst "Probability of the object being a mobile obstacle";
CM_ SG_ 806 RRL_Obj11A_FV "SecOC Freshness Value (Profile 1)";
CM_ SG_ 806 RRL_Obj11A_MAC "SecOC MAC (Profile 1)";
CM_ SG_ 806 RRL_Obj11A_Dz "Object position in Z direction";
CM_ SG_ 806 RRL_Obj11A_Dy "Object position in Y direction";
CM_ SG_ 806 RRL_Obj11A_Valid "Object is valid or not";
CM_ SG_ 806 RRL_Obj11A_Vx "Object velocity in X direction";
CM_ SG_ 806 RRL_Obj11A_Vy "Object velocity in Y direction";
CM_ SG_ 806 RRL_Obj11A_Ax "Object acceleration in X direction";
CM_ SG_ 807 RRL_Obj11B_CRC "CRC - Autosar E2E Profile 5";
CM_ SG_ 807 RRL_Obj11B_MAC "SecOC MAC (Profile 1)";
CM_ SG_ 807 RRL_Obj11B_AliveCtr "Alive counter - Autosar E2E Profile 5";
CM_ SG_ 807 RRL_Obj11B_BlockCtr "Block-Counter";
CM_ SG_ 807 RRL_Obj11B_ProbMob4PlusWhl "Probability of a mobile object which has 4 or more wheels";
CM_ SG_ 807 RRL_Obj11B_ProbMob2Whl "Probability of a mobile object being 2-wheels vehicle";
CM_ SG_ 807 RRL_Obj11B_ProbMobPed "Probability of a mobile object being a pedestrian";
CM_ SG_ 807 RRL_Obj11B_Prob4PlusWhlCAR "Probability of a mobile object which has 4 or more wheels--passenger car";
CM_ SG_ 807 RRL_Obj11B_Prob4PlusWhlbHGV "Probability of a mobile object which has 4 or more wheels--commercial vehicle(Turck)";
CM_ SG_ 807 RRL_Obj11B_ProbGNDReflex "Probability of the object being a ground reflex";
CM_ SG_ 807 RRL_Obj11B_ProbStatBarrier "Probability of the object being a stationary road barrier";
CM_ SG_ 807 RRL_Obj11B_ProbStatObst "Probability of the object being a stationary obstacle";
CM_ SG_ 807 RRL_Obj11B_MovingProbability "Object has been observed moving over the ground";
CM_ SG_ 807 RRL_Obj11B_MovingObserved "Object has been observed moving over the ground since it was first detected";
CM_ SG_ 807 RRL_Obj11B_FV "SecOC Freshness Value (Profile 1)";
CM_ SG_ 808 RRL_Obj12A_CRC "CRC - Autosar E2E Profile 5";
CM_ SG_ 808 RRL_Obj12A_Ay "Object acceleration in Y direction";
CM_ SG_ 808 RRL_Obj12A_HeadingYawAngle "Object heading yaw angle";
CM_ SG_ 808 RRL_Obj12A_Length "Object Length";
CM_ SG_ 808 RRL_Obj12A_Width "Object Width";
CM_ SG_ 808 RRL_Obj12A_Height "Object Height";
CM_ SG_ 808 RRL_Obj12A_DxVnce "Variance of object position in X direction";
CM_ SG_ 808 RRL_Obj12A_DyVnce "Variance of object position in Y direction";
CM_ SG_ 808 RRL_Obj12A_DzVnce "Variance of object position in Z direction";
CM_ SG_ 808 RRL_Obj12A_AliveCtr "Alive counter - Autosar E2E Profile 5";
CM_ SG_ 808 RRL_Obj12A_VxVnce "Variance of object velocity in X direction";
CM_ SG_ 808 RRL_Obj12A_VyVnce "Variance of object velocity in Y direction";
CM_ SG_ 808 RRL_Obj12A_AxVnce "Variance of object acceleration in X direction";
CM_ SG_ 808 RRL_Obj12A_AyVnce "Variance of object acceleration in Y direction";
CM_ SG_ 808 RRL_Obj12A_RefPosIndex "Reference Position of the detected objects";
CM_ SG_ 808 RRL_Obj12A_DxDyCoVnce "Correlation coefficient of Dx and Dy";
CM_ SG_ 808 RRL_Obj12A_DxVxCoVnce "Correlation coefficient of Dx and Vx";
CM_ SG_ 808 RRL_Obj12A_BlockCtr "Block-Counter";
CM_ SG_ 808 RRL_Obj12A_DyVxCoVnce "Correlation coefficient of Dy and Ax";
CM_ SG_ 808 RRL_Obj12A_DxVyCoVnce "Correlation coefficient of Dx and Vy";
CM_ SG_ 808 RRL_Obj12A_DyVyCoVnce "Correlation coefficient of Dy and Vy";
CM_ SG_ 808 RRL_Obj12A_VxVyCoVnce "Correlation coefficient of Vx and Vy";
CM_ SG_ 808 RRL_Obj12A_DxAxCoVnce "Correlation coefficient of Dx and Ax";
CM_ SG_ 808 RRL_Obj12A_DyAxCoVnce "Correlation coefficient of Dy and Ax";
CM_ SG_ 808 RRL_Obj12A_VxAxCoVnce "Correlation coefficient of Vx and Ax";
CM_ SG_ 808 RRL_Obj12A_ObjectID "Unique Object ID";
CM_ SG_ 808 RRL_Obj12A_VyAxCoVnce "Correlation coefficient of Vy and Ax";
CM_ SG_ 808 RRL_Obj12A_DxAyCoVnce "Correlation coefficient of Dx and Ay";
CM_ SG_ 808 RRL_Obj12A_DyAyCoVnce "Correlation coefficient of Dy and Ay";
CM_ SG_ 808 RRL_Obj12A_VxAyCoVnce "Correlation coefficient of Vx and Ay";
CM_ SG_ 808 RRL_Obj12A_VyAyCoVnce "Correlation coefficient of Vy and Ay";
CM_ SG_ 808 RRL_Obj12A_AxAyCoVnce "Correlation coefficient of Ax and Ay";
CM_ SG_ 808 RRL_Obj12A_Measured "Object is measured or not";
CM_ SG_ 808 RRL_Obj12A_HeadingYawVnce "Variance of Object heading yaw angle";
CM_ SG_ 808 RRL_Obj12A_Dx "Object position in X direction";
CM_ SG_ 808 RRL_Obj12A_LengthVnce "Variance of Object Length";
CM_ SG_ 808 RRL_Obj12A_WidthVnce "Variance of Object Width";
CM_ SG_ 808 RRL_Obj12A_HeightVnce "Variance of Object Height";
CM_ SG_ 808 RRL_Obj12A_ExistProb "Existence probability of object";
CM_ SG_ 808 RRL_Obj12A_ProbObstacle "Probability of the object being an Obstacle";
CM_ SG_ 808 RRL_Obj12A_ProbNonObstacle "Probability of the object being a Non-Obstacle";
CM_ SG_ 808 RRL_Obj12A_ProbMobileObst "Probability of the object being a mobile obstacle";
CM_ SG_ 808 RRL_Obj12A_FV "SecOC Freshness Value (Profile 1)";
CM_ SG_ 808 RRL_Obj12A_MAC "SecOC MAC (Profile 1)";
CM_ SG_ 808 RRL_Obj12A_Dz "Object position in Z direction";
CM_ SG_ 808 RRL_Obj12A_Dy "Object position in Y direction";
CM_ SG_ 808 RRL_Obj12A_Valid "Object is valid or not";
CM_ SG_ 808 RRL_Obj12A_Vx "Object velocity in X direction";
CM_ SG_ 808 RRL_Obj12A_Vy "Object velocity in Y direction";
CM_ SG_ 808 RRL_Obj12A_Ax "Object acceleration in X direction";
CM_ SG_ 809 RRL_Obj12B_CRC "CRC - Autosar E2E Profile 5";
CM_ SG_ 809 RRL_Obj12B_MAC "SecOC MAC (Profile 1)";
CM_ SG_ 809 RRL_Obj12B_AliveCtr "Alive counter - Autosar E2E Profile 5";
CM_ SG_ 809 RRL_Obj12B_BlockCtr "Block-Counter";
CM_ SG_ 809 RRL_Obj12B_ProbMob4PlusWhl "Probability of a mobile object which has 4 or more wheels";
CM_ SG_ 809 RRL_Obj12B_ProbMob2Whl "Probability of a mobile object being 2-wheels vehicle";
CM_ SG_ 809 RRL_Obj12B_ProbMobPed "Probability of a mobile object being a pedestrian";
CM_ SG_ 809 RRL_Obj12B_Prob4PlusWhlCAR "Probability of a mobile object which has 4 or more wheels--passenger car";
CM_ SG_ 809 RRL_Obj12B_Prob4PlusWhlbHGV "Probability of a mobile object which has 4 or more wheels--commercial vehicle(Turck)";
CM_ SG_ 809 RRL_Obj12B_ProbGNDReflex "Probability of the object being a ground reflex";
CM_ SG_ 809 RRL_Obj12B_ProbStatBarrier "Probability of the object being a stationary road barrier";
CM_ SG_ 809 RRL_Obj12B_ProbStatObst "Probability of the object being a stationary obstacle";
CM_ SG_ 809 RRL_Obj12B_MovingProbability "Object has been observed moving over the ground";
CM_ SG_ 809 RRL_Obj12B_MovingObserved "Object has been observed moving over the ground since it was first detected";
CM_ SG_ 809 RRL_Obj12B_FV "SecOC Freshness Value (Profile 1)";
BA_DEF_ BO_  "GenMsgCycleTime" INT 0 65535;
BA_DEF_ BO_  "GenMsgSendType" ENUM  "Event","Cycle";
BA_DEF_ SG_  "GenSigStartValue" FLOAT 0 100000000000;
BA_DEF_ BO_  "CANFD_BRS" ENUM  "0","1";
BA_DEF_  "DBName" STRING ;
BA_DEF_  "BusType" STRING ;
BA_DEF_ BO_  "VFrameFormat" ENUM  "StandardCAN","ExtendedCAN","reserved","reserved","reserved","reserved","reserved","reserved","reserved","reserved","reserved","reserved","reserved","reserved","StandardCAN_FD","ExtendedCAN_FD";
BA_DEF_DEF_  "GenMsgCycleTime" 0;
BA_DEF_DEF_  "GenMsgSendType" "";
BA_DEF_DEF_  "GenSigStartValue" 0;
BA_DEF_DEF_  "CANFD_BRS" "1";
BA_DEF_DEF_  "DBName" "";
BA_DEF_DEF_  "BusType" "";
BA_DEF_DEF_  "VFrameFormat" "StandardCAN";
BA_ "BusType" "CAN FD";
BA_ "DBName" "GWM_RearCorner_Pri_V21";
BA_ "VFrameFormat" BO_ 1791 14;
BA_ "GenMsgCycleTime" BO_ 769 20;
BA_ "GenMsgSendType" BO_ 769 1;
BA_ "VFrameFormat" BO_ 769 14;
BA_ "GenMsgSendType" BO_ 768 0;
BA_ "VFrameFormat" BO_ 768 14;
BA_ "GenMsgSendType" BO_ 784 0;
BA_ "VFrameFormat" BO_ 784 14;
BA_ "GenMsgSendType" BO_ 785 0;
BA_ "VFrameFormat" BO_ 785 14;
BA_ "GenMsgSendType" BO_ 786 0;
BA_ "VFrameFormat" BO_ 786 14;
BA_ "GenMsgSendType" BO_ 787 0;
BA_ "VFrameFormat" BO_ 787 14;
BA_ "GenMsgSendType" BO_ 788 0;
BA_ "VFrameFormat" BO_ 788 14;
BA_ "GenMsgSendType" BO_ 789 0;
BA_ "VFrameFormat" BO_ 789 14;
BA_ "GenMsgSendType" BO_ 790 0;
BA_ "VFrameFormat" BO_ 790 14;
BA_ "GenMsgSendType" BO_ 791 0;
BA_ "VFrameFormat" BO_ 791 14;
BA_ "GenMsgSendType" BO_ 792 0;
BA_ "VFrameFormat" BO_ 792 14;
BA_ "GenMsgSendType" BO_ 793 0;
BA_ "VFrameFormat" BO_ 793 14;
BA_ "GenMsgSendType" BO_ 794 0;
BA_ "VFrameFormat" BO_ 794 14;
BA_ "GenMsgSendType" BO_ 795 0;
BA_ "VFrameFormat" BO_ 795 14;
BA_ "GenMsgSendType" BO_ 796 0;
BA_ "VFrameFormat" BO_ 796 14;
BA_ "GenMsgSendType" BO_ 797 0;
BA_ "VFrameFormat" BO_ 797 14;
BA_ "GenMsgSendType" BO_ 798 0;
BA_ "VFrameFormat" BO_ 798 14;
BA_ "GenMsgSendType" BO_ 799 0;
BA_ "VFrameFormat" BO_ 799 14;
BA_ "GenMsgSendType" BO_ 800 0;
BA_ "VFrameFormat" BO_ 800 14;
BA_ "GenMsgSendType" BO_ 801 0;
BA_ "VFrameFormat" BO_ 801 14;
BA_ "GenMsgSendType" BO_ 802 0;
BA_ "VFrameFormat" BO_ 802 14;
BA_ "GenMsgSendType" BO_ 803 0;
BA_ "VFrameFormat" BO_ 803 14;
BA_ "GenMsgSendType" BO_ 804 0;
BA_ "VFrameFormat" BO_ 804 14;
BA_ "GenMsgSendType" BO_ 805 0;
BA_ "VFrameFormat" BO_ 805 14;
BA_ "GenMsgSendType" BO_ 806 0;
BA_ "VFrameFormat" BO_ 806 14;
BA_ "GenMsgSendType" BO_ 807 0;
BA_ "VFrameFormat" BO_ 807 14;
BA_ "GenMsgSendType" BO_ 808 0;
BA_ "VFrameFormat" BO_ 808 14;
BA_ "GenMsgSendType" BO_ 809 0;
BA_ "VFrameFormat" BO_ 809 14;
BA_ "GenSigStartValue" SG_ 3221225472 RSDS_RiTgt_02_dy 80;
BA_ "GenSigStartValue" SG_ 3221225472 RSDS_RiTgt_02_dx 900;
BA_ "GenSigStartValue" SG_ 3221225472 RSDS_RiTgt_01_dy 80;
BA_ "GenSigStartValue" SG_ 3221225472 RSDS_RiTgt_01_dx 900;
BA_ "GenSigStartValue" SG_ 3221225472 RSDS_MidTgt_02_dy 40;
BA_ "GenSigStartValue" SG_ 3221225472 RSDS_MidTgt_02_dx 900;
BA_ "GenSigStartValue" SG_ 3221225472 RSDS_MidTgt_01_dy 40;
BA_ "GenSigStartValue" SG_ 3221225472 RSDS_MidTgt_01_dx 900;
BA_ "GenSigStartValue" SG_ 769 RSDS_RCW_MidTgt_01_Vy 1;
BA_ "GenSigStartValue" SG_ 769 RSDS_RCW_MidTgt_01_Vx 1;
BA_ "GenSigStartValue" SG_ 769 RSDS_RCTB_MidTgt_02_Vy 1;
BA_ "GenSigStartValue" SG_ 769 RSDS_RCTB_MidTgt_02_Vx 1;
BA_ "GenSigStartValue" SG_ 769 RSDS_RCTA_LeTgt_02_Vy 1;
BA_ "GenSigStartValue" SG_ 769 RSDS_RCTA_LeTgt_02_Vx 1;
BA_ "GenSigStartValue" SG_ 769 RSDS_LCA_LeTgt_01_Vy 1;
BA_ "GenSigStartValue" SG_ 769 RSDS_LCA_LeTgt_01_Vx 1;
BA_ "GenSigStartValue" SG_ 769 RSDS_ObjRelAccelY_Le 512;
BA_ "GenSigStartValue" SG_ 769 RSDS_ObjRelAccelX_Le 512;
BA_ "GenSigStartValue" SG_ 769 RSDS_LeTgt_02_dx 900;
BA_ "GenSigStartValue" SG_ 769 RSDS_LeTgt_01_dx 900;
BA_ "GenSigStartValue" SG_ 769 ObjTTCLe 70;
BA_ "GenSigStartValue" SG_ 769 ObjLgtSpdCurvLe 100;
BA_ "GenSigStartValue" SG_ 769 ObjLgtPosnCurvLe 923;
BA_ "GenSigStartValue" SG_ 769 ObjLatSpdCurvLe 64;
BA_ "GenSigStartValue" SG_ 769 ObjLatPosnCurvLe 128;
BA_ "GenSigStartValue" SG_ 769 LeTarSts 2;
BA_ "GenSigStartValue" SG_ 768 RRL_Hdr_YawAngleUpper 16384;
BA_ "GenSigStartValue" SG_ 768 RRL_Hdr_YawMountAngle 32768;
BA_ "GenSigStartValue" SG_ 768 RRL_Hdr_YawAngleLower 16384;
BA_ "GenSigStartValue" SG_ 768 RRL_Hdr_PitchMountAngle 2048;
BA_ "GenSigStartValue" SG_ 768 RRL_Hdr_PitchAngleLower 2048;
BA_ "GenSigStartValue" SG_ 768 RRL_Hdr_PitchAngleUpper 2048;
BA_ "GenSigStartValue" SG_ 768 RRL_Hdr_RollMountAngle 2048;
BA_ "GenSigStartValue" SG_ 768 RRL_Hdr_MountingPosY 128;
BA_ "GenSigStartValue" SG_ 768 RRL_Hdr_MountingPosX 256;
BA_ "GenSigStartValue" SG_ 784 RRL_Obj00A_Ay 256;
BA_ "GenSigStartValue" SG_ 784 RRL_Obj00A_HeadingYawAngle 256;
BA_ "GenSigStartValue" SG_ 784 RRL_Obj00A_Dx 4096;
BA_ "GenSigStartValue" SG_ 784 RRL_Obj00A_Dz 20;
BA_ "GenSigStartValue" SG_ 784 RRL_Obj00A_Dy 1024;
BA_ "GenSigStartValue" SG_ 784 RRL_Obj00A_Vx 2048;
BA_ "GenSigStartValue" SG_ 784 RRL_Obj00A_Vy 512;
BA_ "GenSigStartValue" SG_ 784 RRL_Obj00A_Ax 512;
BA_ "GenSigStartValue" SG_ 786 RRL_Obj01A_Ay 256;
BA_ "GenSigStartValue" SG_ 786 RRL_Obj01A_HeadingYawAngle 256;
BA_ "GenSigStartValue" SG_ 786 RRL_Obj01A_Dx 4096;
BA_ "GenSigStartValue" SG_ 786 RRL_Obj01A_Dz 20;
BA_ "GenSigStartValue" SG_ 786 RRL_Obj01A_Dy 1024;
BA_ "GenSigStartValue" SG_ 786 RRL_Obj01A_Vx 2048;
BA_ "GenSigStartValue" SG_ 786 RRL_Obj01A_Vy 512;
BA_ "GenSigStartValue" SG_ 786 RRL_Obj01A_Ax 512;
BA_ "GenSigStartValue" SG_ 788 RRL_Obj02A_Ay 256;
BA_ "GenSigStartValue" SG_ 788 RRL_Obj02A_HeadingYawAngle 256;
BA_ "GenSigStartValue" SG_ 788 RRL_Obj02A_Dx 4096;
BA_ "GenSigStartValue" SG_ 788 RRL_Obj02A_Dz 20;
BA_ "GenSigStartValue" SG_ 788 RRL_Obj02A_Dy 1024;
BA_ "GenSigStartValue" SG_ 788 RRL_Obj02A_Vx 2048;
BA_ "GenSigStartValue" SG_ 788 RRL_Obj02A_Vy 512;
BA_ "GenSigStartValue" SG_ 788 RRL_Obj02A_Ax 512;
BA_ "GenSigStartValue" SG_ 790 RRL_Obj03A_Ay 256;
BA_ "GenSigStartValue" SG_ 790 RRL_Obj03A_HeadingYawAngle 256;
BA_ "GenSigStartValue" SG_ 790 RRL_Obj03A_Dx 4096;
BA_ "GenSigStartValue" SG_ 790 RRL_Obj03A_Dz 20;
BA_ "GenSigStartValue" SG_ 790 RRL_Obj03A_Dy 1024;
BA_ "GenSigStartValue" SG_ 790 RRL_Obj03A_Vx 2048;
BA_ "GenSigStartValue" SG_ 790 RRL_Obj03A_Vy 512;
BA_ "GenSigStartValue" SG_ 790 RRL_Obj03A_Ax 512;
BA_ "GenSigStartValue" SG_ 792 RRL_Obj04A_Ay 256;
BA_ "GenSigStartValue" SG_ 792 RRL_Obj04A_HeadingYawAngle 256;
BA_ "GenSigStartValue" SG_ 792 RRL_Obj04A_Dx 4096;
BA_ "GenSigStartValue" SG_ 792 RRL_Obj04A_Dz 20;
BA_ "GenSigStartValue" SG_ 792 RRL_Obj04A_Dy 1024;
BA_ "GenSigStartValue" SG_ 792 RRL_Obj04A_Vx 2048;
BA_ "GenSigStartValue" SG_ 792 RRL_Obj04A_Vy 512;
BA_ "GenSigStartValue" SG_ 792 RRL_Obj04A_Ax 512;
BA_ "GenSigStartValue" SG_ 794 RRL_Obj05A_Ay 256;
BA_ "GenSigStartValue" SG_ 794 RRL_Obj05A_HeadingYawAngle 256;
BA_ "GenSigStartValue" SG_ 794 RRL_Obj05A_Dx 4096;
BA_ "GenSigStartValue" SG_ 794 RRL_Obj05A_Dz 20;
BA_ "GenSigStartValue" SG_ 794 RRL_Obj05A_Dy 1024;
BA_ "GenSigStartValue" SG_ 794 RRL_Obj05A_Vx 2048;
BA_ "GenSigStartValue" SG_ 794 RRL_Obj05A_Vy 512;
BA_ "GenSigStartValue" SG_ 794 RRL_Obj05A_Ax 512;
BA_ "GenSigStartValue" SG_ 796 RRL_Obj06A_Ay 256;
BA_ "GenSigStartValue" SG_ 796 RRL_Obj06A_HeadingYawAngle 256;
BA_ "GenSigStartValue" SG_ 796 RRL_Obj06A_Dx 4096;
BA_ "GenSigStartValue" SG_ 796 RRL_Obj06A_Dz 20;
BA_ "GenSigStartValue" SG_ 796 RRL_Obj06A_Dy 1024;
BA_ "GenSigStartValue" SG_ 796 RRL_Obj06A_Vx 2048;
BA_ "GenSigStartValue" SG_ 796 RRL_Obj06A_Vy 512;
BA_ "GenSigStartValue" SG_ 796 RRL_Obj06A_Ax 512;
BA_ "GenSigStartValue" SG_ 798 RRL_Obj07A_Ay 256;
BA_ "GenSigStartValue" SG_ 798 RRL_Obj07A_HeadingYawAngle 256;
BA_ "GenSigStartValue" SG_ 798 RRL_Obj07A_Dx 4096;
BA_ "GenSigStartValue" SG_ 798 RRL_Obj07A_Dz 20;
BA_ "GenSigStartValue" SG_ 798 RRL_Obj07A_Dy 1024;
BA_ "GenSigStartValue" SG_ 798 RRL_Obj07A_Vx 2048;
BA_ "GenSigStartValue" SG_ 798 RRL_Obj07A_Vy 512;
BA_ "GenSigStartValue" SG_ 798 RRL_Obj07A_Ax 512;
BA_ "GenSigStartValue" SG_ 800 RRL_Obj08A_Ay 256;
BA_ "GenSigStartValue" SG_ 800 RRL_Obj08A_HeadingYawAngle 256;
BA_ "GenSigStartValue" SG_ 800 RRL_Obj08A_Dx 4096;
BA_ "GenSigStartValue" SG_ 800 RRL_Obj08A_Dz 20;
BA_ "GenSigStartValue" SG_ 800 RRL_Obj08A_Dy 1024;
BA_ "GenSigStartValue" SG_ 800 RRL_Obj08A_Vx 2048;
BA_ "GenSigStartValue" SG_ 800 RRL_Obj08A_Vy 512;
BA_ "GenSigStartValue" SG_ 800 RRL_Obj08A_Ax 512;
BA_ "GenSigStartValue" SG_ 802 RRL_Obj09A_Ay 256;
BA_ "GenSigStartValue" SG_ 802 RRL_Obj09A_HeadingYawAngle 256;
BA_ "GenSigStartValue" SG_ 802 RRL_Obj09A_Dx 4096;
BA_ "GenSigStartValue" SG_ 802 RRL_Obj09A_Dz 20;
BA_ "GenSigStartValue" SG_ 802 RRL_Obj09A_Dy 1024;
BA_ "GenSigStartValue" SG_ 802 RRL_Obj09A_Vx 2048;
BA_ "GenSigStartValue" SG_ 802 RRL_Obj09A_Vy 512;
BA_ "GenSigStartValue" SG_ 802 RRL_Obj09A_Ax 512;
BA_ "GenSigStartValue" SG_ 804 RRL_Obj10A_Ay 256;
BA_ "GenSigStartValue" SG_ 804 RRL_Obj10A_HeadingYawAngle 256;
BA_ "GenSigStartValue" SG_ 804 RRL_Obj10A_Dx 4096;
BA_ "GenSigStartValue" SG_ 804 RRL_Obj10A_Dz 20;
BA_ "GenSigStartValue" SG_ 804 RRL_Obj10A_Dy 1024;
BA_ "GenSigStartValue" SG_ 804 RRL_Obj10A_Vx 2048;
BA_ "GenSigStartValue" SG_ 804 RRL_Obj10A_Vy 512;
BA_ "GenSigStartValue" SG_ 804 RRL_Obj10A_Ax 512;
BA_ "GenSigStartValue" SG_ 806 RRL_Obj11A_Ay 256;
BA_ "GenSigStartValue" SG_ 806 RRL_Obj11A_HeadingYawAngle 256;
BA_ "GenSigStartValue" SG_ 806 RRL_Obj11A_Dx 4096;
BA_ "GenSigStartValue" SG_ 806 RRL_Obj11A_Dz 20;
BA_ "GenSigStartValue" SG_ 806 RRL_Obj11A_Dy 1024;
BA_ "GenSigStartValue" SG_ 806 RRL_Obj11A_Vx 2048;
BA_ "GenSigStartValue" SG_ 806 RRL_Obj11A_Vy 512;
BA_ "GenSigStartValue" SG_ 806 RRL_Obj11A_Ax 512;
BA_ "GenSigStartValue" SG_ 808 RRL_Obj12A_Ay 256;
BA_ "GenSigStartValue" SG_ 808 RRL_Obj12A_HeadingYawAngle 256;
BA_ "GenSigStartValue" SG_ 808 RRL_Obj12A_Dx 4096;
BA_ "GenSigStartValue" SG_ 808 RRL_Obj12A_Dz 20;
BA_ "GenSigStartValue" SG_ 808 RRL_Obj12A_Dy 1024;
BA_ "GenSigStartValue" SG_ 808 RRL_Obj12A_Vx 2048;
BA_ "GenSigStartValue" SG_ 808 RRL_Obj12A_Vy 512;
BA_ "GenSigStartValue" SG_ 808 RRL_Obj12A_Ax 512;
VAL_ 3221225472 RSDS_RiTgt_02 1 "target detected" 0 "No target" ;
VAL_ 3221225472 RSDS_RiTgt_01 1 "target detected" 0 "No target" ;
VAL_ 3221225472 RSDS_MidTgt_02 1 "target detected" 0 "No target" ;
VAL_ 3221225472 RSDS_MidTgt_01 1 "target detected" 0 "No target" ;
VAL_ 769 RSDS_MidTgt_01_L 1 "target detected" 0 "No target" ;
VAL_ 769 RCTB_L_State 6 " Reserved " 5 " Fault " 4 " Passive " 3 " Active " 2 " Standby " 1 " OFF " 0 " Initial_value " ;
VAL_ 769 RCTA_L_State 6 " Reserved " 5 " Fault " 4 " Passive " 3 " Active " 2 " Standby " 1 " OFF " 0 " Initial_value " ;
VAL_ 769 RCW_L_State 6 " Reserved " 5 " Fault " 4 " Passive " 3 " Active " 2 " Standby " 1 " OFF " 0 " Initial_value " ;
VAL_ 769 DOW_L_State 6 " Reserved " 5 " Fault " 4 " Passive " 3 " Active " 2 " Standby " 1 " OFF " 0 " Initial_value " ;
VAL_ 769 LCA_L_State 6 " Reserved " 5 " Fault " 4 " Passive " 3 " Active " 2 " Standby " 1 " OFF " 0 " Initial_value " ;
VAL_ 769 BSD_L_State 6 " Reserved " 5 " Fault " 4 " Passive " 3 " Active " 2 " Standby " 1 " OFF " 0 " Initial_value " ;
VAL_ 769 RSDS_LeTgt_02 1 "target detected" 0 "No target" ;
VAL_ 769 RSDS_LeTgt_01 1 "target detected" 0 "No target" ;
VAL_ 769 ZoneIndLe 3 "Object in the Shared Zone" 2 "Object in CVW Zone" 1 "Object in BSW Zone" 0 "No Object in the Zone" ;
VAL_ 769 ObjStsLe 3 "Coasted" 2 "Mature" 1 "New" 0 "Invalid" ;
VAL_ 769 ObjStatyLe 1 "Not Stationary" 0 "Stationary" ;
VAL_ 769 LeTarSts 3 "Reserved" 2 "No Target" 0 "Target Invalid" 1 "Target Valid" ;
VAL_ 768 RRL_Hdr_ElevOutOfSpec 0 "In Spec Elevation Alignment" 1 "Out of spec Elevation Alignement" ;
VAL_ 768 RRL_Hdr_SensorState 0 "SENSOR FULLY OPERATIONAL" 1 "HW MALFUNCTION" 2 "DSP ISSUES" 3 "COMMUNICATION ERRORS" 4 "MISALIGNMENT (OUT OF SPEC)" 5 "SENSOR BLIDNESS DETECTED" 6 "SENSOR DISTUBED" 7 "OTHER ISSUES" 8 "RESERVED1" 9 "RESERVED2" 10 "RESERVED3" 11 "RESERVED4" 12 "RESERVED5" 13 "RESERVED6" 14 "RESERVED7" 15 "INVALID" ;
VAL_ 768 RRL_Hdr_TimeSyncFailure 0 "TIMESYNC_NO_FAILURE" 1 "TIMESYNC_FAILURE" ;
VAL_ 768 RRL_Hdr_ObjectDownSel 0 "no downselection" 1 "downselected" ;
VAL_ 768 RRL_Hdr_AziOutOfSpec 0 "In spec Azimuth Alignemdn" 1 "Out of spec Azimuth Alignement" ;
VAL_ 784 RRL_Obj00A_RefPosIndex 0 "Front corner left" 1 "Front center" 2 "Front corner right" 3 "Front wheelcase left" 4 "Front wheelcase right" 5 "Side middle left" 6 "Side middle right" 7 "Rear wheelcase left" 8 "Rear wheelcase right" 9 "Rear corner left" 10 "Rear center" 11 "Rear corner right" 12 "Object center" 13 "Rear wheelcase center" 14 "Front wheelcase center" 15 "Invalid" ;
VAL_ 784 RRL_Obj00A_Measured 0 "not measured" 1 "measured" ;
VAL_ 784 RRL_Obj00A_Valid 0 "not valid" 1 "valid" ;
VAL_ 786 RRL_Obj01A_RefPosIndex 0 "Front corner left" 1 "Front center" 2 "Front corner right" 3 "Front wheelcase left" 4 "Front wheelcase right" 5 "Side middle left" 6 "Side middle right" 7 "Rear wheelcase left" 8 "Rear wheelcase right" 9 "Rear corner left" 10 "Rear center" 11 "Rear corner right" 12 "Object center" 13 "Rear wheelcase center" 14 "Front wheelcase center" 15 "Invalid" ;
VAL_ 786 RRL_Obj01A_Measured 0 "not measured" 1 "measured" ;
VAL_ 786 RRL_Obj01A_Valid 0 "not valid" 1 "valid" ;
VAL_ 788 RRL_Obj02A_RefPosIndex 0 "Front corner left" 1 "Front center" 2 "Front corner right" 3 "Front wheelcase left" 4 "Front wheelcase right" 5 "Side middle left" 6 "Side middle right" 7 "Rear wheelcase left" 8 "Rear wheelcase right" 9 "Rear corner left" 10 "Rear center" 11 "Rear corner right" 12 "Object center" 13 "Rear wheelcase center" 14 "Front wheelcase center" 15 "Invalid" ;
VAL_ 788 RRL_Obj02A_Measured 0 "not measured" 1 "measured" ;
VAL_ 788 RRL_Obj02A_Valid 0 "not valid" 1 "valid" ;
VAL_ 790 RRL_Obj03A_RefPosIndex 0 "Front corner left" 1 "Front center" 2 "Front corner right" 3 "Front wheelcase left" 4 "Front wheelcase right" 5 "Side middle left" 6 "Side middle right" 7 "Rear wheelcase left" 8 "Rear wheelcase right" 9 "Rear corner left" 10 "Rear center" 11 "Rear corner right" 12 "Object center" 13 "Rear wheelcase center" 14 "Front wheelcase center" 15 "Invalid" ;
VAL_ 790 RRL_Obj03A_Measured 0 "not measured" 1 "measured" ;
VAL_ 790 RRL_Obj03A_Valid 0 "not valid" 1 "valid" ;
VAL_ 792 RRL_Obj04A_RefPosIndex 0 "Front corner left" 1 "Front center" 2 "Front corner right" 3 "Front wheelcase left" 4 "Front wheelcase right" 5 "Side middle left" 6 "Side middle right" 7 "Rear wheelcase left" 8 "Rear wheelcase right" 9 "Rear corner left" 10 "Rear center" 11 "Rear corner right" 12 "Object center" 13 "Rear wheelcase center" 14 "Front wheelcase center" 15 "Invalid" ;
VAL_ 792 RRL_Obj04A_Measured 0 "not measured" 1 "measured" ;
VAL_ 792 RRL_Obj04A_Valid 0 "not valid" 1 "valid" ;
VAL_ 794 RRL_Obj05A_RefPosIndex 0 "Front corner left" 1 "Front center" 2 "Front corner right" 3 "Front wheelcase left" 4 "Front wheelcase right" 5 "Side middle left" 6 "Side middle right" 7 "Rear wheelcase left" 8 "Rear wheelcase right" 9 "Rear corner left" 10 "Rear center" 11 "Rear corner right" 12 "Object center" 13 "Rear wheelcase center" 14 "Front wheelcase center" 15 "Invalid" ;
VAL_ 794 RRL_Obj05A_Measured 0 "not measured" 1 "measured" ;
VAL_ 794 RRL_Obj05A_Valid 0 "not valid" 1 "valid" ;
VAL_ 796 RRL_Obj06A_RefPosIndex 0 "Front corner left" 1 "Front center" 2 "Front corner right" 3 "Front wheelcase left" 4 "Front wheelcase right" 5 "Side middle left" 6 "Side middle right" 7 "Rear wheelcase left" 8 "Rear wheelcase right" 9 "Rear corner left" 10 "Rear center" 11 "Rear corner right" 12 "Object center" 13 "Rear wheelcase center" 14 "Front wheelcase center" 15 "Invalid" ;
VAL_ 796 RRL_Obj06A_Measured 0 "not measured" 1 "measured" ;
VAL_ 796 RRL_Obj06A_Valid 0 "not valid" 1 "valid" ;
VAL_ 798 RRL_Obj07A_RefPosIndex 0 "Front corner left" 1 "Front center" 2 "Front corner right" 3 "Front wheelcase left" 4 "Front wheelcase right" 5 "Side middle left" 6 "Side middle right" 7 "Rear wheelcase left" 8 "Rear wheelcase right" 9 "Rear corner left" 10 "Rear center" 11 "Rear corner right" 12 "Object center" 13 "Rear wheelcase center" 14 "Front wheelcase center" 15 "Invalid" ;
VAL_ 798 RRL_Obj07A_Measured 0 "not measured" 1 "measured" ;
VAL_ 798 RRL_Obj07A_Valid 0 "not valid" 1 "valid" ;
VAL_ 800 RRL_Obj08A_RefPosIndex 0 "Front corner left" 1 "Front center" 2 "Front corner right" 3 "Front wheelcase left" 4 "Front wheelcase right" 5 "Side middle left" 6 "Side middle right" 7 "Rear wheelcase left" 8 "Rear wheelcase right" 9 "Rear corner left" 10 "Rear center" 11 "Rear corner right" 12 "Object center" 13 "Rear wheelcase center" 14 "Front wheelcase center" 15 "Invalid" ;
VAL_ 800 RRL_Obj08A_Measured 0 "not measured" 1 "measured" ;
VAL_ 800 RRL_Obj08A_Valid 0 "not valid" 1 "valid" ;
VAL_ 802 RRL_Obj09A_RefPosIndex 0 "Front corner left" 1 "Front center" 2 "Front corner right" 3 "Front wheelcase left" 4 "Front wheelcase right" 5 "Side middle left" 6 "Side middle right" 7 "Rear wheelcase left" 8 "Rear wheelcase right" 9 "Rear corner left" 10 "Rear center" 11 "Rear corner right" 12 "Object center" 13 "Rear wheelcase center" 14 "Front wheelcase center" 15 "Invalid" ;
VAL_ 802 RRL_Obj09A_Measured 0 "not measured" 1 "measured" ;
VAL_ 802 RRL_Obj09A_Valid 0 "not valid" 1 "valid" ;
VAL_ 804 RRL_Obj10A_RefPosIndex 0 "Front corner left" 1 "Front center" 2 "Front corner right" 3 "Front wheelcase left" 4 "Front wheelcase right" 5 "Side middle left" 6 "Side middle right" 7 "Rear wheelcase left" 8 "Rear wheelcase right" 9 "Rear corner left" 10 "Rear center" 11 "Rear corner right" 12 "Object center" 13 "Rear wheelcase center" 14 "Front wheelcase center" 15 "Invalid" ;
VAL_ 804 RRL_Obj10A_Measured 0 "not measured" 1 "measured" ;
VAL_ 804 RRL_Obj10A_Valid 0 "not valid" 1 "valid" ;
VAL_ 806 RRL_Obj11A_RefPosIndex 0 "Front corner left" 1 "Front center" 2 "Front corner right" 3 "Front wheelcase left" 4 "Front wheelcase right" 5 "Side middle left" 6 "Side middle right" 7 "Rear wheelcase left" 8 "Rear wheelcase right" 9 "Rear corner left" 10 "Rear center" 11 "Rear corner right" 12 "Object center" 13 "Rear wheelcase center" 14 "Front wheelcase center" 15 "Invalid" ;
VAL_ 806 RRL_Obj11A_Measured 0 "not measured" 1 "measured" ;
VAL_ 806 RRL_Obj11A_Valid 0 "not valid" 1 "valid" ;
VAL_ 808 RRL_Obj12A_RefPosIndex 0 "Front corner left" 1 "Front center" 2 "Front corner right" 3 "Front wheelcase left" 4 "Front wheelcase right" 5 "Side middle left" 6 "Side middle right" 7 "Rear wheelcase left" 8 "Rear wheelcase right" 9 "Rear corner left" 10 "Rear center" 11 "Rear corner right" 12 "Object center" 13 "Rear wheelcase center" 14 "Front wheelcase center" 15 "Invalid" ;
VAL_ 808 RRL_Obj12A_Measured 0 "not measured" 1 "measured" ;
VAL_ 808 RRL_Obj12A_Valid 0 "not valid" 1 "valid" ;
